VERSION ""

NS_ :

BS_:

BU_: TM

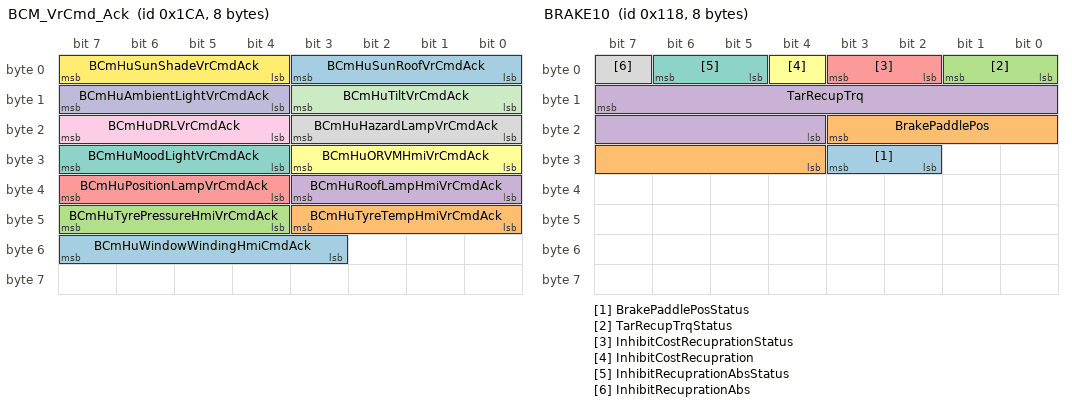
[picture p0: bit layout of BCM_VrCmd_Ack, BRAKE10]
BO_ 458 BCM_VrCmd_Ack: 8 Vector__XXX
 SG_ BCmHuWindowWindingHmiCmdAck : 55|5@0+ (1,0) [0|31] ""  TM
 SG_ BCmHuTyreTempHmiVrCmdAck : 43|4@0+ (1,0) [0|15] ""  TM
 SG_ BCmHuTyrePressureHmiVrCmdAck : 47|4@0+ (1,0) [0|15] ""  TM
 SG_ BCmHuRoofLampHmiVrCmdAck : 35|4@0+ (1,0) [0|15] ""  TM
 SG_ BCmHuPositionLampVrCmdAck : 39|4@0+ (1,0) [0|15] ""  TM
 SG_ BCmHuORVMHmiVrCmdAck : 27|4@0+ (1,0) [0|15] ""  TM
 SG_ BCmHuMoodLightVrCmdAck : 31|4@0+ (1,0) [0|15] ""  TM
 SG_ BCmHuHazardLampVrCmdAck : 19|4@0+ (1,0) [0|15] ""  TM
 SG_ BCmHuDRLVrCmdAck : 23|4@0+ (1,0) [0|15] ""  TM
 SG_ BCmHuAmbientLightVrCmdAck : 15|4@0+ (1,0) [0|15] ""  TM
 SG_ BCmHuTiltVrCmdAck : 11|4@0+ (1,0) [0|15] ""  TM
 SG_ BCmHuSunShadeVrCmdAck : 7|4@0+ (1,0) [0|15] ""  TM
 SG_ BCmHuSunRoofVrCmdAck : 3|4@0+ (1,0) [0|15] ""  TM

BO_ 2019 VCU_DiagRequest: 8 Vector__XXX
 SG_ VCU_DiagRequest : 7|64@0+ (1,0) [0|0] ""  TM

BO_ 2027 VCU_DiagResponse_USDT: 8 Vector__XXX
 SG_ VCU_DiagResponse_USDT : 7|64@0+ (1,0) [0|0] ""  TM

BO_ 567 BRAKE11_RC: 8 Vector__XXX
 SG_ MRC_3 : 51|4@0+ (1,0) [0|15] ""  TM
 SG_ CRC_3 : 63|8@0+ (1,0) [0|255] ""  TM
 SG_ ApbState_Old : 2|3@0+ (1,0) [0|7] ""  TM
 SG_ BrkPaddleTravel2Status : 26|2@0+ (1,0) [0|3] ""  TM
 SG_ BrkPaddleTravel2 : 24|9@0+ (0.01,0) [0|5] "volts"  TM
 SG_ MCMsAvailability : 12|1@0+ (1,0) [0|1] ""  TM
 SG_ BrkPaddleTravel1Status : 54|2@0+ (1,0) [0|3] ""  TM
 SG_ BrkPaddleTravel1 : 47|9@0+ (0.01,0) [0|5] "volts"  TM
 SG_ MCMsErrorState : 10|1@0+ (1,0) [0|1] ""  TM
 SG_ MCMsActive : 11|1@0+ (1,0) [0|1] ""  TM
 SG_ APbBeepState : 29|3@0+ (1,0) [0|7] ""  TM
 SG_ AVhStatus : 15|1@0+ (1,0) [0|1] ""  TM
 SG_ AVhState : 7|2@0+ (1,0) [0|3] ""  TM
 SG_ AVhAvailability : 14|1@0+ (1,0) [0|1] ""  TM
 SG_ APbState : 17|4@0+ (1,0) [0|15] ""  TM
 SG_ APbErrorState : 4|2@0+ (1,0) [0|3] ""  TM
 SG_ APbAvailability : 5|1@0+ (1,0) [0|1] ""  TM

BO_ 1397 FATC_to_BET: 8 Vector__XXX
 SG_ BET_Response : 7|64@0+ (1,0) [0|0] ""  TM

BO_ 1396 BET_to_FATC: 8 Vector__XXX
 SG_ BET_Request : 7|64@0+ (1,0) [0|0] ""  TM

BO_ 1395 FATC_to_VTOOL: 8 Vector__XXX
 SG_ Validation_Mode_Res : 7|64@0+ (1,0) [0|0] ""  TM

BO_ 1394 VTOOL_to_FATC: 8 Vector__XXX
 SG_ Validation_Mode_Req : 7|64@0+ (1,0) [0|0] ""  TM

BO_ 1393 FATC_to_XCP: 8 Vector__XXX
 SG_ XCP_DTO : 7|64@0+ (1,0) [0|0] ""  TM

BO_ 1392 XCP_to_FATC: 8 Vector__XXX
 SG_ XCP_CRO : 7|64@0+ (1,0) [0|0] ""  TM

BO_ 280 BRAKE10: 8 Vector__XXX
 SG_ BrakePaddlePosStatus : 27|2@0+ (1,0) [0|3] ""  TM
 SG_ BrakePaddlePos : 19|8@0+ (0.5,0) [0|100] "%"  TM
 SG_ TarRecupTrqStatus : 1|2@0+ (1,0) [0|3] ""  TM
 SG_ TarRecupTrq : 15|12@0+ (0.1,0) [0|250] ""  TM
 SG_ InhibitCostRecuprationStatus : 3|2@0+ (1,0) [0|3] ""  TM
 SG_ InhibitCostRecupration : 4|1@0+ (1,0) [0|1] ""  TM
 SG_ InhibitRecuprationAbsStatus : 6|2@0+ (1,0) [0|3] ""  TM
 SG_ InhibitRecuprationAbs : 7|1@0+ (1,0) [0|1] ""  TM

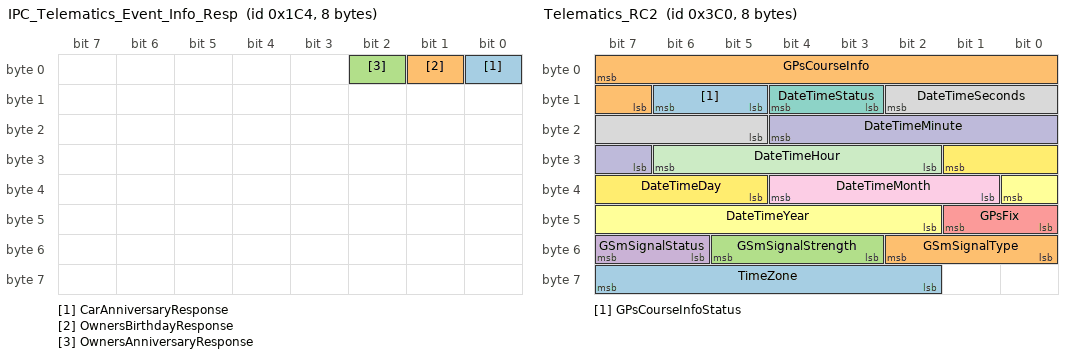
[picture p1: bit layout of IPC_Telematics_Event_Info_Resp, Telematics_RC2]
BO_ 452 IPC_Telematics_Event_Info_Resp: 8 Vector__XXX
 SG_ CarAnniversaryResponse : 0|1@0+ (1,0) [0|1] ""  TM
 SG_ OwnersBirthdayResponse : 1|1@0+ (1,0) [0|1] ""  TM
 SG_ OwnersAnniversaryResponse : 2|1@0+ (1,0) [0|1] ""  TM

BO_ 962 Telematics_GPSinfo_RC2: 8 TM
 SG_ GPsInfoY : 39|32@0+ (1E-007,-90) [-90|90] "deg" Vector__XXX
 SG_ GPsInfoX : 7|32@0+ (1E-007,-180) [-180|180] "deg" Vector__XXX

BO_ 963 Telematics_GPSinfo_RC7: 8 TM
 SG_ GPsInfoXYZStatus : 33|2@0+ (1,0) [0|3] "" Vector__XXX
 SG_ GPsInfoZ : 7|32@0+ (1,-10000000) [-10000000|10000000] "cm" Vector__XXX

BO_ 960 Telematics_RC2: 8 TM
 SG_ TimeZone : 63|6@0+ (1,0) [0|63] "" Vector__XXX
 SG_ GSmSignalType : 50|3@0+ (1,0) [0|7] "" Vector__XXX
 SG_ GSmSignalStrength : 53|3@0+ (1,0) [0|7] "" Vector__XXX
 SG_ GSmSignalStatus : 55|2@0+ (1,0) [0|3] "" Vector__XXX
 SG_ GPsFix : 41|2@0+ (1,0) [0|3] "" Vector__XXX
 SG_ DateTimeYear : 32|7@0+ (1,0) [0|99] "" Vector__XXX
 SG_ DateTimeStatus : 12|2@0+ (1,0) [0|3] "" Vector__XXX
 SG_ DateTimeSeconds : 10|6@0+ (1,0) [0|59] "" Vector__XXX
 SG_ DateTimeMonth : 36|4@0+ (1,0) [0|12] "" Vector__XXX
 SG_ DateTimeMinute : 20|6@0+ (1,0) [0|59] "" Vector__XXX
 SG_ DateTimeHour : 30|5@0+ (1,0) [0|24] "" Vector__XXX
 SG_ DateTimeDay : 25|5@0+ (1,0) [0|31] "" Vector__XXX
 SG_ GPsCourseInfoStatus : 14|2@0+ (1,0) [0|3] "" Vector__XXX
 SG_ GPsCourseInfo : 7|9@0+ (1,0) [0|360] "" Vector__XXX

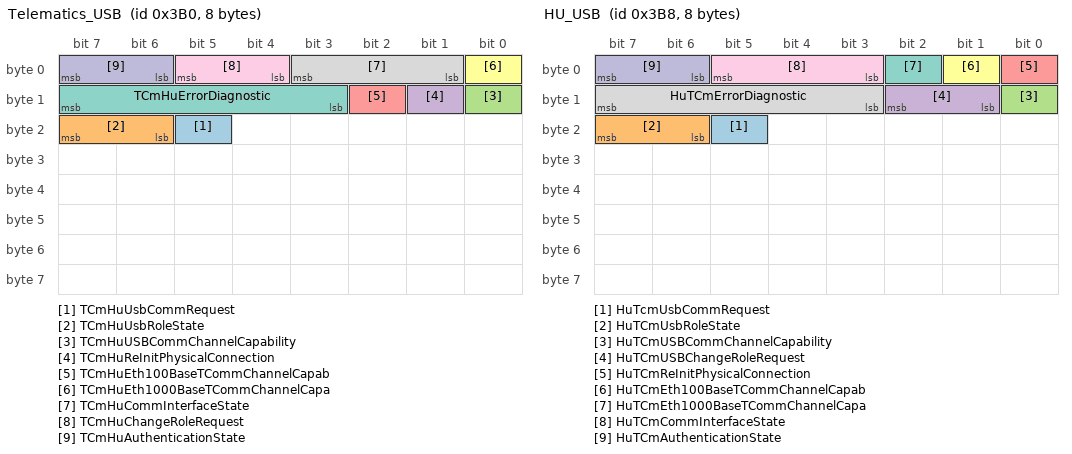
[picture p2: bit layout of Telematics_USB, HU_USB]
BO_ 944 Telematics_USB: 8 TM
 SG_ TCmHuUsbCommRequest : 21|1@0+ (1,0) [0|1] "" Vector__XXX
 SG_ TCmHuUsbRoleState : 23|2@0+ (1,0) [0|3] "" Vector__XXX
 SG_ TCmHuUSBCommChannelCapability : 8|1@0+ (1,0) [0|1] "" Vector__XXX
 SG_ TCmHuReInitPhysicalConnection : 9|1@0+ (1,0) [0|1] "" Vector__XXX
 SG_ TCmHuEth100BaseTCommChannelCapab : 10|1@0+ (1,0) [0|1] "" Vector__XXX
 SG_ TCmHuEth1000BaseTCommChannelCapa : 0|1@0+ (1,0) [0|1] "" Vector__XXX
 SG_ TCmHuErrorDiagnostic : 15|5@0+ (1,0) [0|31] "" Vector__XXX
 SG_ TCmHuCommInterfaceState : 3|3@0+ (1,0) [0|7] "" Vector__XXX
 SG_ TCmHuChangeRoleRequest : 5|2@0+ (1,0) [0|3] "" Vector__XXX
 SG_ TCmHuAuthenticationState : 7|2@0+ (1,0) [0|3] "" Vector__XXX

BO_ 952 HU_USB: 8 Vector__XXX
 SG_ HuTcmUsbCommRequest : 21|1@0+ (1,0) [0|1] ""  TM
 SG_ HuTCmUsbRoleState : 23|2@0+ (1,0) [0|3] ""  TM
 SG_ HuTCmUSBCommChannelCapability : 8|1@0+ (1,0) [0|1] ""  TM
 SG_ HuTCmUSBChangeRoleRequest : 10|2@0+ (1,0) [0|3] ""  TM
 SG_ HuTCmReInitPhysicalConnection : 0|1@0+ (1,0) [0|1] ""  TM
 SG_ HuTCmEth100BaseTCommChannelCapab : 1|1@0+ (1,0) [0|1] ""  TM
 SG_ HuTCmEth1000BaseTCommChannelCapa : 2|1@0+ (1,0) [0|1] ""  TM
 SG_ HuTCmErrorDiagnostic : 15|5@0+ (1,0) [0|31] ""  TM
 SG_ HuTCmCommInterfaceState : 5|3@0+ (1,0) [0|7] ""  TM
 SG_ HuTCmAuthenticationState : 7|2@0+ (1,0) [0|3] ""  TM

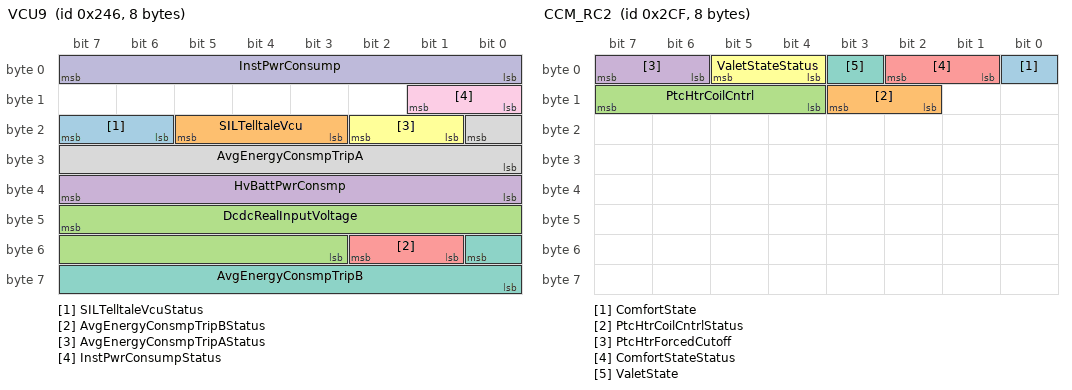
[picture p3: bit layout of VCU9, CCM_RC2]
BO_ 582 VCU9: 8 Vector__XXX
 SG_ SILTelltaleVcuStatus : 23|2@0+ (1,0) [0|3] ""  TM
 SG_ SILTelltaleVcu : 21|3@0+ (1,0) [0|7] ""  TM
 SG_ DcdcRealInputVoltage : 47|13@0+ (0.1,0) [0|819.1] "V"  TM
 SG_ HvBattPwrConsmp : 39|8@0+ (1,0) [0|250] "KwHr"  TM
 SG_ AvgEnergyConsmpTripBStatus : 50|2@0+ (1,0) [0|3] ""  TM
 SG_ AvgEnergyConsmpTripAStatus : 18|2@0+ (1,0) [0|3] ""  TM
 SG_ AvgEnergyConsmpTripB : 48|9@0+ (1,0) [0|511] "kwH/Km"  TM
 SG_ AvgEnergyConsmpTripA : 16|9@0+ (1,0) [0|511] "kwH/Km"  TM
 SG_ InstPwrConsumpStatus : 9|2@0+ (1,0) [0|3] ""  TM
 SG_ InstPwrConsump : 7|8@0+ (1,-100) [-100|100] "%"  TM

BO_ 1630 TPMS_DiagResponse_UUDT: 8 Vector__XXX
 SG_ TPMS_DiagResponse_UUDT : 7|64@0+ (1,0) [0|0] ""  TM

BO_ 1886 TPMS_DiagResponse_USDT: 8 Vector__XXX
 SG_ TPMS_DiagResponse_USDT : 7|64@0+ (1,0) [0|0] ""  TM

BO_ 1878 TPMS_DiagRequest: 8 Vector__XXX
 SG_ TPMS_DiagRequest : 7|64@0+ (1,0) [0|0] ""  TM

BO_ 1289 ESP_NMPDU: 8 Vector__XXX
 SG_ PreviousState_ESP : 19|3@0+ (1,0) [0|7] ""  TM
 SG_ Reserved63 : 20|1@0+ (1,0) [0|1] ""  TM
 SG_ Reserved62 : 21|1@0+ (1,0) [0|1] ""  TM
 SG_ Reserved61 : 22|1@0+ (1,0) [0|1] ""  TM
 SG_ Reserved60 : 23|1@0+ (1,0) [0|1] ""  TM
 SG_ Reserved59 : 9|1@0+ (1,0) [0|1] ""  TM
 SG_ Reserved58 : 10|1@0+ (1,0) [0|1] ""  TM
 SG_ Reserved57 : 13|1@0+ (1,0) [0|1] ""  TM
 SG_ Reserved56 : 15|1@0+ (1,0) [0|1] ""  TM
 SG_ RepeatMessageReq_ESP : 8|1@0+ (1,0) [0|1] ""  TM
 SG_ PartialNetworkInformation_ESP : 14|1@0+ (1,0) [0|1] ""  TM
 SG_ NMCoOrdSlpReady_ESP : 11|1@0+ (1,0) [0|1] ""  TM
 SG_ ESP_NMPDU_USER_DATA_D5 : 63|8@0+ (1,0) [0|255] ""  TM
 SG_ ESP_NMPDU_USER_DATA_D4 : 55|8@0+ (1,0) [0|255] ""  TM
 SG_ ESP_NMPDU_USER_DATA_D3 : 47|8@0+ (1,0) [0|255] ""  TM
 SG_ ESP_NMPDU_USER_DATA_D2 : 39|8@0+ (1,0) [0|255] ""  TM
 SG_ ESP_NMPDU_USER_DATA_D1 : 31|8@0+ (1,0) [0|255] ""  TM
 SG_ ESP_NMPDU_SRC_ECU_ID : 7|8@0+ (1,0) [0|255] ""  TM
 SG_ CurrentState_ESP : 16|1@0+ (1,0) [0|1] ""  TM
 SG_ ActiveWakeUp_ESP : 12|1@0+ (1,0) [0|1] ""  TM

BO_ 1772 SCU_DiagResponse_UUDT: 8 Vector__XXX
 SG_ SCU_DiagResponse_UUDT : 7|64@0+ (1,0) [0|0] ""  TM

BO_ 2028 SCU_DiagResponse_USDT: 8 Vector__XXX
 SG_ SCU_DiagResponse_USDT : 7|64@0+ (1,0) [0|0] ""  TM

BO_ 2020 SCU_DiagRequest: 8 Vector__XXX
 SG_ SCU_DiagRequest : 7|64@0+ (1,0) [0|0] ""  TM

BO_ 719 CCM_RC2: 8 Vector__XXX
 SG_ ComfortState : 0|1@0+ (1,0) [0|1] ""  TM
 SG_ PtcHtrCoilCntrlStatus : 11|2@0+ (1,0) [0|3] ""  TM
 SG_ PtcHtrCoilCntrl : 15|4@0+ (1,0) [0|15] ""  TM
 SG_ PtcHtrForcedCutoff : 7|2@0+ (1,0) [0|3] ""  TM
 SG_ ComfortStateStatus : 2|2@0+ (1,0) [0|3] ""  TM
 SG_ ValetStateStatus : 5|2@0+ (1,0) [0|3] ""  TM
 SG_ ValetState : 3|1@0+ (1,0) [0|1] ""  TM

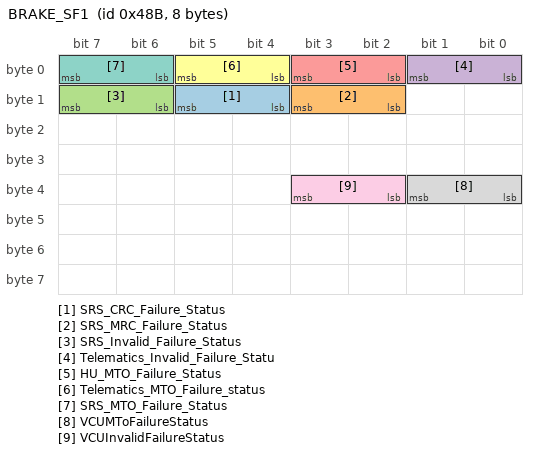
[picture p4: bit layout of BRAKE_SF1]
BO_ 1163 BRAKE_SF1: 8 Vector__XXX
 SG_ SRS_CRC_Failure_Status : 13|2@0+ (1,0) [0|3] ""  TM
 SG_ SRS_MRC_Failure_Status : 11|2@0+ (1,0) [0|3] ""  TM
 SG_ SRS_Invalid_Failure_Status : 15|2@0+ (1,0) [0|3] ""  TM
 SG_ Telematics_Invalid_Failure_Statu : 1|2@0+ (1,0) [0|3] ""  TM
 SG_ HU_MTO_Failure_Status : 3|2@0+ (1,0) [0|3] ""  TM
 SG_ Telematics_MTO_Failure_status : 5|2@0+ (1,0) [0|3] ""  TM
 SG_ SRS_MTO_Failure_Status : 7|2@0+ (1,0) [0|3] ""  TM
 SG_ VCUMToFailureStatus : 33|2@0+ (1,0) [0|3] ""  TM
 SG_ VCUInvalidFailureStatus : 35|2@0+ (1,0) [0|3] ""  TM

BO_ 1143 TM_EV_SF: 8 TM
 SG_ AMT_DCT_Invalid_Failure_Status : 45|2@0+ (1,0) [0|3] "" Vector__XXX
 SG_ EMsInvalidFailureStatus : 33|2@0+ (1,0) [0|3] "" Vector__XXX
 SG_ ESP_Invalid_Failure_Status : 37|2@0+ (1,0) [0|3] "" Vector__XXX
 SG_ AMT_DCT_MTO_Failure_Status : 47|2@0+ (1,0) [0|3] "" Vector__XXX
 SG_ TPMS_MTO_Failure_status : 43|2@0+ (1,0) [0|3] "" Vector__XXX
 SG_ SAS_MTO_Failure_Status : 41|2@0+ (1,0) [0|3] "" Vector__XXX
 SG_ EMS_MTO_Failure_Status : 35|2@0+ (1,0) [0|3] "" Vector__XXX
 SG_ ESP_MTO_Failure_Status : 39|2@0+ (1,0) [0|3] "" Vector__XXX
 SG_ BattVolt_TM : 63|8@0+ (0.1,0) [0|25] "v" Vector__XXX
 SG_ SRS_MTO_Failure_Status : 21|2@0+ (1,0) [0|3] "" Vector__XXX
 SG_ PEPS_MTO_Failure_Status : 17|2@0+ (1,0) [0|3] "" Vector__XXX
 SG_ PEPS_Invalid_failure_status : 19|2@0+ (1,0) [0|3] "" Vector__XXX
 SG_ IPcMToFailureStatus : 13|2@0+ (1,0) [0|3] "" Vector__XXX
 SG_ IPcInvalidFailureStatus : 15|2@0+ (1,0) [0|3] "" Vector__XXX
 SG_ ESClMToFailureStatus : 23|2@0+ (1,0) [0|3] "" Vector__XXX
 SG_ EPAS_MTO_Failure_Status : 9|2@0+ (1,0) [0|3] "" Vector__XXX
 SG_ EPAS_Invalid_Failure_Status : 11|2@0+ (1,0) [0|3] "" Vector__XXX
 SG_ CCM_MTO_Failure_Status : 5|2@0+ (1,0) [0|3] "" Vector__XXX
 SG_ CCM_Invalid_Failure_Status : 7|2@0+ (1,0) [0|3] "" Vector__XXX
 SG_ BCmMToFailureStatus : 1|2@0+ (1,0) [0|3] "" Vector__XXX
 SG_ BCmInvalidFailureStatus : 3|2@0+ (1,0) [0|3] "" Vector__XXX
 SG_ Telematics_SW_Version : 55|8@0+ (1,0) [0|255] "" Vector__XXX
 SG_ Telematics_EP_Failure_Status : 27|2@0+ (1,0) [0|3] "" Vector__XXX
 SG_ Telematics_BO_Failure_Status : 25|2@0+ (1,0) [0|3] "" Vector__XXX
 SG_ VCUInvalidFailureStatus : 29|2@0+ (1,0) [0|3] "" Vector__XXX
 SG_ VCUMToFailureStatus : 31|2@0+ (1,0) [0|3] "" Vector__XXX

CM_ SG_ 458 BCmHuWindowWindingHmiCmdAck "Window Winding state from BCM to HU















";
CM_ SG_ 458 BCmHuTyreTempHmiVrCmdAck "Tyre Temperature state from BCM to HU














";
CM_ SG_ 458 BCmHuTyrePressureHmiVrCmdAck "Tyre Pressure state from BCM to HU















";
CM_ SG_ 458 BCmHuRoofLampHmiVrCmdAck "Roof lamp state from BCM to HU

















";
CM_ SG_ 458 BCmHuPositionLampVrCmdAck "Position lamp state from BCM to HU";
CM_ SG_ 458 BCmHuORVMHmiVrCmdAck "ORVM state from BCM to HU
















";
CM_ SG_ 458 BCmHuMoodLightVrCmdAck "Mood Light state from BCM to HU";
CM_ SG_ 458 BCmHuHazardLampVrCmdAck "Hazard lamp state from BCM to HU";
CM_ SG_ 458 BCmHuDRLVrCmdAck "DRL state from BCM to HU";
CM_ SG_ 458 BCmHuAmbientLightVrCmdAck "Ambient Light state from BCM to HU";
CM_ SG_ 458 BCmHuTiltVrCmdAck "Sunroof Tilt state from BCM to HU";
CM_ SG_ 458 BCmHuSunShadeVrCmdAck "Sunshade state from BCM to HU";
CM_ SG_ 458 BCmHuSunRoofVrCmdAck "Sunroof state from BCM to HU";
CM_ SG_ 567 MRC_3 "Messgage counter for APbState signals";
CM_ SG_ 567 CRC_3 "CRC signal for APbState";
CM_ SG_ 567 ApbState_Old "status of APB system";
CM_ SG_ 567 BrkPaddleTravel2Status "Status signal of BrkPaddletravel signal";
CM_ SG_ 567 BrkPaddleTravel2 "Brake paddle travel sensor output voltage";
CM_ SG_ 567 MCMsAvailability "MCMs Function availability indication";
CM_ SG_ 567 BrkPaddleTravel1Status "Status signal of BrkPaddletravel signal";
CM_ SG_ 567 BrkPaddleTravel1 "Brake paddle travel sensor output voltage";
CM_ SG_ 567 MCMsErrorState "Status information of MCMS";
CM_ SG_ 567 MCMsActive "Indication that ESP system currently performs MCMS Intervention or not";
CM_ SG_ 567 APbBeepState "status of APB system";
CM_ SG_ 567 AVhStatus "status of AVH function";
CM_ SG_ 567 AVhState "state of AVH function";
CM_ SG_ 567 AVhAvailability "AVH function availability indication";
CM_ SG_ 567 APbState "status of APB system";
CM_ SG_ 567 APbErrorState "error indication of APB system";
CM_ SG_ 567 APbAvailability "APB function availability information";
CM_ SG_ 280 BrakePaddlePosStatus "status information of Brake paddle percentage signal";
CM_ SG_ 280 BrakePaddlePos "Brake paddle travel percentage shall be Transmissted  by iVBAC";
CM_ SG_ 280 TarRecupTrqStatus "Status signal of TarRegenTrq Signal";
CM_ SG_ 280 TarRecupTrq "Target Regen torque Value for VCU";
CM_ SG_ 280 InhibitCostRecuprationStatus "Costing Recupration Request Status";
CM_ SG_ 280 InhibitCostRecupration "costing Recupration Request";
CM_ SG_ 280 InhibitRecuprationAbsStatus "Recupration Request Status";
CM_ SG_ 280 InhibitRecuprationAbs "Recupration Request";
CM_ SG_ 452 CarAnniversaryResponse "It's the response from IPC to TCU for CarAnniversary display";
CM_ SG_ 452 OwnersBirthdayResponse "It's the response from IPC to TCU for HappyBirthday display";
CM_ SG_ 452 OwnersAnniversaryResponse "It's the response from IPC to TCU for HappyAnniversary display";
CM_ SG_ 962 GPsInfoY "TCU publishes GPS location data in  Y Co-ordinate";
CM_ SG_ 962 GPsInfoX "TCU publishes GPS location data in  X Co-ordinate";
CM_ SG_ 963 GPsInfoXYZStatus "Status of signal GPsInfo";
CM_ SG_ 963 GPsInfoZ "TCU publishes GPS location data in  Z Co-ordinate ";
CM_ SG_ 960 TimeZone "The time zone information from telematics.";
CM_ SG_ 960 GPsCourseInfoStatus "Status of signal GPsCourseInfo";
CM_ SG_ 960 GPsCourseInfo "This signal shall be published by TCU . It shall contain GPS Course angle info";
CM_ SG_ 944 TCmHuUsbCommRequest "TCm Hu Usb Comm Request";
CM_ SG_ 944 TCmHuUsbRoleState "This signal informs the state of TCM USB communication.";
CM_ SG_ 944 TCmHuUSBCommChannelCapability "TCM sends this signal to HU to inform its USB communication channel availability.";
CM_ SG_ 944 TCmHuReInitPhysicalConnection "TCM sends this sgnal to request for physical connection reinitiation.";
CM_ SG_ 944 TCmHuEth100BaseTCommChannelCapab "TCM sends this signal to HU to inform its 100Base Ethernet communication channel availability.";
CM_ SG_ 944 TCmHuEth1000BaseTCommChannelCapa "TCM sends this signal to HU to inform its 1000Base Ethernet communication channel availability";
CM_ SG_ 944 TCmHuErrorDiagnostic "Signal informs HU about TCM error codes.";
CM_ SG_ 944 TCmHuCommInterfaceState "If TCM profile is ideal, this isgnal is consumed by HU to check if communication can be established";
CM_ SG_ 944 TCmHuChangeRoleRequest "TCM sends this signal to request the state of HU communication if not found ideal.";
CM_ SG_ 944 TCmHuAuthenticationState "Signal informs the TCM authentication state.";
CM_ SG_ 952 HuTcmUsbCommRequest "Hu Tcm Usb Comm Request";
CM_ SG_ 952 HuTCmUsbRoleState "This signal informs the state of HU USB communication.";
CM_ SG_ 952 HuTCmUSBCommChannelCapability "HU sends this signal to TCM to inform its USB communication channel availability.";
CM_ SG_ 952 HuTCmUSBChangeRoleRequest "HU sends this signal to request the state of HU communication if not found ideal.";
CM_ SG_ 952 HuTCmReInitPhysicalConnection "HU sends this signal to request for physical connection reinitiation.";
CM_ SG_ 952 HuTCmEth100BaseTCommChannelCapab "HU sends this signal to TCM to inform its 100Base Ethernet communication channel availability.";
CM_ SG_ 952 HuTCmEth1000BaseTCommChannelCapa "HU sends this signal to TCM to inform its 1000Base Ethernet communication channel availability.";
CM_ SG_ 952 HuTCmErrorDiagnostic "Signal informs TCM about HU error codes.";
CM_ SG_ 952 HuTCmCommInterfaceState "If HU profile is ideal, this isgnal is consumed by TCM to check if communication can be established";
CM_ SG_ 952 HuTCmAuthenticationState "Signal informs the HU authentication state.";
CM_ SG_ 582 SILTelltaleVcuStatus "status of Service Indicator Lamp telltale from VCU";
CM_ SG_ 582 SILTelltaleVcu "Service Indicator Lamp telltale from VCU";
CM_ SG_ 582 DcdcRealInputVoltage "DCDC_VCU_38E( signal name at PT side)
Voltage after the HV Battery Contactor";
CM_ SG_ 582 HvBattPwrConsmp "HV Battery Power Consumption";
CM_ SG_ 582 AvgEnergyConsmpTripBStatus "Average Energy Consumption for Trip B Status";
CM_ SG_ 582 AvgEnergyConsmpTripAStatus "Average Energy Consumption for Trip A Status";
CM_ SG_ 582 AvgEnergyConsmpTripB "Average Energy Consumption for Trip B";
CM_ SG_ 582 AvgEnergyConsmpTripA "Average Energy Consumption for Trip A";
CM_ SG_ 582 InstPwrConsumpStatus "Instantaneous Power Consumption Status";
CM_ SG_ 582 InstPwrConsump "Instantaneous Power Consumption";
CM_ BO_ 1630 "Diag UUDT Response";
CM_ BO_ 1886 "USDT Diag Response";
CM_ BO_ 1878 "Diag Request";
CM_ SG_ 1878 TPMS_DiagRequest "Diag Request Signal";
CM_ SG_ 719 ComfortState "Set temperature reached information as published by FATC to Tcu";
CM_ SG_ 719 PtcHtrCoilCntrlStatus "Plausibility of PTC heater relay input signal.";
CM_ SG_ 719 PtcHtrCoilCntrl "The switching ON/OFF of particular PTC coil in a multistage PTC heater to be decided based on this signal.
This Signal is a Bit Mapped signal and the individual coil will become ON/OFF according to its Bit Value.";
CM_ SG_ 719 PtcHtrForcedCutoff "This signal shall be used as a master control signal for PTC driving. ";
CM_ SG_ 719 ComfortStateStatus "Status signal of Set temperature reached information as published by FATC to Tcu";
CM_ SG_ 719 ValetStateStatus "ValetStateStatus signlal published by FATC";
CM_ SG_ 719 ValetState "ValetState as Published by FATC";
CM_ BO_ 1163 "Supervsion frame transmitted by ABS EV ECU";
CM_ SG_ 1163 SRS_Invalid_Failure_Status "status of the SRS Invalid  signal  failure detected as per Tata-IVN_Specification_Network_Management.";
CM_ SG_ 1163 Telematics_Invalid_Failure_Statu "Status of the Telematics Invalid failure detected as per Tata-IVN_Specification_Network_Management.";
CM_ SG_ 1163 HU_MTO_Failure_Status "Status of the HU Message timeout failure detected as per Tata-IVN_Specification_Network_Management.";
CM_ SG_ 1163 Telematics_MTO_Failure_status "Status of the Telematics Message timeout failure detected as per Tata-IVN_Specification_Network_Management.";
CM_ SG_ 1163 SRS_MTO_Failure_Status "Status of the SRS  Message timeout  failure detected as per Tata-IVN_Specification_Network_Management.";
CM_ SG_ 1163 VCUMToFailureStatus "VCUMTO failure status";
CM_ SG_ 1163 VCUInvalidFailureStatus "VCU invalid failure status";
CM_ BO_ 1143 "Supervision frame transmitted by Telematics Control Unit EV.";
CM_ SG_ 1143 AMT_DCT_Invalid_Failure_Status "Status of the TM invalid failure detected as per Tata-IVN_Specification_Network_Management.";
CM_ SG_ 1143 EMsInvalidFailureStatus "status of the EMS Invalid  signal  failure detected as per Tata-IVN_Specification_Network_Management.";
CM_ SG_ 1143 ESP_Invalid_Failure_Status "Status of the ESP signal implausible  failure detected  by EPAS  as per  communication layer spec";
CM_ SG_ 1143 AMT_DCT_MTO_Failure_Status "Status of the AMT Message Timeout  failure detected as per Tata-IVN_Specification_Network_Management.";
CM_ SG_ 1143 TPMS_MTO_Failure_status "Message timeout failure flag against TPMS ECU";
CM_ SG_ 1143 SAS_MTO_Failure_Status "Status of the SAS  Message timeout  failure detected as per Tata-IVN_Specification_Network_Management.";
CM_ SG_ 1143 EMS_MTO_Failure_Status "Status of the EMS message timeout failure detected as per Tata-IVN_Specification_Network_Management.";
CM_ SG_ 1143 ESP_MTO_Failure_Status "Status of the ESP  Message timeout failure detected as per Tata-IVN_Specification_Network_Management.";
CM_ SG_ 1143 BattVolt_TM "Battery voltage evaluated by TM

";
CM_ SG_ 1143 SRS_MTO_Failure_Status "Status of the SRS  Message timeout  failure detected as per Tata-IVN_Specification_Network_Management.";
CM_ SG_ 1143 PEPS_MTO_Failure_Status "Status of the PEPS  Message timeout  failure detected as per Tata-IVN_Specification_Network_Management.";
CM_ SG_ 1143 PEPS_Invalid_failure_status "Status of the PEPS invalid failure detected as per Tata-IVN_Specification_Network_Management.";
CM_ SG_ 1143 IPcMToFailureStatus "Status of the IPC Message Timeout  failure detected as per Tata-IVN_Specification_Network_Management.";
CM_ SG_ 1143 IPcInvalidFailureStatus "Status of the IC Invalid  signal  failure detected as per Tata-IVN_Specification_Network_Management.";
CM_ SG_ 1143 ESClMToFailureStatus "ESCL Message Time Out Failure Status";
CM_ SG_ 1143 EPAS_MTO_Failure_Status "Status of the EPAS  Message timeout failure detected as per Tata-IVN_Specification_Network_Management.";
CM_ SG_ 1143 EPAS_Invalid_Failure_Status "Status of the EPAS signal implausible  failure detected    as per  communication layer spec";
CM_ SG_ 1143 CCM_MTO_Failure_Status "Status of the FATC Message timeout failure detected as per Tata-IVN_Specification_Network_Management.";
CM_ SG_ 1143 CCM_Invalid_Failure_Status "Status of the  FATC Invalid  signal  failure detected as per Tata-IVN_Specification_Network_Management.";
CM_ SG_ 1143 BCmMToFailureStatus "Status of the BCM Message timeout  failure detected as per Tata-IVN_Specification_Network_Management.";
CM_ SG_ 1143 BCmInvalidFailureStatus "BCM Invalid Failure Status";
CM_ SG_ 1143 Telematics_SW_Version "SW version of TCU_EV ECU.
";
CM_ SG_ 1143 Telematics_EP_Failure_Status "Status of the error-passive failure detected by TCU_EV ECU as per Tata-IVN_Specification_Network_Management.
";
CM_ SG_ 1143 Telematics_BO_Failure_Status "Status of the bus-off failure detected by TCU_EV ECU as per Tata-IVN_Specification_Network_Management.

";
CM_ SG_ 1143 VCUInvalidFailureStatus "VCU invalid failure status";
CM_ SG_ 1143 VCUMToFailureStatus "VCUMTO failure status";
BA_DEF_ SG_  "Remarks" STRING ;
BA_DEF_ SG_  "NWM_WakeupAllowed" ENUM  "No","Yes";
BA_DEF_ SG_  "GenSigTimeoutTime_HU_Mid_X451" INT 0 65535;
BA_DEF_ SG_  "GenSigTimeoutTime_HU_High_X451" INT 0 65535;
BA_DEF_ SG_  "GenSigTimeoutTime_HU_B" INT 0 65535;
BA_DEF_ SG_  "GenSigTimeoutTime_HU_A" INT 0 65535;
BA_DEF_ SG_  "GenSigTimeoutTime_BCM_Mid" INT 0 65535;
BA_DEF_ SG_  "GenSigTimeoutMsg_HU_Mid_X451" INT 0 65535;
BA_DEF_ SG_  "GenSigTimeoutMsg_HU_High_X451" INT 0 65535;
BA_DEF_ SG_  "GenSigTimeoutMsg_HU_B" INT 0 65535;
BA_DEF_ SG_  "GenSigTimeoutMsg_HU_A" INT 0 65535;
BA_DEF_ SG_  "GenSigStartValue" INT 0 0;
BA_DEF_ SG_  "GenSigSendType" ENUM  "Cyclic","OnWrite","OnWriteWithRepetition","OnChange","OnChangeWithRepetition","IfActive","IfActiveWithRepetition","NoSigSendType","NotUsed","NotUsed","NotUsed","NotUsed","NotUsed";
BA_DEF_ SG_  "GenSigInactiveValue" INT 0 0;
BA_DEF_ SG_  "GenSigEnvVarType" ENUM  "int","float","undef";
BA_DEF_ SG_  "GenSigCycleTimeActive" INT 0 0;
BA_DEF_ SG_  "GenSigCycleTime" INT 0 0;
BA_DEF_ SG_  "GenSigTimeoutMsg_HU_High_X445" INT 0 65535;
BA_DEF_ SG_  "GenSigTimeoutMsg_HU_Mid_X445" INT 0 65535;
BA_DEF_ SG_  "GenSigTimeoutTime_HU_High_X445" INT 0 65535;
BA_DEF_ SG_  "GenSigTimeoutTime_HU_Mid_X445" INT 0 65535;
BA_DEF_ SG_  "GenSigTimeoutMsg_IVI" INT 0 65535;
BA_DEF_ SG_  "GenSigTimeoutTime_IVI" INT 0 65535;
BA_DEF_ BO_  "NmMessage" ENUM  "no","yes";
BA_DEF_ BO_  "NmAsrMessage" ENUM  "<n.a.>","No","Yes";
BA_DEF_ BO_  "MessageTimeout" INT 0 65535;
BA_DEF_ BO_  "Me" INT 0 0;
BA_DEF_ BO_  "GenMsgStartDelayTime" INT 0 0;
BA_DEF_ BO_  "GenMsgSendType" ENUM  "Cyclic","NotUsed","NotUsed","NotUsed","NotUsed","NotUsed","NotUsed","IfActive","NoMsgSendType","NotUsed";
BA_DEF_ BO_  "GenMsgNrOfRepetition" INT 0 0;
BA_DEF_ BO_  "GenMsgILSupport" ENUM  "No","Yes";
BA_DEF_ BO_  "GenMsgDelayTime" INT 0 0;
BA_DEF_ BO_  "GenMsgCycleTimeFast" INT 0 0;
BA_DEF_ BO_  "GenMsgCycleTime" INT 0 0;
BA_DEF_ BO_  "DiagUudtResponse" ENUM  "false","true";
BA_DEF_ BO_  "DiagUsdtResponse" ENUM  "false","true";
BA_DEF_ BO_  "DiagState" ENUM  "No","Yes";
BA_DEF_ BO_  "DiagResponse" ENUM  "No","Yes";
BA_DEF_ BO_  "DiagRequest" ENUM  "No","Yes";
BA_DEF_ BO_  "MsgType" ENUM  "Application","NM","NMH";
BA_DEF_ SG_  "SystemSignalLongSymbol" STRING ;
BA_DEF_DEF_  "Remarks" "null";
BA_DEF_DEF_  "NWM_WakeupAllowed" "No";
BA_DEF_DEF_  "GenSigTimeoutTime_HU_Mid_X451" 500;
BA_DEF_DEF_  "GenSigTimeoutTime_HU_High_X451" 500;
BA_DEF_DEF_  "GenSigTimeoutTime_HU_B" 500;
BA_DEF_DEF_  "GenSigTimeoutTime_HU_A" 500;
BA_DEF_DEF_  "GenSigTimeoutTime_BCM_Mid" 0;
BA_DEF_DEF_  "GenSigTimeoutMsg_HU_Mid_X451" 500;
BA_DEF_DEF_  "GenSigTimeoutMsg_HU_High_X451" 500;
BA_DEF_DEF_  "GenSigTimeoutMsg_HU_B" 500;
BA_DEF_DEF_  "GenSigTimeoutMsg_HU_A" 500;
BA_DEF_DEF_  "GenSigStartValue" 0;
BA_DEF_DEF_  "GenSigSendType" "Cyclic";
BA_DEF_DEF_  "GenSigInactiveValue" 0;
BA_DEF_DEF_  "GenSigEnvVarType" "undef";
BA_DEF_DEF_  "GenSigCycleTimeActive" 0;
BA_DEF_DEF_  "GenSigCycleTime" 0;
BA_DEF_DEF_  "GenSigTimeoutMsg_HU_High_X445" 500;
BA_DEF_DEF_  "GenSigTimeoutMsg_HU_Mid_X445" 500;
BA_DEF_DEF_  "GenSigTimeoutTime_HU_High_X445" 500;
BA_DEF_DEF_  "GenSigTimeoutTime_HU_Mid_X445" 500;
BA_DEF_DEF_  "GenSigTimeoutMsg_IVI" 500;
BA_DEF_DEF_  "GenSigTimeoutTime_IVI" 500;
BA_DEF_DEF_  "NmMessage" "no";
BA_DEF_DEF_  "NmAsrMessage" "<n.a.>";
BA_DEF_DEF_  "MessageTimeout" 500;
BA_DEF_DEF_  "Me" 0;
BA_DEF_DEF_  "GenMsgStartDelayTime" 0;
BA_DEF_DEF_  "GenMsgSendType" "Cyclic";
BA_DEF_DEF_  "GenMsgNrOfRepetition" 0;
BA_DEF_DEF_  "GenMsgILSupport" "Yes";
BA_DEF_DEF_  "GenMsgDelayTime" 0;
BA_DEF_DEF_  "GenMsgCycleTimeFast" 0;
BA_DEF_DEF_  "GenMsgCycleTime" 0;
BA_DEF_DEF_  "DiagUudtResponse" "false";
BA_DEF_DEF_  "DiagUsdtResponse" "false";
BA_DEF_DEF_  "DiagState" "No";
BA_DEF_DEF_  "DiagResponse" "No";
BA_DEF_DEF_  "DiagRequest" "No";
BA_DEF_DEF_  "MsgType" "Application";
BA_DEF_DEF_  "SystemSignalLongSymbol" "";
BA_ "MessageTimeout" BO_ 458 0;
BA_ "GenMsgSendType" BO_ 458 8;
BA_ "GenMsgNrOfRepetition" BO_ 458 3;
BA_ "GenMsgDelayTime" BO_ 458 500;
BA_ "GenMsgCycleTimeFast" BO_ 458 500;
BA_ "MessageTimeout" BO_ 2019 0;
BA_ "GenMsgSendType" BO_ 2019 8;
BA_ "GenMsgILSupport" BO_ 2019 0;
BA_ "DiagRequest" BO_ 2019 1;
BA_ "MessageTimeout" BO_ 2027 0;
BA_ "GenMsgSendType" BO_ 2027 8;
BA_ "GenMsgILSupport" BO_ 2027 0;
BA_ "DiagResponse" BO_ 2027 1;
BA_ "GenMsgCycleTime" BO_ 567 50;
BA_ "MessageTimeout" BO_ 1397 0;
BA_ "GenMsgSendType" BO_ 1397 8;
BA_ "GenMsgILSupport" BO_ 1397 0;
BA_ "MessageTimeout" BO_ 1396 0;
BA_ "GenMsgSendType" BO_ 1396 8;
BA_ "GenMsgILSupport" BO_ 1396 0;
BA_ "MessageTimeout" BO_ 1395 0;
BA_ "GenMsgSendType" BO_ 1395 8;
BA_ "GenMsgILSupport" BO_ 1395 0;
BA_ "MessageTimeout" BO_ 1394 0;
BA_ "GenMsgSendType" BO_ 1394 8;
BA_ "GenMsgILSupport" BO_ 1394 0;
BA_ "MessageTimeout" BO_ 1393 0;
BA_ "GenMsgSendType" BO_ 1393 8;
BA_ "GenMsgILSupport" BO_ 1393 0;
BA_ "MessageTimeout" BO_ 1392 0;
BA_ "GenMsgSendType" BO_ 1392 8;
BA_ "GenMsgILSupport" BO_ 1392 0;
BA_ "GenMsgCycleTime" BO_ 280 10;
BA_ "MessageTimeout" BO_ 452 0;
BA_ "GenMsgSendType" BO_ 452 8;
BA_ "MessageTimeout" BO_ 962 2500;
BA_ "GenMsgCycleTime" BO_ 962 500;
BA_ "MessageTimeout" BO_ 963 2500;
BA_ "GenMsgCycleTime" BO_ 963 500;
BA_ "MessageTimeout" BO_ 960 2500;
BA_ "GenMsgCycleTime" BO_ 960 500;
BA_ "MessageTimeout" BO_ 944 2500;
BA_ "GenMsgCycleTime" BO_ 944 500;
BA_ "MessageTimeout" BO_ 952 2500;
BA_ "GenMsgCycleTime" BO_ 952 500;
BA_ "GenMsgCycleTime" BO_ 582 100;
BA_ "MessageTimeout" BO_ 1630 0;
BA_ "GenMsgSendType" BO_ 1630 8;
BA_ "GenMsgILSupport" BO_ 1630 0;
BA_ "DiagResponse" BO_ 1630 1;
BA_ "MessageTimeout" BO_ 1886 0;
BA_ "GenMsgSendType" BO_ 1886 8;
BA_ "GenMsgILSupport" BO_ 1886 0;
BA_ "DiagResponse" BO_ 1886 1;
BA_ "MessageTimeout" BO_ 1878 0;
BA_ "GenMsgSendType" BO_ 1878 8;
BA_ "GenMsgILSupport" BO_ 1878 0;
BA_ "DiagRequest" BO_ 1878 1;
BA_ "MessageTimeout" BO_ 1289 1000;
BA_ "GenMsgCycleTime" BO_ 1289 200;
BA_ "MessageTimeout" BO_ 1772 0;
BA_ "GenMsgSendType" BO_ 1772 8;
BA_ "GenMsgILSupport" BO_ 1772 0;
BA_ "DiagResponse" BO_ 1772 1;
BA_ "MessageTimeout" BO_ 2028 0;
BA_ "GenMsgSendType" BO_ 2028 8;
BA_ "GenMsgILSupport" BO_ 2028 0;
BA_ "DiagResponse" BO_ 2028 1;
BA_ "MessageTimeout" BO_ 2020 0;
BA_ "GenMsgSendType" BO_ 2020 8;
BA_ "GenMsgILSupport" BO_ 2020 0;
BA_ "DiagRequest" BO_ 2020 1;
BA_ "GenMsgCycleTime" BO_ 719 100;
BA_ "MessageTimeout" BO_ 1163 0;
BA_ "GenMsgCycleTime" BO_ 1163 100;
BA_ "MessageTimeout" BO_ 1143 0;
BA_ "GenMsgCycleTime" BO_ 1143 100;
BA_ "GenSigTimeoutTime_HU_Mid_X451" SG_ 458 BCmHuWindowWindingHmiCmdAck 0;
BA_ "GenSigTimeoutTime_HU_High_X451" SG_ 458 BCmHuWindowWindingHmiCmdAck 0;
BA_ "GenSigTimeoutTime_HU_B" SG_ 458 BCmHuWindowWindingHmiCmdAck 0;
BA_ "GenSigTimeoutTime_HU_A" SG_ 458 BCmHuWindowWindingHmiCmdAck 0;
BA_ "GenSigTimeoutMsg_HU_Mid_X451" SG_ 458 BCmHuWindowWindingHmiCmdAck 0;
BA_ "GenSigTimeoutMsg_HU_High_X451" SG_ 458 BCmHuWindowWindingHmiCmdAck 0;
BA_ "GenSigTimeoutMsg_HU_B" SG_ 458 BCmHuWindowWindingHmiCmdAck 0;
BA_ "GenSigTimeoutMsg_HU_A" SG_ 458 BCmHuWindowWindingHmiCmdAck 0;
BA_ "GenSigSendType" SG_ 458 BCmHuWindowWindingHmiCmdAck 2;
BA_ "GenSigTimeoutMsg_HU_High_X445" SG_ 458 BCmHuWindowWindingHmiCmdAck 0;
BA_ "GenSigTimeoutMsg_HU_Mid_X445" SG_ 458 BCmHuWindowWindingHmiCmdAck 0;
BA_ "GenSigTimeoutTime_HU_High_X445" SG_ 458 BCmHuWindowWindingHmiCmdAck 0;
BA_ "GenSigTimeoutTime_HU_Mid_X445" SG_ 458 BCmHuWindowWindingHmiCmdAck 0;
BA_ "GenSigTimeoutMsg_IVI" SG_ 458 BCmHuWindowWindingHmiCmdAck 0;
BA_ "GenSigTimeoutTime_IVI" SG_ 458 BCmHuWindowWindingHmiCmdAck 0;
BA_ "GenSigTimeoutTime_HU_Mid_X451" SG_ 458 BCmHuTyreTempHmiVrCmdAck 0;
BA_ "GenSigTimeoutTime_HU_High_X451" SG_ 458 BCmHuTyreTempHmiVrCmdAck 0;
BA_ "GenSigTimeoutTime_HU_B" SG_ 458 BCmHuTyreTempHmiVrCmdAck 0;
BA_ "GenSigTimeoutTime_HU_A" SG_ 458 BCmHuTyreTempHmiVrCmdAck 0;
BA_ "GenSigTimeoutMsg_HU_Mid_X451" SG_ 458 BCmHuTyreTempHmiVrCmdAck 0;
BA_ "GenSigTimeoutMsg_HU_High_X451" SG_ 458 BCmHuTyreTempHmiVrCmdAck 0;
BA_ "GenSigTimeoutMsg_HU_B" SG_ 458 BCmHuTyreTempHmiVrCmdAck 0;
BA_ "GenSigTimeoutMsg_HU_A" SG_ 458 BCmHuTyreTempHmiVrCmdAck 0;
BA_ "GenSigSendType" SG_ 458 BCmHuTyreTempHmiVrCmdAck 2;
BA_ "GenSigTimeoutMsg_HU_High_X445" SG_ 458 BCmHuTyreTempHmiVrCmdAck 0;
BA_ "GenSigTimeoutMsg_HU_Mid_X445" SG_ 458 BCmHuTyreTempHmiVrCmdAck 0;
BA_ "GenSigTimeoutTime_HU_High_X445" SG_ 458 BCmHuTyreTempHmiVrCmdAck 0;
BA_ "GenSigTimeoutTime_HU_Mid_X445" SG_ 458 BCmHuTyreTempHmiVrCmdAck 0;
BA_ "GenSigTimeoutMsg_IVI" SG_ 458 BCmHuTyreTempHmiVrCmdAck 0;
BA_ "GenSigTimeoutTime_IVI" SG_ 458 BCmHuTyreTempHmiVrCmdAck 0;
BA_ "GenSigTimeoutTime_HU_Mid_X451" SG_ 458 BCmHuTyrePressureHmiVrCmdAck 0;
BA_ "GenSigTimeoutTime_HU_High_X451" SG_ 458 BCmHuTyrePressureHmiVrCmdAck 0;
BA_ "GenSigTimeoutTime_HU_B" SG_ 458 BCmHuTyrePressureHmiVrCmdAck 0;
BA_ "GenSigTimeoutTime_HU_A" SG_ 458 BCmHuTyrePressureHmiVrCmdAck 0;
BA_ "GenSigTimeoutMsg_HU_Mid_X451" SG_ 458 BCmHuTyrePressureHmiVrCmdAck 0;
BA_ "GenSigTimeoutMsg_HU_High_X451" SG_ 458 BCmHuTyrePressureHmiVrCmdAck 0;
BA_ "GenSigTimeoutMsg_HU_B" SG_ 458 BCmHuTyrePressureHmiVrCmdAck 0;
BA_ "GenSigTimeoutMsg_HU_A" SG_ 458 BCmHuTyrePressureHmiVrCmdAck 0;
BA_ "GenSigSendType" SG_ 458 BCmHuTyrePressureHmiVrCmdAck 2;
BA_ "GenSigTimeoutMsg_HU_High_X445" SG_ 458 BCmHuTyrePressureHmiVrCmdAck 0;
BA_ "GenSigTimeoutMsg_HU_Mid_X445" SG_ 458 BCmHuTyrePressureHmiVrCmdAck 0;
BA_ "GenSigTimeoutTime_HU_High_X445" SG_ 458 BCmHuTyrePressureHmiVrCmdAck 0;
BA_ "GenSigTimeoutTime_HU_Mid_X445" SG_ 458 BCmHuTyrePressureHmiVrCmdAck 0;
BA_ "GenSigTimeoutMsg_IVI" SG_ 458 BCmHuTyrePressureHmiVrCmdAck 0;
BA_ "GenSigTimeoutTime_IVI" SG_ 458 BCmHuTyrePressureHmiVrCmdAck 0;
BA_ "GenSigTimeoutTime_HU_Mid_X451" SG_ 458 BCmHuRoofLampHmiVrCmdAck 0;
BA_ "GenSigTimeoutTime_HU_High_X451" SG_ 458 BCmHuRoofLampHmiVrCmdAck 0;
BA_ "GenSigTimeoutTime_HU_B" SG_ 458 BCmHuRoofLampHmiVrCmdAck 0;
BA_ "GenSigTimeoutTime_HU_A" SG_ 458 BCmHuRoofLampHmiVrCmdAck 0;
BA_ "GenSigTimeoutMsg_HU_Mid_X451" SG_ 458 BCmHuRoofLampHmiVrCmdAck 0;
BA_ "GenSigTimeoutMsg_HU_High_X451" SG_ 458 BCmHuRoofLampHmiVrCmdAck 0;
BA_ "GenSigTimeoutMsg_HU_B" SG_ 458 BCmHuRoofLampHmiVrCmdAck 0;
BA_ "GenSigTimeoutMsg_HU_A" SG_ 458 BCmHuRoofLampHmiVrCmdAck 0;
BA_ "GenSigSendType" SG_ 458 BCmHuRoofLampHmiVrCmdAck 2;
BA_ "GenSigTimeoutMsg_HU_High_X445" SG_ 458 BCmHuRoofLampHmiVrCmdAck 0;
BA_ "GenSigTimeoutMsg_HU_Mid_X445" SG_ 458 BCmHuRoofLampHmiVrCmdAck 0;
BA_ "GenSigTimeoutTime_HU_High_X445" SG_ 458 BCmHuRoofLampHmiVrCmdAck 0;
BA_ "GenSigTimeoutTime_HU_Mid_X445" SG_ 458 BCmHuRoofLampHmiVrCmdAck 0;
BA_ "GenSigTimeoutMsg_IVI" SG_ 458 BCmHuRoofLampHmiVrCmdAck 0;
BA_ "GenSigTimeoutTime_IVI" SG_ 458 BCmHuRoofLampHmiVrCmdAck 0;
BA_ "GenSigTimeoutTime_HU_Mid_X451" SG_ 458 BCmHuPositionLampVrCmdAck 0;
BA_ "GenSigTimeoutTime_HU_High_X451" SG_ 458 BCmHuPositionLampVrCmdAck 0;
BA_ "GenSigTimeoutTime_HU_B" SG_ 458 BCmHuPositionLampVrCmdAck 0;
BA_ "GenSigTimeoutTime_HU_A" SG_ 458 BCmHuPositionLampVrCmdAck 0;
BA_ "GenSigTimeoutMsg_HU_Mid_X451" SG_ 458 BCmHuPositionLampVrCmdAck 0;
BA_ "GenSigTimeoutMsg_HU_High_X451" SG_ 458 BCmHuPositionLampVrCmdAck 0;
BA_ "GenSigTimeoutMsg_HU_B" SG_ 458 BCmHuPositionLampVrCmdAck 0;
BA_ "GenSigTimeoutMsg_HU_A" SG_ 458 BCmHuPositionLampVrCmdAck 0;
BA_ "GenSigSendType" SG_ 458 BCmHuPositionLampVrCmdAck 2;
BA_ "GenSigTimeoutMsg_HU_High_X445" SG_ 458 BCmHuPositionLampVrCmdAck 0;
BA_ "GenSigTimeoutMsg_HU_Mid_X445" SG_ 458 BCmHuPositionLampVrCmdAck 0;
BA_ "GenSigTimeoutTime_HU_High_X445" SG_ 458 BCmHuPositionLampVrCmdAck 0;
BA_ "GenSigTimeoutTime_HU_Mid_X445" SG_ 458 BCmHuPositionLampVrCmdAck 0;
BA_ "GenSigTimeoutMsg_IVI" SG_ 458 BCmHuPositionLampVrCmdAck 0;
BA_ "GenSigTimeoutTime_IVI" SG_ 458 BCmHuPositionLampVrCmdAck 0;
BA_ "GenSigTimeoutTime_HU_Mid_X451" SG_ 458 BCmHuORVMHmiVrCmdAck 0;
BA_ "GenSigTimeoutTime_HU_High_X451" SG_ 458 BCmHuORVMHmiVrCmdAck 0;
BA_ "GenSigTimeoutTime_HU_B" SG_ 458 BCmHuORVMHmiVrCmdAck 0;
BA_ "GenSigTimeoutTime_HU_A" SG_ 458 BCmHuORVMHmiVrCmdAck 0;
BA_ "GenSigTimeoutMsg_HU_Mid_X451" SG_ 458 BCmHuORVMHmiVrCmdAck 0;
BA_ "GenSigTimeoutMsg_HU_High_X451" SG_ 458 BCmHuORVMHmiVrCmdAck 0;
BA_ "GenSigTimeoutMsg_HU_B" SG_ 458 BCmHuORVMHmiVrCmdAck 0;
BA_ "GenSigTimeoutMsg_HU_A" SG_ 458 BCmHuORVMHmiVrCmdAck 0;
BA_ "GenSigSendType" SG_ 458 BCmHuORVMHmiVrCmdAck 2;
BA_ "GenSigTimeoutMsg_HU_High_X445" SG_ 458 BCmHuORVMHmiVrCmdAck 0;
BA_ "GenSigTimeoutMsg_HU_Mid_X445" SG_ 458 BCmHuORVMHmiVrCmdAck 0;
BA_ "GenSigTimeoutTime_HU_High_X445" SG_ 458 BCmHuORVMHmiVrCmdAck 0;
BA_ "GenSigTimeoutTime_HU_Mid_X445" SG_ 458 BCmHuORVMHmiVrCmdAck 0;
BA_ "GenSigTimeoutMsg_IVI" SG_ 458 BCmHuORVMHmiVrCmdAck 0;
BA_ "GenSigTimeoutTime_IVI" SG_ 458 BCmHuORVMHmiVrCmdAck 0;
BA_ "GenSigTimeoutTime_HU_Mid_X451" SG_ 458 BCmHuMoodLightVrCmdAck 0;
BA_ "GenSigTimeoutTime_HU_High_X451" SG_ 458 BCmHuMoodLightVrCmdAck 0;
BA_ "GenSigTimeoutTime_HU_B" SG_ 458 BCmHuMoodLightVrCmdAck 0;
BA_ "GenSigTimeoutTime_HU_A" SG_ 458 BCmHuMoodLightVrCmdAck 0;
BA_ "GenSigTimeoutMsg_HU_Mid_X451" SG_ 458 BCmHuMoodLightVrCmdAck 0;
BA_ "GenSigTimeoutMsg_HU_High_X451" SG_ 458 BCmHuMoodLightVrCmdAck 0;
BA_ "GenSigTimeoutMsg_HU_B" SG_ 458 BCmHuMoodLightVrCmdAck 0;
BA_ "GenSigTimeoutMsg_HU_A" SG_ 458 BCmHuMoodLightVrCmdAck 0;
BA_ "GenSigSendType" SG_ 458 BCmHuMoodLightVrCmdAck 2;
BA_ "GenSigTimeoutMsg_HU_High_X445" SG_ 458 BCmHuMoodLightVrCmdAck 0;
BA_ "GenSigTimeoutMsg_HU_Mid_X445" SG_ 458 BCmHuMoodLightVrCmdAck 0;
BA_ "GenSigTimeoutTime_HU_High_X445" SG_ 458 BCmHuMoodLightVrCmdAck 0;
BA_ "GenSigTimeoutTime_HU_Mid_X445" SG_ 458 BCmHuMoodLightVrCmdAck 0;
BA_ "GenSigTimeoutMsg_IVI" SG_ 458 BCmHuMoodLightVrCmdAck 0;
BA_ "GenSigTimeoutTime_IVI" SG_ 458 BCmHuMoodLightVrCmdAck 0;
BA_ "GenSigTimeoutTime_HU_Mid_X451" SG_ 458 BCmHuHazardLampVrCmdAck 0;
BA_ "GenSigTimeoutTime_HU_High_X451" SG_ 458 BCmHuHazardLampVrCmdAck 0;
BA_ "GenSigTimeoutTime_HU_B" SG_ 458 BCmHuHazardLampVrCmdAck 0;
BA_ "GenSigTimeoutTime_HU_A" SG_ 458 BCmHuHazardLampVrCmdAck 0;
BA_ "GenSigTimeoutMsg_HU_Mid_X451" SG_ 458 BCmHuHazardLampVrCmdAck 0;
BA_ "GenSigTimeoutMsg_HU_High_X451" SG_ 458 BCmHuHazardLampVrCmdAck 0;
BA_ "GenSigTimeoutMsg_HU_B" SG_ 458 BCmHuHazardLampVrCmdAck 0;
BA_ "GenSigTimeoutMsg_HU_A" SG_ 458 BCmHuHazardLampVrCmdAck 0;
BA_ "GenSigSendType" SG_ 458 BCmHuHazardLampVrCmdAck 2;
BA_ "GenSigTimeoutMsg_HU_High_X445" SG_ 458 BCmHuHazardLampVrCmdAck 0;
BA_ "GenSigTimeoutMsg_HU_Mid_X445" SG_ 458 BCmHuHazardLampVrCmdAck 0;
BA_ "GenSigTimeoutTime_HU_High_X445" SG_ 458 BCmHuHazardLampVrCmdAck 0;
BA_ "GenSigTimeoutTime_HU_Mid_X445" SG_ 458 BCmHuHazardLampVrCmdAck 0;
BA_ "GenSigTimeoutMsg_IVI" SG_ 458 BCmHuHazardLampVrCmdAck 0;
BA_ "GenSigTimeoutTime_IVI" SG_ 458 BCmHuHazardLampVrCmdAck 0;
BA_ "GenSigTimeoutTime_HU_Mid_X451" SG_ 458 BCmHuDRLVrCmdAck 0;
BA_ "GenSigTimeoutTime_HU_High_X451" SG_ 458 BCmHuDRLVrCmdAck 0;
BA_ "GenSigTimeoutTime_HU_B" SG_ 458 BCmHuDRLVrCmdAck 0;
BA_ "GenSigTimeoutTime_HU_A" SG_ 458 BCmHuDRLVrCmdAck 0;
BA_ "GenSigTimeoutMsg_HU_Mid_X451" SG_ 458 BCmHuDRLVrCmdAck 0;
BA_ "GenSigTimeoutMsg_HU_High_X451" SG_ 458 BCmHuDRLVrCmdAck 0;
BA_ "GenSigTimeoutMsg_HU_B" SG_ 458 BCmHuDRLVrCmdAck 0;
BA_ "GenSigTimeoutMsg_HU_A" SG_ 458 BCmHuDRLVrCmdAck 0;
BA_ "GenSigSendType" SG_ 458 BCmHuDRLVrCmdAck 2;
BA_ "GenSigTimeoutMsg_HU_High_X445" SG_ 458 BCmHuDRLVrCmdAck 0;
BA_ "GenSigTimeoutMsg_HU_Mid_X445" SG_ 458 BCmHuDRLVrCmdAck 0;
BA_ "GenSigTimeoutTime_HU_High_X445" SG_ 458 BCmHuDRLVrCmdAck 0;
BA_ "GenSigTimeoutTime_HU_Mid_X445" SG_ 458 BCmHuDRLVrCmdAck 0;
BA_ "GenSigTimeoutMsg_IVI" SG_ 458 BCmHuDRLVrCmdAck 0;
BA_ "GenSigTimeoutTime_IVI" SG_ 458 BCmHuDRLVrCmdAck 0;
BA_ "GenSigTimeoutTime_HU_Mid_X451" SG_ 458 BCmHuAmbientLightVrCmdAck 0;
BA_ "GenSigTimeoutTime_HU_High_X451" SG_ 458 BCmHuAmbientLightVrCmdAck 0;
BA_ "GenSigTimeoutTime_HU_B" SG_ 458 BCmHuAmbientLightVrCmdAck 0;
BA_ "GenSigTimeoutTime_HU_A" SG_ 458 BCmHuAmbientLightVrCmdAck 0;
BA_ "GenSigTimeoutMsg_HU_Mid_X451" SG_ 458 BCmHuAmbientLightVrCmdAck 0;
BA_ "GenSigTimeoutMsg_HU_High_X451" SG_ 458 BCmHuAmbientLightVrCmdAck 0;
BA_ "GenSigTimeoutMsg_HU_B" SG_ 458 BCmHuAmbientLightVrCmdAck 0;
BA_ "GenSigTimeoutMsg_HU_A" SG_ 458 BCmHuAmbientLightVrCmdAck 0;
BA_ "GenSigSendType" SG_ 458 BCmHuAmbientLightVrCmdAck 2;
BA_ "GenSigTimeoutMsg_HU_High_X445" SG_ 458 BCmHuAmbientLightVrCmdAck 0;
BA_ "GenSigTimeoutMsg_HU_Mid_X445" SG_ 458 BCmHuAmbientLightVrCmdAck 0;
BA_ "GenSigTimeoutTime_HU_High_X445" SG_ 458 BCmHuAmbientLightVrCmdAck 0;
BA_ "GenSigTimeoutTime_HU_Mid_X445" SG_ 458 BCmHuAmbientLightVrCmdAck 0;
BA_ "GenSigTimeoutMsg_IVI" SG_ 458 BCmHuAmbientLightVrCmdAck 0;
BA_ "GenSigTimeoutTime_IVI" SG_ 458 BCmHuAmbientLightVrCmdAck 0;
BA_ "GenSigTimeoutTime_HU_Mid_X451" SG_ 458 BCmHuTiltVrCmdAck 0;
BA_ "GenSigTimeoutTime_HU_High_X451" SG_ 458 BCmHuTiltVrCmdAck 0;
BA_ "GenSigTimeoutTime_HU_B" SG_ 458 BCmHuTiltVrCmdAck 0;
BA_ "GenSigTimeoutTime_HU_A" SG_ 458 BCmHuTiltVrCmdAck 0;
BA_ "GenSigTimeoutMsg_HU_Mid_X451" SG_ 458 BCmHuTiltVrCmdAck 0;
BA_ "GenSigTimeoutMsg_HU_High_X451" SG_ 458 BCmHuTiltVrCmdAck 0;
BA_ "GenSigTimeoutMsg_HU_B" SG_ 458 BCmHuTiltVrCmdAck 0;
BA_ "GenSigTimeoutMsg_HU_A" SG_ 458 BCmHuTiltVrCmdAck 0;
BA_ "GenSigSendType" SG_ 458 BCmHuTiltVrCmdAck 2;
BA_ "GenSigTimeoutMsg_HU_High_X445" SG_ 458 BCmHuTiltVrCmdAck 0;
BA_ "GenSigTimeoutMsg_HU_Mid_X445" SG_ 458 BCmHuTiltVrCmdAck 0;
BA_ "GenSigTimeoutTime_HU_High_X445" SG_ 458 BCmHuTiltVrCmdAck 0;
BA_ "GenSigTimeoutTime_HU_Mid_X445" SG_ 458 BCmHuTiltVrCmdAck 0;
BA_ "GenSigTimeoutMsg_IVI" SG_ 458 BCmHuTiltVrCmdAck 0;
BA_ "GenSigTimeoutTime_IVI" SG_ 458 BCmHuTiltVrCmdAck 0;
BA_ "GenSigTimeoutTime_HU_Mid_X451" SG_ 458 BCmHuSunShadeVrCmdAck 0;
BA_ "GenSigTimeoutTime_HU_High_X451" SG_ 458 BCmHuSunShadeVrCmdAck 0;
BA_ "GenSigTimeoutTime_HU_B" SG_ 458 BCmHuSunShadeVrCmdAck 0;
BA_ "GenSigTimeoutTime_HU_A" SG_ 458 BCmHuSunShadeVrCmdAck 0;
BA_ "GenSigTimeoutMsg_HU_Mid_X451" SG_ 458 BCmHuSunShadeVrCmdAck 0;
BA_ "GenSigTimeoutMsg_HU_High_X451" SG_ 458 BCmHuSunShadeVrCmdAck 0;
BA_ "GenSigTimeoutMsg_HU_B" SG_ 458 BCmHuSunShadeVrCmdAck 0;
BA_ "GenSigTimeoutMsg_HU_A" SG_ 458 BCmHuSunShadeVrCmdAck 0;
BA_ "GenSigSendType" SG_ 458 BCmHuSunShadeVrCmdAck 2;
BA_ "GenSigTimeoutMsg_HU_High_X445" SG_ 458 BCmHuSunShadeVrCmdAck 0;
BA_ "GenSigTimeoutMsg_HU_Mid_X445" SG_ 458 BCmHuSunShadeVrCmdAck 0;
BA_ "GenSigTimeoutTime_HU_High_X445" SG_ 458 BCmHuSunShadeVrCmdAck 0;
BA_ "GenSigTimeoutTime_HU_Mid_X445" SG_ 458 BCmHuSunShadeVrCmdAck 0;
BA_ "GenSigTimeoutMsg_IVI" SG_ 458 BCmHuSunShadeVrCmdAck 0;
BA_ "GenSigTimeoutTime_IVI" SG_ 458 BCmHuSunShadeVrCmdAck 0;
BA_ "GenSigTimeoutTime_HU_Mid_X451" SG_ 458 BCmHuSunRoofVrCmdAck 0;
BA_ "GenSigTimeoutTime_HU_High_X451" SG_ 458 BCmHuSunRoofVrCmdAck 0;
BA_ "GenSigTimeoutTime_HU_B" SG_ 458 BCmHuSunRoofVrCmdAck 0;
BA_ "GenSigTimeoutTime_HU_A" SG_ 458 BCmHuSunRoofVrCmdAck 0;
BA_ "GenSigTimeoutMsg_HU_Mid_X451" SG_ 458 BCmHuSunRoofVrCmdAck 0;
BA_ "GenSigTimeoutMsg_HU_High_X451" SG_ 458 BCmHuSunRoofVrCmdAck 0;
BA_ "GenSigTimeoutMsg_HU_B" SG_ 458 BCmHuSunRoofVrCmdAck 0;
BA_ "GenSigTimeoutMsg_HU_A" SG_ 458 BCmHuSunRoofVrCmdAck 0;
BA_ "GenSigSendType" SG_ 458 BCmHuSunRoofVrCmdAck 2;
BA_ "GenSigTimeoutMsg_HU_High_X445" SG_ 458 BCmHuSunRoofVrCmdAck 0;
BA_ "GenSigTimeoutMsg_HU_Mid_X445" SG_ 458 BCmHuSunRoofVrCmdAck 0;
BA_ "GenSigTimeoutTime_HU_High_X445" SG_ 458 BCmHuSunRoofVrCmdAck 0;
BA_ "GenSigTimeoutTime_HU_Mid_X445" SG_ 458 BCmHuSunRoofVrCmdAck 0;
BA_ "GenSigTimeoutMsg_IVI" SG_ 458 BCmHuSunRoofVrCmdAck 0;
BA_ "GenSigTimeoutTime_IVI" SG_ 458 BCmHuSunRoofVrCmdAck 0;
BA_ "GenSigTimeoutTime_HU_Mid_X451" SG_ 2019 VCU_DiagRequest 0;
BA_ "GenSigTimeoutTime_HU_High_X451" SG_ 2019 VCU_DiagRequest 0;
BA_ "GenSigTimeoutTime_HU_B" SG_ 2019 VCU_DiagRequest 0;
BA_ "GenSigTimeoutTime_HU_A" SG_ 2019 VCU_DiagRequest 0;
BA_ "GenSigTimeoutMsg_HU_Mid_X451" SG_ 2019 VCU_DiagRequest 0;
BA_ "GenSigTimeoutMsg_HU_High_X451" SG_ 2019 VCU_DiagRequest 0;
BA_ "GenSigTimeoutMsg_HU_B" SG_ 2019 VCU_DiagRequest 0;
BA_ "GenSigTimeoutMsg_HU_A" SG_ 2019 VCU_DiagRequest 0;
BA_ "GenSigSendType" SG_ 2019 VCU_DiagRequest 1;
BA_ "GenSigTimeoutMsg_HU_High_X445" SG_ 2019 VCU_DiagRequest 0;
BA_ "GenSigTimeoutMsg_HU_Mid_X445" SG_ 2019 VCU_DiagRequest 0;
BA_ "GenSigTimeoutTime_HU_High_X445" SG_ 2019 VCU_DiagRequest 0;
BA_ "GenSigTimeoutTime_HU_Mid_X445" SG_ 2019 VCU_DiagRequest 0;
BA_ "GenSigTimeoutTime_HU_Mid_X451" SG_ 2027 VCU_DiagResponse_USDT 0;
BA_ "GenSigTimeoutTime_HU_High_X451" SG_ 2027 VCU_DiagResponse_USDT 0;
BA_ "GenSigTimeoutTime_HU_B" SG_ 2027 VCU_DiagResponse_USDT 0;
BA_ "GenSigTimeoutTime_HU_A" SG_ 2027 VCU_DiagResponse_USDT 0;
BA_ "GenSigTimeoutMsg_HU_Mid_X451" SG_ 2027 VCU_DiagResponse_USDT 0;
BA_ "GenSigTimeoutMsg_HU_High_X451" SG_ 2027 VCU_DiagResponse_USDT 0;
BA_ "GenSigTimeoutMsg_HU_B" SG_ 2027 VCU_DiagResponse_USDT 0;
BA_ "GenSigTimeoutMsg_HU_A" SG_ 2027 VCU_DiagResponse_USDT 0;
BA_ "GenSigSendType" SG_ 2027 VCU_DiagResponse_USDT 1;
BA_ "GenSigTimeoutMsg_HU_High_X445" SG_ 2027 VCU_DiagResponse_USDT 0;
BA_ "GenSigTimeoutMsg_HU_Mid_X445" SG_ 2027 VCU_DiagResponse_USDT 0;
BA_ "GenSigTimeoutTime_HU_High_X445" SG_ 2027 VCU_DiagResponse_USDT 0;
BA_ "GenSigTimeoutTime_HU_Mid_X445" SG_ 2027 VCU_DiagResponse_USDT 0;
BA_ "GenSigSendType" SG_ 567 MRC_3 7;
BA_ "GenSigCycleTimeActive" SG_ 567 MRC_3 50;
BA_ "GenSigCycleTime" SG_ 567 MRC_3 50;
BA_ "GenSigSendType" SG_ 567 CRC_3 7;
BA_ "GenSigCycleTimeActive" SG_ 567 CRC_3 50;
BA_ "GenSigCycleTime" SG_ 567 CRC_3 50;
BA_ "GenSigStartValue" SG_ 567 ApbState_Old 7;
BA_ "GenSigSendType" SG_ 567 ApbState_Old 7;
BA_ "GenSigCycleTimeActive" SG_ 567 ApbState_Old 50;
BA_ "GenSigCycleTime" SG_ 567 ApbState_Old 50;
BA_ "GenSigSendType" SG_ 567 BrkPaddleTravel2Status 7;
BA_ "GenSigCycleTimeActive" SG_ 567 BrkPaddleTravel2Status 50;
BA_ "GenSigCycleTime" SG_ 567 BrkPaddleTravel2Status 50;
BA_ "GenSigSendType" SG_ 567 BrkPaddleTravel2 7;
BA_ "GenSigCycleTimeActive" SG_ 567 BrkPaddleTravel2 50;
BA_ "GenSigCycleTime" SG_ 567 BrkPaddleTravel2 50;
BA_ "GenSigSendType" SG_ 567 MCMsAvailability 7;
BA_ "GenSigCycleTimeActive" SG_ 567 MCMsAvailability 50;
BA_ "GenSigCycleTime" SG_ 567 MCMsAvailability 50;
BA_ "GenSigSendType" SG_ 567 BrkPaddleTravel1Status 7;
BA_ "GenSigCycleTimeActive" SG_ 567 BrkPaddleTravel1Status 50;
BA_ "GenSigCycleTime" SG_ 567 BrkPaddleTravel1Status 50;
BA_ "GenSigSendType" SG_ 567 BrkPaddleTravel1 7;
BA_ "GenSigCycleTimeActive" SG_ 567 BrkPaddleTravel1 50;
BA_ "GenSigCycleTime" SG_ 567 BrkPaddleTravel1 50;
BA_ "GenSigSendType" SG_ 567 MCMsErrorState 7;
BA_ "GenSigCycleTimeActive" SG_ 567 MCMsErrorState 50;
BA_ "GenSigCycleTime" SG_ 567 MCMsErrorState 50;
BA_ "GenSigSendType" SG_ 567 MCMsActive 7;
BA_ "GenSigCycleTimeActive" SG_ 567 MCMsActive 50;
BA_ "GenSigCycleTime" SG_ 567 MCMsActive 50;
BA_ "GenSigSendType" SG_ 567 APbBeepState 7;
BA_ "GenSigCycleTimeActive" SG_ 567 APbBeepState 50;
BA_ "GenSigCycleTime" SG_ 567 APbBeepState 50;
BA_ "GenSigSendType" SG_ 567 AVhStatus 7;
BA_ "GenSigCycleTimeActive" SG_ 567 AVhStatus 50;
BA_ "GenSigCycleTime" SG_ 567 AVhStatus 50;
BA_ "GenSigSendType" SG_ 567 AVhState 7;
BA_ "GenSigCycleTimeActive" SG_ 567 AVhState 50;
BA_ "GenSigCycleTime" SG_ 567 AVhState 50;
BA_ "GenSigSendType" SG_ 567 AVhAvailability 7;
BA_ "GenSigCycleTimeActive" SG_ 567 AVhAvailability 50;
BA_ "GenSigCycleTime" SG_ 567 AVhAvailability 50;
BA_ "GenSigStartValue" SG_ 567 APbState 7;
BA_ "GenSigSendType" SG_ 567 APbState 7;
BA_ "GenSigCycleTimeActive" SG_ 567 APbState 50;
BA_ "GenSigCycleTime" SG_ 567 APbState 50;
BA_ "GenSigStartValue" SG_ 567 APbErrorState 2;
BA_ "GenSigSendType" SG_ 567 APbErrorState 7;
BA_ "GenSigCycleTimeActive" SG_ 567 APbErrorState 50;
BA_ "GenSigCycleTime" SG_ 567 APbErrorState 50;
BA_ "GenSigSendType" SG_ 567 APbAvailability 7;
BA_ "GenSigCycleTimeActive" SG_ 567 APbAvailability 50;
BA_ "GenSigCycleTime" SG_ 567 APbAvailability 50;
BA_ "GenSigSendType" SG_ 1397 BET_Response 7;
BA_ "GenSigSendType" SG_ 1396 BET_Request 7;
BA_ "GenSigSendType" SG_ 1395 Validation_Mode_Res 7;
BA_ "GenSigSendType" SG_ 1394 Validation_Mode_Req 7;
BA_ "GenSigSendType" SG_ 1393 XCP_DTO 7;
BA_ "GenSigSendType" SG_ 1392 XCP_CRO 7;
BA_ "GenSigTimeoutTime_HU_Mid_X451" SG_ 280 BrakePaddlePosStatus 0;
BA_ "GenSigTimeoutTime_HU_High_X451" SG_ 280 BrakePaddlePosStatus 0;
BA_ "GenSigTimeoutTime_HU_B" SG_ 280 BrakePaddlePosStatus 0;
BA_ "GenSigTimeoutTime_HU_A" SG_ 280 BrakePaddlePosStatus 0;
BA_ "GenSigTimeoutMsg_HU_Mid_X451" SG_ 280 BrakePaddlePosStatus 0;
BA_ "GenSigTimeoutMsg_HU_High_X451" SG_ 280 BrakePaddlePosStatus 0;
BA_ "GenSigTimeoutMsg_HU_B" SG_ 280 BrakePaddlePosStatus 0;
BA_ "GenSigTimeoutMsg_HU_A" SG_ 280 BrakePaddlePosStatus 0;
BA_ "GenSigSendType" SG_ 280 BrakePaddlePosStatus 7;
BA_ "GenSigCycleTimeActive" SG_ 280 BrakePaddlePosStatus 10;
BA_ "GenSigCycleTime" SG_ 280 BrakePaddlePosStatus 10;
BA_ "GenSigTimeoutMsg_HU_High_X445" SG_ 280 BrakePaddlePosStatus 0;
BA_ "GenSigTimeoutMsg_HU_Mid_X445" SG_ 280 BrakePaddlePosStatus 0;
BA_ "GenSigTimeoutTime_HU_High_X445" SG_ 280 BrakePaddlePosStatus 0;
BA_ "GenSigTimeoutTime_HU_Mid_X445" SG_ 280 BrakePaddlePosStatus 0;
BA_ "GenSigTimeoutTime_HU_Mid_X451" SG_ 280 BrakePaddlePos 0;
BA_ "GenSigTimeoutTime_HU_High_X451" SG_ 280 BrakePaddlePos 0;
BA_ "GenSigTimeoutTime_HU_B" SG_ 280 BrakePaddlePos 0;
BA_ "GenSigTimeoutTime_HU_A" SG_ 280 BrakePaddlePos 0;
BA_ "GenSigTimeoutMsg_HU_Mid_X451" SG_ 280 BrakePaddlePos 0;
BA_ "GenSigTimeoutMsg_HU_High_X451" SG_ 280 BrakePaddlePos 0;
BA_ "GenSigTimeoutMsg_HU_B" SG_ 280 BrakePaddlePos 0;
BA_ "GenSigTimeoutMsg_HU_A" SG_ 280 BrakePaddlePos 0;
BA_ "GenSigSendType" SG_ 280 BrakePaddlePos 7;
BA_ "GenSigCycleTimeActive" SG_ 280 BrakePaddlePos 10;
BA_ "GenSigCycleTime" SG_ 280 BrakePaddlePos 10;
BA_ "GenSigTimeoutMsg_HU_High_X445" SG_ 280 BrakePaddlePos 0;
BA_ "GenSigTimeoutMsg_HU_Mid_X445" SG_ 280 BrakePaddlePos 0;
BA_ "GenSigTimeoutTime_HU_High_X445" SG_ 280 BrakePaddlePos 0;
BA_ "GenSigTimeoutTime_HU_Mid_X445" SG_ 280 BrakePaddlePos 0;
BA_ "GenSigTimeoutTime_HU_Mid_X451" SG_ 280 TarRecupTrqStatus 0;
BA_ "GenSigTimeoutTime_HU_High_X451" SG_ 280 TarRecupTrqStatus 0;
BA_ "GenSigTimeoutTime_HU_B" SG_ 280 TarRecupTrqStatus 0;
BA_ "GenSigTimeoutTime_HU_A" SG_ 280 TarRecupTrqStatus 0;
BA_ "GenSigTimeoutMsg_HU_Mid_X451" SG_ 280 TarRecupTrqStatus 0;
BA_ "GenSigTimeoutMsg_HU_High_X451" SG_ 280 TarRecupTrqStatus 0;
BA_ "GenSigTimeoutMsg_HU_B" SG_ 280 TarRecupTrqStatus 0;
BA_ "GenSigTimeoutMsg_HU_A" SG_ 280 TarRecupTrqStatus 0;
BA_ "GenSigSendType" SG_ 280 TarRecupTrqStatus 7;
BA_ "GenSigCycleTimeActive" SG_ 280 TarRecupTrqStatus 10;
BA_ "GenSigCycleTime" SG_ 280 TarRecupTrqStatus 10;
BA_ "GenSigTimeoutMsg_HU_High_X445" SG_ 280 TarRecupTrqStatus 0;
BA_ "GenSigTimeoutMsg_HU_Mid_X445" SG_ 280 TarRecupTrqStatus 0;
BA_ "GenSigTimeoutTime_HU_High_X445" SG_ 280 TarRecupTrqStatus 0;
BA_ "GenSigTimeoutTime_HU_Mid_X445" SG_ 280 TarRecupTrqStatus 0;
BA_ "GenSigTimeoutTime_HU_Mid_X451" SG_ 280 TarRecupTrq 0;
BA_ "GenSigTimeoutTime_HU_High_X451" SG_ 280 TarRecupTrq 0;
BA_ "GenSigTimeoutTime_HU_B" SG_ 280 TarRecupTrq 0;
BA_ "GenSigTimeoutTime_HU_A" SG_ 280 TarRecupTrq 0;
BA_ "GenSigTimeoutMsg_HU_Mid_X451" SG_ 280 TarRecupTrq 0;
BA_ "GenSigTimeoutMsg_HU_High_X451" SG_ 280 TarRecupTrq 0;
BA_ "GenSigTimeoutMsg_HU_B" SG_ 280 TarRecupTrq 0;
BA_ "GenSigTimeoutMsg_HU_A" SG_ 280 TarRecupTrq 0;
BA_ "GenSigSendType" SG_ 280 TarRecupTrq 7;
BA_ "GenSigCycleTimeActive" SG_ 280 TarRecupTrq 10;
BA_ "GenSigCycleTime" SG_ 280 TarRecupTrq 10;
BA_ "GenSigTimeoutMsg_HU_High_X445" SG_ 280 TarRecupTrq 0;
BA_ "GenSigTimeoutMsg_HU_Mid_X445" SG_ 280 TarRecupTrq 0;
BA_ "GenSigTimeoutTime_HU_High_X445" SG_ 280 TarRecupTrq 0;
BA_ "GenSigTimeoutTime_HU_Mid_X445" SG_ 280 TarRecupTrq 0;
BA_ "GenSigTimeoutTime_HU_Mid_X451" SG_ 280 InhibitCostRecuprationStatus 0;
BA_ "GenSigTimeoutTime_HU_High_X451" SG_ 280 InhibitCostRecuprationStatus 0;
BA_ "GenSigTimeoutTime_HU_B" SG_ 280 InhibitCostRecuprationStatus 0;
BA_ "GenSigTimeoutTime_HU_A" SG_ 280 InhibitCostRecuprationStatus 0;
BA_ "GenSigTimeoutMsg_HU_Mid_X451" SG_ 280 InhibitCostRecuprationStatus 0;
BA_ "GenSigTimeoutMsg_HU_High_X451" SG_ 280 InhibitCostRecuprationStatus 0;
BA_ "GenSigTimeoutMsg_HU_B" SG_ 280 InhibitCostRecuprationStatus 0;
BA_ "GenSigTimeoutMsg_HU_A" SG_ 280 InhibitCostRecuprationStatus 0;
BA_ "GenSigSendType" SG_ 280 InhibitCostRecuprationStatus 7;
BA_ "GenSigCycleTimeActive" SG_ 280 InhibitCostRecuprationStatus 10;
BA_ "GenSigCycleTime" SG_ 280 InhibitCostRecuprationStatus 10;
BA_ "GenSigTimeoutMsg_HU_High_X445" SG_ 280 InhibitCostRecuprationStatus 0;
BA_ "GenSigTimeoutMsg_HU_Mid_X445" SG_ 280 InhibitCostRecuprationStatus 0;
BA_ "GenSigTimeoutTime_HU_High_X445" SG_ 280 InhibitCostRecuprationStatus 0;
BA_ "GenSigTimeoutTime_HU_Mid_X445" SG_ 280 InhibitCostRecuprationStatus 0;
BA_ "GenSigTimeoutTime_HU_Mid_X451" SG_ 280 InhibitCostRecupration 0;
BA_ "GenSigTimeoutTime_HU_High_X451" SG_ 280 InhibitCostRecupration 0;
BA_ "GenSigTimeoutTime_HU_B" SG_ 280 InhibitCostRecupration 0;
BA_ "GenSigTimeoutTime_HU_A" SG_ 280 InhibitCostRecupration 0;
BA_ "GenSigTimeoutMsg_HU_Mid_X451" SG_ 280 InhibitCostRecupration 0;
BA_ "GenSigTimeoutMsg_HU_High_X451" SG_ 280 InhibitCostRecupration 0;
BA_ "GenSigTimeoutMsg_HU_B" SG_ 280 InhibitCostRecupration 0;
BA_ "GenSigTimeoutMsg_HU_A" SG_ 280 InhibitCostRecupration 0;
BA_ "GenSigSendType" SG_ 280 InhibitCostRecupration 7;
BA_ "GenSigCycleTimeActive" SG_ 280 InhibitCostRecupration 10;
BA_ "GenSigCycleTime" SG_ 280 InhibitCostRecupration 10;
BA_ "GenSigTimeoutMsg_HU_High_X445" SG_ 280 InhibitCostRecupration 0;
BA_ "GenSigTimeoutMsg_HU_Mid_X445" SG_ 280 InhibitCostRecupration 0;
BA_ "GenSigTimeoutTime_HU_High_X445" SG_ 280 InhibitCostRecupration 0;
BA_ "GenSigTimeoutTime_HU_Mid_X445" SG_ 280 InhibitCostRecupration 0;
BA_ "GenSigTimeoutTime_HU_Mid_X451" SG_ 280 InhibitRecuprationAbsStatus 0;
BA_ "GenSigTimeoutTime_HU_High_X451" SG_ 280 InhibitRecuprationAbsStatus 0;
BA_ "GenSigTimeoutTime_HU_B" SG_ 280 InhibitRecuprationAbsStatus 0;
BA_ "GenSigTimeoutTime_HU_A" SG_ 280 InhibitRecuprationAbsStatus 0;
BA_ "GenSigTimeoutMsg_HU_Mid_X451" SG_ 280 InhibitRecuprationAbsStatus 0;
BA_ "GenSigTimeoutMsg_HU_High_X451" SG_ 280 InhibitRecuprationAbsStatus 0;
BA_ "GenSigTimeoutMsg_HU_B" SG_ 280 InhibitRecuprationAbsStatus 0;
BA_ "GenSigTimeoutMsg_HU_A" SG_ 280 InhibitRecuprationAbsStatus 0;
BA_ "GenSigSendType" SG_ 280 InhibitRecuprationAbsStatus 7;
BA_ "GenSigCycleTimeActive" SG_ 280 InhibitRecuprationAbsStatus 10;
BA_ "GenSigCycleTime" SG_ 280 InhibitRecuprationAbsStatus 10;
BA_ "GenSigTimeoutMsg_HU_High_X445" SG_ 280 InhibitRecuprationAbsStatus 0;
BA_ "GenSigTimeoutMsg_HU_Mid_X445" SG_ 280 InhibitRecuprationAbsStatus 0;
BA_ "GenSigTimeoutTime_HU_High_X445" SG_ 280 InhibitRecuprationAbsStatus 0;
BA_ "GenSigTimeoutTime_HU_Mid_X445" SG_ 280 InhibitRecuprationAbsStatus 0;
BA_ "GenSigTimeoutTime_HU_Mid_X451" SG_ 280 InhibitRecuprationAbs 0;
BA_ "GenSigTimeoutTime_HU_High_X451" SG_ 280 InhibitRecuprationAbs 0;
BA_ "GenSigTimeoutTime_HU_B" SG_ 280 InhibitRecuprationAbs 0;
BA_ "GenSigTimeoutTime_HU_A" SG_ 280 InhibitRecuprationAbs 0;
BA_ "GenSigTimeoutMsg_HU_Mid_X451" SG_ 280 InhibitRecuprationAbs 0;
BA_ "GenSigTimeoutMsg_HU_High_X451" SG_ 280 InhibitRecuprationAbs 0;
BA_ "GenSigTimeoutMsg_HU_B" SG_ 280 InhibitRecuprationAbs 0;
BA_ "GenSigTimeoutMsg_HU_A" SG_ 280 InhibitRecuprationAbs 0;
BA_ "GenSigSendType" SG_ 280 InhibitRecuprationAbs 7;
BA_ "GenSigCycleTimeActive" SG_ 280 InhibitRecuprationAbs 10;
BA_ "GenSigCycleTime" SG_ 280 InhibitRecuprationAbs 10;
BA_ "GenSigTimeoutMsg_HU_High_X445" SG_ 280 InhibitRecuprationAbs 0;
BA_ "GenSigTimeoutMsg_HU_Mid_X445" SG_ 280 InhibitRecuprationAbs 0;
BA_ "GenSigTimeoutTime_HU_High_X445" SG_ 280 InhibitRecuprationAbs 0;
BA_ "GenSigTimeoutTime_HU_Mid_X445" SG_ 280 InhibitRecuprationAbs 0;
BA_ "GenSigTimeoutTime_HU_Mid_X451" SG_ 452 CarAnniversaryResponse 0;
BA_ "GenSigTimeoutTime_HU_High_X451" SG_ 452 CarAnniversaryResponse 0;
BA_ "GenSigTimeoutTime_HU_B" SG_ 452 CarAnniversaryResponse 0;
BA_ "GenSigTimeoutTime_HU_A" SG_ 452 CarAnniversaryResponse 0;
BA_ "GenSigTimeoutMsg_HU_Mid_X451" SG_ 452 CarAnniversaryResponse 0;
BA_ "GenSigTimeoutMsg_HU_High_X451" SG_ 452 CarAnniversaryResponse 0;
BA_ "GenSigTimeoutMsg_HU_B" SG_ 452 CarAnniversaryResponse 0;
BA_ "GenSigTimeoutMsg_HU_A" SG_ 452 CarAnniversaryResponse 0;
BA_ "GenSigSendType" SG_ 452 CarAnniversaryResponse 1;
BA_ "GenSigTimeoutMsg_HU_High_X445" SG_ 452 CarAnniversaryResponse 0;
BA_ "GenSigTimeoutMsg_HU_Mid_X445" SG_ 452 CarAnniversaryResponse 0;
BA_ "GenSigTimeoutTime_HU_High_X445" SG_ 452 CarAnniversaryResponse 0;
BA_ "GenSigTimeoutTime_HU_Mid_X445" SG_ 452 CarAnniversaryResponse 0;
BA_ "GenSigTimeoutMsg_IVI" SG_ 452 CarAnniversaryResponse 0;
BA_ "GenSigTimeoutTime_IVI" SG_ 452 CarAnniversaryResponse 0;
BA_ "GenSigTimeoutTime_HU_Mid_X451" SG_ 452 OwnersBirthdayResponse 0;
BA_ "GenSigTimeoutTime_HU_High_X451" SG_ 452 OwnersBirthdayResponse 0;
BA_ "GenSigTimeoutTime_HU_B" SG_ 452 OwnersBirthdayResponse 0;
BA_ "GenSigTimeoutTime_HU_A" SG_ 452 OwnersBirthdayResponse 0;
BA_ "GenSigTimeoutMsg_HU_Mid_X451" SG_ 452 OwnersBirthdayResponse 0;
BA_ "GenSigTimeoutMsg_HU_High_X451" SG_ 452 OwnersBirthdayResponse 0;
BA_ "GenSigTimeoutMsg_HU_B" SG_ 452 OwnersBirthdayResponse 0;
BA_ "GenSigTimeoutMsg_HU_A" SG_ 452 OwnersBirthdayResponse 0;
BA_ "GenSigSendType" SG_ 452 OwnersBirthdayResponse 1;
BA_ "GenSigTimeoutMsg_HU_High_X445" SG_ 452 OwnersBirthdayResponse 0;
BA_ "GenSigTimeoutMsg_HU_Mid_X445" SG_ 452 OwnersBirthdayResponse 0;
BA_ "GenSigTimeoutTime_HU_High_X445" SG_ 452 OwnersBirthdayResponse 0;
BA_ "GenSigTimeoutTime_HU_Mid_X445" SG_ 452 OwnersBirthdayResponse 0;
BA_ "GenSigTimeoutMsg_IVI" SG_ 452 OwnersBirthdayResponse 0;
BA_ "GenSigTimeoutTime_IVI" SG_ 452 OwnersBirthdayResponse 0;
BA_ "GenSigTimeoutTime_HU_Mid_X451" SG_ 452 OwnersAnniversaryResponse 0;
BA_ "GenSigTimeoutTime_HU_High_X451" SG_ 452 OwnersAnniversaryResponse 0;
BA_ "GenSigTimeoutTime_HU_B" SG_ 452 OwnersAnniversaryResponse 0;
BA_ "GenSigTimeoutTime_HU_A" SG_ 452 OwnersAnniversaryResponse 0;
BA_ "GenSigTimeoutMsg_HU_Mid_X451" SG_ 452 OwnersAnniversaryResponse 0;
BA_ "GenSigTimeoutMsg_HU_High_X451" SG_ 452 OwnersAnniversaryResponse 0;
BA_ "GenSigTimeoutMsg_HU_B" SG_ 452 OwnersAnniversaryResponse 0;
BA_ "GenSigTimeoutMsg_HU_A" SG_ 452 OwnersAnniversaryResponse 0;
BA_ "GenSigSendType" SG_ 452 OwnersAnniversaryResponse 1;
BA_ "GenSigTimeoutMsg_HU_High_X445" SG_ 452 OwnersAnniversaryResponse 0;
BA_ "GenSigTimeoutMsg_HU_Mid_X445" SG_ 452 OwnersAnniversaryResponse 0;
BA_ "GenSigTimeoutTime_HU_High_X445" SG_ 452 OwnersAnniversaryResponse 0;
BA_ "GenSigTimeoutTime_HU_Mid_X445" SG_ 452 OwnersAnniversaryResponse 0;
BA_ "GenSigTimeoutMsg_IVI" SG_ 452 OwnersAnniversaryResponse 0;
BA_ "GenSigTimeoutTime_IVI" SG_ 452 OwnersAnniversaryResponse 0;
BA_ "GenSigTimeoutTime_HU_Mid_X451" SG_ 962 GPsInfoY 2500;
BA_ "GenSigTimeoutTime_HU_High_X451" SG_ 962 GPsInfoY 2500;
BA_ "GenSigTimeoutTime_HU_B" SG_ 962 GPsInfoY 2500;
BA_ "GenSigTimeoutTime_HU_A" SG_ 962 GPsInfoY 2500;
BA_ "GenSigTimeoutMsg_HU_Mid_X451" SG_ 962 GPsInfoY 2500;
BA_ "GenSigTimeoutMsg_HU_High_X451" SG_ 962 GPsInfoY 2500;
BA_ "GenSigTimeoutMsg_HU_B" SG_ 962 GPsInfoY 2500;
BA_ "GenSigTimeoutMsg_HU_A" SG_ 962 GPsInfoY 2500;
BA_ "GenSigStartValue" SG_ 962 GPsInfoY 900000000;
BA_ "GenSigSendType" SG_ 962 GPsInfoY 7;
BA_ "GenSigCycleTimeActive" SG_ 962 GPsInfoY 500;
BA_ "GenSigCycleTime" SG_ 962 GPsInfoY 500;
BA_ "GenSigTimeoutMsg_HU_High_X445" SG_ 962 GPsInfoY 2500;
BA_ "GenSigTimeoutMsg_HU_Mid_X445" SG_ 962 GPsInfoY 2500;
BA_ "GenSigTimeoutTime_HU_High_X445" SG_ 962 GPsInfoY 2500;
BA_ "GenSigTimeoutTime_HU_Mid_X445" SG_ 962 GPsInfoY 2500;
BA_ "GenSigTimeoutMsg_IVI" SG_ 962 GPsInfoY 2500;
BA_ "GenSigTimeoutTime_IVI" SG_ 962 GPsInfoY 2500;
BA_ "GenSigTimeoutTime_HU_Mid_X451" SG_ 962 GPsInfoX 2500;
BA_ "GenSigTimeoutTime_HU_High_X451" SG_ 962 GPsInfoX 2500;
BA_ "GenSigTimeoutTime_HU_B" SG_ 962 GPsInfoX 2500;
BA_ "GenSigTimeoutTime_HU_A" SG_ 962 GPsInfoX 2500;
BA_ "GenSigTimeoutMsg_HU_Mid_X451" SG_ 962 GPsInfoX 2500;
BA_ "GenSigTimeoutMsg_HU_High_X451" SG_ 962 GPsInfoX 2500;
BA_ "GenSigTimeoutMsg_HU_B" SG_ 962 GPsInfoX 2500;
BA_ "GenSigTimeoutMsg_HU_A" SG_ 962 GPsInfoX 2500;
BA_ "GenSigStartValue" SG_ 962 GPsInfoX 1800000000;
BA_ "GenSigSendType" SG_ 962 GPsInfoX 7;
BA_ "GenSigCycleTimeActive" SG_ 962 GPsInfoX 500;
BA_ "GenSigCycleTime" SG_ 962 GPsInfoX 500;
BA_ "GenSigTimeoutMsg_HU_High_X445" SG_ 962 GPsInfoX 2500;
BA_ "GenSigTimeoutMsg_HU_Mid_X445" SG_ 962 GPsInfoX 2500;
BA_ "GenSigTimeoutTime_HU_High_X445" SG_ 962 GPsInfoX 2500;
BA_ "GenSigTimeoutTime_HU_Mid_X445" SG_ 962 GPsInfoX 2500;
BA_ "GenSigTimeoutMsg_IVI" SG_ 962 GPsInfoX 2500;
BA_ "GenSigTimeoutTime_IVI" SG_ 962 GPsInfoX 2500;
BA_ "GenSigTimeoutTime_HU_Mid_X451" SG_ 963 GPsInfoXYZStatus 2500;
BA_ "GenSigTimeoutTime_HU_High_X451" SG_ 963 GPsInfoXYZStatus 2500;
BA_ "GenSigTimeoutTime_HU_B" SG_ 963 GPsInfoXYZStatus 2500;
BA_ "GenSigTimeoutTime_HU_A" SG_ 963 GPsInfoXYZStatus 2500;
BA_ "GenSigTimeoutMsg_HU_Mid_X451" SG_ 963 GPsInfoXYZStatus 2500;
BA_ "GenSigTimeoutMsg_HU_High_X451" SG_ 963 GPsInfoXYZStatus 2500;
BA_ "GenSigTimeoutMsg_HU_B" SG_ 963 GPsInfoXYZStatus 2500;
BA_ "GenSigTimeoutMsg_HU_A" SG_ 963 GPsInfoXYZStatus 2500;
BA_ "GenSigSendType" SG_ 963 GPsInfoXYZStatus 7;
BA_ "GenSigCycleTimeActive" SG_ 963 GPsInfoXYZStatus 500;
BA_ "GenSigCycleTime" SG_ 963 GPsInfoXYZStatus 500;
BA_ "GenSigTimeoutMsg_HU_High_X445" SG_ 963 GPsInfoXYZStatus 2500;
BA_ "GenSigTimeoutMsg_HU_Mid_X445" SG_ 963 GPsInfoXYZStatus 2500;
BA_ "GenSigTimeoutTime_HU_High_X445" SG_ 963 GPsInfoXYZStatus 2500;
BA_ "GenSigTimeoutTime_HU_Mid_X445" SG_ 963 GPsInfoXYZStatus 2500;
BA_ "GenSigTimeoutMsg_IVI" SG_ 963 GPsInfoXYZStatus 2500;
BA_ "GenSigTimeoutTime_IVI" SG_ 963 GPsInfoXYZStatus 2500;
BA_ "GenSigTimeoutTime_HU_Mid_X451" SG_ 963 GPsInfoZ 2500;
BA_ "GenSigTimeoutTime_HU_High_X451" SG_ 963 GPsInfoZ 2500;
BA_ "GenSigTimeoutTime_HU_B" SG_ 963 GPsInfoZ 2500;
BA_ "GenSigTimeoutTime_HU_A" SG_ 963 GPsInfoZ 2500;
BA_ "GenSigTimeoutMsg_HU_Mid_X451" SG_ 963 GPsInfoZ 2500;
BA_ "GenSigTimeoutMsg_HU_High_X451" SG_ 963 GPsInfoZ 2500;
BA_ "GenSigTimeoutMsg_HU_B" SG_ 963 GPsInfoZ 2500;
BA_ "GenSigTimeoutMsg_HU_A" SG_ 963 GPsInfoZ 2500;
BA_ "GenSigStartValue" SG_ 963 GPsInfoZ 10000000;
BA_ "GenSigSendType" SG_ 963 GPsInfoZ 7;
BA_ "GenSigCycleTimeActive" SG_ 963 GPsInfoZ 500;
BA_ "GenSigCycleTime" SG_ 963 GPsInfoZ 500;
BA_ "GenSigTimeoutMsg_HU_High_X445" SG_ 963 GPsInfoZ 2500;
BA_ "GenSigTimeoutMsg_HU_Mid_X445" SG_ 963 GPsInfoZ 2500;
BA_ "GenSigTimeoutTime_HU_High_X445" SG_ 963 GPsInfoZ 2500;
BA_ "GenSigTimeoutTime_HU_Mid_X445" SG_ 963 GPsInfoZ 2500;
BA_ "GenSigTimeoutMsg_IVI" SG_ 963 GPsInfoZ 2500;
BA_ "GenSigTimeoutTime_IVI" SG_ 963 GPsInfoZ 2500;
BA_ "GenSigTimeoutTime_HU_Mid_X451" SG_ 960 TimeZone 2500;
BA_ "GenSigTimeoutTime_HU_High_X451" SG_ 960 TimeZone 2500;
BA_ "GenSigTimeoutTime_HU_B" SG_ 960 TimeZone 2500;
BA_ "GenSigTimeoutTime_HU_A" SG_ 960 TimeZone 2500;
BA_ "GenSigTimeoutMsg_HU_Mid_X451" SG_ 960 TimeZone 2500;
BA_ "GenSigTimeoutMsg_HU_High_X451" SG_ 960 TimeZone 2500;
BA_ "GenSigTimeoutMsg_HU_B" SG_ 960 TimeZone 2500;
BA_ "GenSigTimeoutMsg_HU_A" SG_ 960 TimeZone 2500;
BA_ "GenSigSendType" SG_ 960 TimeZone 7;
BA_ "GenSigCycleTimeActive" SG_ 960 TimeZone 500;
BA_ "GenSigCycleTime" SG_ 960 TimeZone 500;
BA_ "GenSigTimeoutMsg_HU_High_X445" SG_ 960 TimeZone 2500;
BA_ "GenSigTimeoutMsg_HU_Mid_X445" SG_ 960 TimeZone 2500;
BA_ "GenSigTimeoutTime_HU_High_X445" SG_ 960 TimeZone 2500;
BA_ "GenSigTimeoutTime_HU_Mid_X445" SG_ 960 TimeZone 2500;
BA_ "GenSigTimeoutMsg_IVI" SG_ 960 TimeZone 2500;
BA_ "GenSigTimeoutTime_IVI" SG_ 960 TimeZone 2500;
BA_ "GenSigTimeoutTime_HU_Mid_X451" SG_ 960 GSmSignalType 2500;
BA_ "GenSigTimeoutTime_HU_High_X451" SG_ 960 GSmSignalType 2500;
BA_ "GenSigTimeoutTime_HU_B" SG_ 960 GSmSignalType 2500;
BA_ "GenSigTimeoutTime_HU_A" SG_ 960 GSmSignalType 2500;
BA_ "GenSigTimeoutMsg_HU_Mid_X451" SG_ 960 GSmSignalType 2500;
BA_ "GenSigTimeoutMsg_HU_High_X451" SG_ 960 GSmSignalType 2500;
BA_ "GenSigTimeoutMsg_HU_B" SG_ 960 GSmSignalType 2500;
BA_ "GenSigTimeoutMsg_HU_A" SG_ 960 GSmSignalType 2500;
BA_ "GenSigSendType" SG_ 960 GSmSignalType 7;
BA_ "GenSigCycleTimeActive" SG_ 960 GSmSignalType 500;
BA_ "GenSigCycleTime" SG_ 960 GSmSignalType 500;
BA_ "GenSigTimeoutMsg_HU_High_X445" SG_ 960 GSmSignalType 2500;
BA_ "GenSigTimeoutMsg_HU_Mid_X445" SG_ 960 GSmSignalType 2500;
BA_ "GenSigTimeoutTime_HU_High_X445" SG_ 960 GSmSignalType 2500;
BA_ "GenSigTimeoutTime_HU_Mid_X445" SG_ 960 GSmSignalType 2500;
BA_ "GenSigTimeoutMsg_IVI" SG_ 960 GSmSignalType 2500;
BA_ "GenSigTimeoutTime_IVI" SG_ 960 GSmSignalType 2500;
BA_ "GenSigTimeoutTime_HU_Mid_X451" SG_ 960 GSmSignalStrength 2500;
BA_ "GenSigTimeoutTime_HU_High_X451" SG_ 960 GSmSignalStrength 2500;
BA_ "GenSigTimeoutTime_HU_B" SG_ 960 GSmSignalStrength 2500;
BA_ "GenSigTimeoutTime_HU_A" SG_ 960 GSmSignalStrength 2500;
BA_ "GenSigTimeoutMsg_HU_Mid_X451" SG_ 960 GSmSignalStrength 2500;
BA_ "GenSigTimeoutMsg_HU_High_X451" SG_ 960 GSmSignalStrength 2500;
BA_ "GenSigTimeoutMsg_HU_B" SG_ 960 GSmSignalStrength 2500;
BA_ "GenSigTimeoutMsg_HU_A" SG_ 960 GSmSignalStrength 2500;
BA_ "GenSigSendType" SG_ 960 GSmSignalStrength 7;
BA_ "GenSigCycleTimeActive" SG_ 960 GSmSignalStrength 500;
BA_ "GenSigCycleTime" SG_ 960 GSmSignalStrength 500;
BA_ "GenSigTimeoutMsg_HU_High_X445" SG_ 960 GSmSignalStrength 2500;
BA_ "GenSigTimeoutMsg_HU_Mid_X445" SG_ 960 GSmSignalStrength 2500;
BA_ "GenSigTimeoutTime_HU_High_X445" SG_ 960 GSmSignalStrength 2500;
BA_ "GenSigTimeoutTime_HU_Mid_X445" SG_ 960 GSmSignalStrength 2500;
BA_ "GenSigTimeoutMsg_IVI" SG_ 960 GSmSignalStrength 2500;
BA_ "GenSigTimeoutTime_IVI" SG_ 960 GSmSignalStrength 2500;
BA_ "GenSigTimeoutTime_HU_Mid_X451" SG_ 960 GSmSignalStatus 2500;
BA_ "GenSigTimeoutTime_HU_High_X451" SG_ 960 GSmSignalStatus 2500;
BA_ "GenSigTimeoutTime_HU_B" SG_ 960 GSmSignalStatus 2500;
BA_ "GenSigTimeoutTime_HU_A" SG_ 960 GSmSignalStatus 2500;
BA_ "GenSigTimeoutMsg_HU_Mid_X451" SG_ 960 GSmSignalStatus 2500;
BA_ "GenSigTimeoutMsg_HU_High_X451" SG_ 960 GSmSignalStatus 2500;
BA_ "GenSigTimeoutMsg_HU_B" SG_ 960 GSmSignalStatus 2500;
BA_ "GenSigTimeoutMsg_HU_A" SG_ 960 GSmSignalStatus 2500;
BA_ "GenSigSendType" SG_ 960 GSmSignalStatus 7;
BA_ "GenSigCycleTimeActive" SG_ 960 GSmSignalStatus 500;
BA_ "GenSigCycleTime" SG_ 960 GSmSignalStatus 500;
BA_ "GenSigTimeoutMsg_HU_High_X445" SG_ 960 GSmSignalStatus 2500;
BA_ "GenSigTimeoutMsg_HU_Mid_X445" SG_ 960 GSmSignalStatus 2500;
BA_ "GenSigTimeoutTime_HU_High_X445" SG_ 960 GSmSignalStatus 2500;
BA_ "GenSigTimeoutTime_HU_Mid_X445" SG_ 960 GSmSignalStatus 2500;
BA_ "GenSigTimeoutMsg_IVI" SG_ 960 GSmSignalStatus 2500;
BA_ "GenSigTimeoutTime_IVI" SG_ 960 GSmSignalStatus 2500;
BA_ "GenSigTimeoutTime_HU_Mid_X451" SG_ 960 GPsFix 2500;
BA_ "GenSigTimeoutTime_HU_High_X451" SG_ 960 GPsFix 2500;
BA_ "GenSigTimeoutTime_HU_B" SG_ 960 GPsFix 2500;
BA_ "GenSigTimeoutTime_HU_A" SG_ 960 GPsFix 2500;
BA_ "GenSigTimeoutMsg_HU_Mid_X451" SG_ 960 GPsFix 2500;
BA_ "GenSigTimeoutMsg_HU_High_X451" SG_ 960 GPsFix 2500;
BA_ "GenSigTimeoutMsg_HU_B" SG_ 960 GPsFix 2500;
BA_ "GenSigTimeoutMsg_HU_A" SG_ 960 GPsFix 2500;
BA_ "GenSigSendType" SG_ 960 GPsFix 7;
BA_ "GenSigCycleTimeActive" SG_ 960 GPsFix 500;
BA_ "GenSigCycleTime" SG_ 960 GPsFix 500;
BA_ "GenSigTimeoutMsg_HU_High_X445" SG_ 960 GPsFix 2500;
BA_ "GenSigTimeoutMsg_HU_Mid_X445" SG_ 960 GPsFix 2500;
BA_ "GenSigTimeoutTime_HU_High_X445" SG_ 960 GPsFix 2500;
BA_ "GenSigTimeoutTime_HU_Mid_X445" SG_ 960 GPsFix 2500;
BA_ "GenSigTimeoutMsg_IVI" SG_ 960 GPsFix 2500;
BA_ "GenSigTimeoutTime_IVI" SG_ 960 GPsFix 2500;
BA_ "GenSigTimeoutTime_HU_Mid_X451" SG_ 960 DateTimeYear 2500;
BA_ "GenSigTimeoutTime_HU_High_X451" SG_ 960 DateTimeYear 2500;
BA_ "GenSigTimeoutTime_HU_B" SG_ 960 DateTimeYear 2500;
BA_ "GenSigTimeoutTime_HU_A" SG_ 960 DateTimeYear 2500;
BA_ "GenSigTimeoutMsg_HU_Mid_X451" SG_ 960 DateTimeYear 2500;
BA_ "GenSigTimeoutMsg_HU_High_X451" SG_ 960 DateTimeYear 2500;
BA_ "GenSigTimeoutMsg_HU_B" SG_ 960 DateTimeYear 2500;
BA_ "GenSigTimeoutMsg_HU_A" SG_ 960 DateTimeYear 2500;
BA_ "GenSigSendType" SG_ 960 DateTimeYear 7;
BA_ "GenSigCycleTimeActive" SG_ 960 DateTimeYear 500;
BA_ "GenSigCycleTime" SG_ 960 DateTimeYear 500;
BA_ "GenSigTimeoutMsg_HU_High_X445" SG_ 960 DateTimeYear 2500;
BA_ "GenSigTimeoutMsg_HU_Mid_X445" SG_ 960 DateTimeYear 2500;
BA_ "GenSigTimeoutTime_HU_High_X445" SG_ 960 DateTimeYear 2500;
BA_ "GenSigTimeoutTime_HU_Mid_X445" SG_ 960 DateTimeYear 2500;
BA_ "GenSigTimeoutMsg_IVI" SG_ 960 DateTimeYear 2500;
BA_ "GenSigTimeoutTime_IVI" SG_ 960 DateTimeYear 2500;
BA_ "GenSigTimeoutTime_HU_Mid_X451" SG_ 960 DateTimeStatus 2500;
BA_ "GenSigTimeoutTime_HU_High_X451" SG_ 960 DateTimeStatus 2500;
BA_ "GenSigTimeoutTime_HU_B" SG_ 960 DateTimeStatus 2500;
BA_ "GenSigTimeoutTime_HU_A" SG_ 960 DateTimeStatus 2500;
BA_ "GenSigTimeoutMsg_HU_Mid_X451" SG_ 960 DateTimeStatus 2500;
BA_ "GenSigTimeoutMsg_HU_High_X451" SG_ 960 DateTimeStatus 2500;
BA_ "GenSigTimeoutMsg_HU_B" SG_ 960 DateTimeStatus 2500;
BA_ "GenSigTimeoutMsg_HU_A" SG_ 960 DateTimeStatus 2500;
BA_ "GenSigSendType" SG_ 960 DateTimeStatus 7;
BA_ "GenSigCycleTimeActive" SG_ 960 DateTimeStatus 500;
BA_ "GenSigCycleTime" SG_ 960 DateTimeStatus 500;
BA_ "GenSigTimeoutMsg_HU_High_X445" SG_ 960 DateTimeStatus 2500;
BA_ "GenSigTimeoutMsg_HU_Mid_X445" SG_ 960 DateTimeStatus 2500;
BA_ "GenSigTimeoutTime_HU_High_X445" SG_ 960 DateTimeStatus 2500;
BA_ "GenSigTimeoutTime_HU_Mid_X445" SG_ 960 DateTimeStatus 2500;
BA_ "GenSigTimeoutMsg_IVI" SG_ 960 DateTimeStatus 2500;
BA_ "GenSigTimeoutTime_IVI" SG_ 960 DateTimeStatus 2500;
BA_ "GenSigTimeoutTime_HU_Mid_X451" SG_ 960 DateTimeSeconds 2500;
BA_ "GenSigTimeoutTime_HU_High_X451" SG_ 960 DateTimeSeconds 2500;
BA_ "GenSigTimeoutTime_HU_B" SG_ 960 DateTimeSeconds 2500;
BA_ "GenSigTimeoutTime_HU_A" SG_ 960 DateTimeSeconds 2500;
BA_ "GenSigTimeoutMsg_HU_Mid_X451" SG_ 960 DateTimeSeconds 2500;
BA_ "GenSigTimeoutMsg_HU_High_X451" SG_ 960 DateTimeSeconds 2500;
BA_ "GenSigTimeoutMsg_HU_B" SG_ 960 DateTimeSeconds 2500;
BA_ "GenSigTimeoutMsg_HU_A" SG_ 960 DateTimeSeconds 2500;
BA_ "GenSigSendType" SG_ 960 DateTimeSeconds 7;
BA_ "GenSigCycleTimeActive" SG_ 960 DateTimeSeconds 500;
BA_ "GenSigCycleTime" SG_ 960 DateTimeSeconds 500;
BA_ "GenSigTimeoutMsg_HU_High_X445" SG_ 960 DateTimeSeconds 2500;
BA_ "GenSigTimeoutMsg_HU_Mid_X445" SG_ 960 DateTimeSeconds 2500;
BA_ "GenSigTimeoutTime_HU_High_X445" SG_ 960 DateTimeSeconds 2500;
BA_ "GenSigTimeoutTime_HU_Mid_X445" SG_ 960 DateTimeSeconds 2500;
BA_ "GenSigTimeoutMsg_IVI" SG_ 960 DateTimeSeconds 2500;
BA_ "GenSigTimeoutTime_IVI" SG_ 960 DateTimeSeconds 2500;
BA_ "GenSigTimeoutTime_HU_Mid_X451" SG_ 960 DateTimeMonth 2500;
BA_ "GenSigTimeoutTime_HU_High_X451" SG_ 960 DateTimeMonth 2500;
BA_ "GenSigTimeoutTime_HU_B" SG_ 960 DateTimeMonth 2500;
BA_ "GenSigTimeoutTime_HU_A" SG_ 960 DateTimeMonth 2500;
BA_ "GenSigTimeoutMsg_HU_Mid_X451" SG_ 960 DateTimeMonth 2500;
BA_ "GenSigTimeoutMsg_HU_High_X451" SG_ 960 DateTimeMonth 2500;
BA_ "GenSigTimeoutMsg_HU_B" SG_ 960 DateTimeMonth 2500;
BA_ "GenSigTimeoutMsg_HU_A" SG_ 960 DateTimeMonth 2500;
BA_ "GenSigSendType" SG_ 960 DateTimeMonth 7;
BA_ "GenSigCycleTimeActive" SG_ 960 DateTimeMonth 500;
BA_ "GenSigCycleTime" SG_ 960 DateTimeMonth 500;
BA_ "GenSigTimeoutMsg_HU_High_X445" SG_ 960 DateTimeMonth 2500;
BA_ "GenSigTimeoutMsg_HU_Mid_X445" SG_ 960 DateTimeMonth 2500;
BA_ "GenSigTimeoutTime_HU_High_X445" SG_ 960 DateTimeMonth 2500;
BA_ "GenSigTimeoutTime_HU_Mid_X445" SG_ 960 DateTimeMonth 2500;
BA_ "GenSigTimeoutMsg_IVI" SG_ 960 DateTimeMonth 2500;
BA_ "GenSigTimeoutTime_IVI" SG_ 960 DateTimeMonth 2500;
BA_ "GenSigTimeoutTime_HU_Mid_X451" SG_ 960 DateTimeMinute 2500;
BA_ "GenSigTimeoutTime_HU_High_X451" SG_ 960 DateTimeMinute 2500;
BA_ "GenSigTimeoutTime_HU_B" SG_ 960 DateTimeMinute 2500;
BA_ "GenSigTimeoutTime_HU_A" SG_ 960 DateTimeMinute 2500;
BA_ "GenSigTimeoutMsg_HU_Mid_X451" SG_ 960 DateTimeMinute 2500;
BA_ "GenSigTimeoutMsg_HU_High_X451" SG_ 960 DateTimeMinute 2500;
BA_ "GenSigTimeoutMsg_HU_B" SG_ 960 DateTimeMinute 2500;
BA_ "GenSigTimeoutMsg_HU_A" SG_ 960 DateTimeMinute 2500;
BA_ "GenSigSendType" SG_ 960 DateTimeMinute 7;
BA_ "GenSigCycleTimeActive" SG_ 960 DateTimeMinute 500;
BA_ "GenSigCycleTime" SG_ 960 DateTimeMinute 500;
BA_ "GenSigTimeoutMsg_HU_High_X445" SG_ 960 DateTimeMinute 2500;
BA_ "GenSigTimeoutMsg_HU_Mid_X445" SG_ 960 DateTimeMinute 2500;
BA_ "GenSigTimeoutTime_HU_High_X445" SG_ 960 DateTimeMinute 2500;
BA_ "GenSigTimeoutTime_HU_Mid_X445" SG_ 960 DateTimeMinute 2500;
BA_ "GenSigTimeoutMsg_IVI" SG_ 960 DateTimeMinute 2500;
BA_ "GenSigTimeoutTime_IVI" SG_ 960 DateTimeMinute 2500;
BA_ "GenSigTimeoutTime_HU_Mid_X451" SG_ 960 DateTimeHour 2500;
BA_ "GenSigTimeoutTime_HU_High_X451" SG_ 960 DateTimeHour 2500;
BA_ "GenSigTimeoutTime_HU_B" SG_ 960 DateTimeHour 2500;
BA_ "GenSigTimeoutTime_HU_A" SG_ 960 DateTimeHour 2500;
BA_ "GenSigTimeoutMsg_HU_Mid_X451" SG_ 960 DateTimeHour 2500;
BA_ "GenSigTimeoutMsg_HU_High_X451" SG_ 960 DateTimeHour 2500;
BA_ "GenSigTimeoutMsg_HU_B" SG_ 960 DateTimeHour 2500;
BA_ "GenSigTimeoutMsg_HU_A" SG_ 960 DateTimeHour 2500;
BA_ "GenSigSendType" SG_ 960 DateTimeHour 7;
BA_ "GenSigCycleTimeActive" SG_ 960 DateTimeHour 500;
BA_ "GenSigCycleTime" SG_ 960 DateTimeHour 500;
BA_ "GenSigTimeoutMsg_HU_High_X445" SG_ 960 DateTimeHour 2500;
BA_ "GenSigTimeoutMsg_HU_Mid_X445" SG_ 960 DateTimeHour 2500;
BA_ "GenSigTimeoutTime_HU_High_X445" SG_ 960 DateTimeHour 2500;
BA_ "GenSigTimeoutTime_HU_Mid_X445" SG_ 960 DateTimeHour 2500;
BA_ "GenSigTimeoutMsg_IVI" SG_ 960 DateTimeHour 2500;
BA_ "GenSigTimeoutTime_IVI" SG_ 960 DateTimeHour 2500;
BA_ "GenSigTimeoutTime_HU_Mid_X451" SG_ 960 DateTimeDay 2500;
BA_ "GenSigTimeoutTime_HU_High_X451" SG_ 960 DateTimeDay 2500;
BA_ "GenSigTimeoutTime_HU_B" SG_ 960 DateTimeDay 2500;
BA_ "GenSigTimeoutTime_HU_A" SG_ 960 DateTimeDay 2500;
BA_ "GenSigTimeoutMsg_HU_Mid_X451" SG_ 960 DateTimeDay 2500;
BA_ "GenSigTimeoutMsg_HU_High_X451" SG_ 960 DateTimeDay 2500;
BA_ "GenSigTimeoutMsg_HU_B" SG_ 960 DateTimeDay 2500;
BA_ "GenSigTimeoutMsg_HU_A" SG_ 960 DateTimeDay 2500;
BA_ "GenSigSendType" SG_ 960 DateTimeDay 7;
BA_ "GenSigCycleTimeActive" SG_ 960 DateTimeDay 500;
BA_ "GenSigCycleTime" SG_ 960 DateTimeDay 500;
BA_ "GenSigTimeoutMsg_HU_High_X445" SG_ 960 DateTimeDay 2500;
BA_ "GenSigTimeoutMsg_HU_Mid_X445" SG_ 960 DateTimeDay 2500;
BA_ "GenSigTimeoutTime_HU_High_X445" SG_ 960 DateTimeDay 2500;
BA_ "GenSigTimeoutTime_HU_Mid_X445" SG_ 960 DateTimeDay 2500;
BA_ "GenSigTimeoutMsg_IVI" SG_ 960 DateTimeDay 2500;
BA_ "GenSigTimeoutTime_IVI" SG_ 960 DateTimeDay 2500;
BA_ "GenSigTimeoutTime_HU_Mid_X451" SG_ 960 GPsCourseInfoStatus 2500;
BA_ "GenSigTimeoutTime_HU_High_X451" SG_ 960 GPsCourseInfoStatus 2500;
BA_ "GenSigTimeoutTime_HU_B" SG_ 960 GPsCourseInfoStatus 2500;
BA_ "GenSigTimeoutTime_HU_A" SG_ 960 GPsCourseInfoStatus 2500;
BA_ "GenSigTimeoutMsg_HU_Mid_X451" SG_ 960 GPsCourseInfoStatus 2500;
BA_ "GenSigTimeoutMsg_HU_High_X451" SG_ 960 GPsCourseInfoStatus 2500;
BA_ "GenSigTimeoutMsg_HU_B" SG_ 960 GPsCourseInfoStatus 2500;
BA_ "GenSigTimeoutMsg_HU_A" SG_ 960 GPsCourseInfoStatus 2500;
BA_ "GenSigSendType" SG_ 960 GPsCourseInfoStatus 7;
BA_ "GenSigCycleTimeActive" SG_ 960 GPsCourseInfoStatus 500;
BA_ "GenSigCycleTime" SG_ 960 GPsCourseInfoStatus 500;
BA_ "GenSigTimeoutMsg_HU_High_X445" SG_ 960 GPsCourseInfoStatus 2500;
BA_ "GenSigTimeoutMsg_HU_Mid_X445" SG_ 960 GPsCourseInfoStatus 2500;
BA_ "GenSigTimeoutTime_HU_High_X445" SG_ 960 GPsCourseInfoStatus 2500;
BA_ "GenSigTimeoutTime_HU_Mid_X445" SG_ 960 GPsCourseInfoStatus 2500;
BA_ "GenSigTimeoutMsg_IVI" SG_ 960 GPsCourseInfoStatus 2500;
BA_ "GenSigTimeoutTime_IVI" SG_ 960 GPsCourseInfoStatus 2500;
BA_ "GenSigTimeoutTime_HU_Mid_X451" SG_ 960 GPsCourseInfo 2500;
BA_ "GenSigTimeoutTime_HU_High_X451" SG_ 960 GPsCourseInfo 2500;
BA_ "GenSigTimeoutTime_HU_B" SG_ 960 GPsCourseInfo 2500;
BA_ "GenSigTimeoutTime_HU_A" SG_ 960 GPsCourseInfo 2500;
BA_ "GenSigTimeoutMsg_HU_Mid_X451" SG_ 960 GPsCourseInfo 2500;
BA_ "GenSigTimeoutMsg_HU_High_X451" SG_ 960 GPsCourseInfo 2500;
BA_ "GenSigTimeoutMsg_HU_B" SG_ 960 GPsCourseInfo 2500;
BA_ "GenSigTimeoutMsg_HU_A" SG_ 960 GPsCourseInfo 2500;
BA_ "GenSigSendType" SG_ 960 GPsCourseInfo 7;
BA_ "GenSigCycleTimeActive" SG_ 960 GPsCourseInfo 500;
BA_ "GenSigCycleTime" SG_ 960 GPsCourseInfo 500;
BA_ "GenSigTimeoutMsg_HU_High_X445" SG_ 960 GPsCourseInfo 2500;
BA_ "GenSigTimeoutMsg_HU_Mid_X445" SG_ 960 GPsCourseInfo 2500;
BA_ "GenSigTimeoutTime_HU_High_X445" SG_ 960 GPsCourseInfo 2500;
BA_ "GenSigTimeoutTime_HU_Mid_X445" SG_ 960 GPsCourseInfo 2500;
BA_ "GenSigTimeoutMsg_IVI" SG_ 960 GPsCourseInfo 2500;
BA_ "GenSigTimeoutTime_IVI" SG_ 960 GPsCourseInfo 2500;
BA_ "GenSigTimeoutTime_HU_Mid_X451" SG_ 944 TCmHuUsbCommRequest 2500;
BA_ "GenSigTimeoutTime_HU_High_X451" SG_ 944 TCmHuUsbCommRequest 2500;
BA_ "GenSigTimeoutTime_HU_B" SG_ 944 TCmHuUsbCommRequest 2500;
BA_ "GenSigTimeoutTime_HU_A" SG_ 944 TCmHuUsbCommRequest 2500;
BA_ "GenSigTimeoutMsg_HU_Mid_X451" SG_ 944 TCmHuUsbCommRequest 2500;
BA_ "GenSigTimeoutMsg_HU_High_X451" SG_ 944 TCmHuUsbCommRequest 2500;
BA_ "GenSigTimeoutMsg_HU_B" SG_ 944 TCmHuUsbCommRequest 2500;
BA_ "GenSigTimeoutMsg_HU_A" SG_ 944 TCmHuUsbCommRequest 2500;
BA_ "GenSigSendType" SG_ 944 TCmHuUsbCommRequest 7;
BA_ "GenSigCycleTimeActive" SG_ 944 TCmHuUsbCommRequest 500;
BA_ "GenSigCycleTime" SG_ 944 TCmHuUsbCommRequest 500;
BA_ "GenSigTimeoutMsg_HU_High_X445" SG_ 944 TCmHuUsbCommRequest 2500;
BA_ "GenSigTimeoutMsg_HU_Mid_X445" SG_ 944 TCmHuUsbCommRequest 2500;
BA_ "GenSigTimeoutTime_HU_High_X445" SG_ 944 TCmHuUsbCommRequest 2500;
BA_ "GenSigTimeoutTime_HU_Mid_X445" SG_ 944 TCmHuUsbCommRequest 2500;
BA_ "GenSigTimeoutMsg_IVI" SG_ 944 TCmHuUsbCommRequest 2500;
BA_ "GenSigTimeoutTime_IVI" SG_ 944 TCmHuUsbCommRequest 2500;
BA_ "GenSigTimeoutTime_HU_Mid_X451" SG_ 944 TCmHuUsbRoleState 2500;
BA_ "GenSigTimeoutTime_HU_High_X451" SG_ 944 TCmHuUsbRoleState 2500;
BA_ "GenSigTimeoutTime_HU_B" SG_ 944 TCmHuUsbRoleState 2500;
BA_ "GenSigTimeoutTime_HU_A" SG_ 944 TCmHuUsbRoleState 2500;
BA_ "GenSigTimeoutMsg_HU_Mid_X451" SG_ 944 TCmHuUsbRoleState 2500;
BA_ "GenSigTimeoutMsg_HU_High_X451" SG_ 944 TCmHuUsbRoleState 2500;
BA_ "GenSigTimeoutMsg_HU_B" SG_ 944 TCmHuUsbRoleState 2500;
BA_ "GenSigTimeoutMsg_HU_A" SG_ 944 TCmHuUsbRoleState 2500;
BA_ "GenSigSendType" SG_ 944 TCmHuUsbRoleState 7;
BA_ "GenSigCycleTimeActive" SG_ 944 TCmHuUsbRoleState 500;
BA_ "GenSigCycleTime" SG_ 944 TCmHuUsbRoleState 500;
BA_ "GenSigTimeoutMsg_HU_High_X445" SG_ 944 TCmHuUsbRoleState 2500;
BA_ "GenSigTimeoutMsg_HU_Mid_X445" SG_ 944 TCmHuUsbRoleState 2500;
BA_ "GenSigTimeoutTime_HU_High_X445" SG_ 944 TCmHuUsbRoleState 2500;
BA_ "GenSigTimeoutTime_HU_Mid_X445" SG_ 944 TCmHuUsbRoleState 2500;
BA_ "GenSigTimeoutMsg_IVI" SG_ 944 TCmHuUsbRoleState 2500;
BA_ "GenSigTimeoutTime_IVI" SG_ 944 TCmHuUsbRoleState 2500;
BA_ "GenSigTimeoutTime_HU_Mid_X451" SG_ 944 TCmHuUSBCommChannelCapability 2500;
BA_ "GenSigTimeoutTime_HU_High_X451" SG_ 944 TCmHuUSBCommChannelCapability 2500;
BA_ "GenSigTimeoutTime_HU_B" SG_ 944 TCmHuUSBCommChannelCapability 2500;
BA_ "GenSigTimeoutTime_HU_A" SG_ 944 TCmHuUSBCommChannelCapability 2500;
BA_ "GenSigTimeoutMsg_HU_Mid_X451" SG_ 944 TCmHuUSBCommChannelCapability 2500;
BA_ "GenSigTimeoutMsg_HU_High_X451" SG_ 944 TCmHuUSBCommChannelCapability 2500;
BA_ "GenSigTimeoutMsg_HU_B" SG_ 944 TCmHuUSBCommChannelCapability 2500;
BA_ "GenSigTimeoutMsg_HU_A" SG_ 944 TCmHuUSBCommChannelCapability 2500;
BA_ "GenSigSendType" SG_ 944 TCmHuUSBCommChannelCapability 7;
BA_ "GenSigCycleTimeActive" SG_ 944 TCmHuUSBCommChannelCapability 500;
BA_ "GenSigCycleTime" SG_ 944 TCmHuUSBCommChannelCapability 500;
BA_ "GenSigTimeoutMsg_HU_High_X445" SG_ 944 TCmHuUSBCommChannelCapability 2500;
BA_ "GenSigTimeoutMsg_HU_Mid_X445" SG_ 944 TCmHuUSBCommChannelCapability 2500;
BA_ "GenSigTimeoutTime_HU_High_X445" SG_ 944 TCmHuUSBCommChannelCapability 2500;
BA_ "GenSigTimeoutTime_HU_Mid_X445" SG_ 944 TCmHuUSBCommChannelCapability 2500;
BA_ "GenSigTimeoutMsg_IVI" SG_ 944 TCmHuUSBCommChannelCapability 2500;
BA_ "GenSigTimeoutTime_IVI" SG_ 944 TCmHuUSBCommChannelCapability 2500;
BA_ "GenSigTimeoutTime_HU_Mid_X451" SG_ 944 TCmHuReInitPhysicalConnection 2500;
BA_ "GenSigTimeoutTime_HU_High_X451" SG_ 944 TCmHuReInitPhysicalConnection 2500;
BA_ "GenSigTimeoutTime_HU_B" SG_ 944 TCmHuReInitPhysicalConnection 2500;
BA_ "GenSigTimeoutTime_HU_A" SG_ 944 TCmHuReInitPhysicalConnection 2500;
BA_ "GenSigTimeoutMsg_HU_Mid_X451" SG_ 944 TCmHuReInitPhysicalConnection 2500;
BA_ "GenSigTimeoutMsg_HU_High_X451" SG_ 944 TCmHuReInitPhysicalConnection 2500;
BA_ "GenSigTimeoutMsg_HU_B" SG_ 944 TCmHuReInitPhysicalConnection 2500;
BA_ "GenSigTimeoutMsg_HU_A" SG_ 944 TCmHuReInitPhysicalConnection 2500;
BA_ "GenSigSendType" SG_ 944 TCmHuReInitPhysicalConnection 7;
BA_ "GenSigCycleTimeActive" SG_ 944 TCmHuReInitPhysicalConnection 500;
BA_ "GenSigCycleTime" SG_ 944 TCmHuReInitPhysicalConnection 500;
BA_ "GenSigTimeoutMsg_HU_High_X445" SG_ 944 TCmHuReInitPhysicalConnection 2500;
BA_ "GenSigTimeoutMsg_HU_Mid_X445" SG_ 944 TCmHuReInitPhysicalConnection 2500;
BA_ "GenSigTimeoutTime_HU_High_X445" SG_ 944 TCmHuReInitPhysicalConnection 2500;
BA_ "GenSigTimeoutTime_HU_Mid_X445" SG_ 944 TCmHuReInitPhysicalConnection 2500;
BA_ "GenSigTimeoutMsg_IVI" SG_ 944 TCmHuReInitPhysicalConnection 2500;
BA_ "GenSigTimeoutTime_IVI" SG_ 944 TCmHuReInitPhysicalConnection 2500;
BA_ "GenSigTimeoutTime_HU_Mid_X451" SG_ 944 TCmHuEth100BaseTCommChannelCapab 2500;
BA_ "GenSigTimeoutTime_HU_High_X451" SG_ 944 TCmHuEth100BaseTCommChannelCapab 2500;
BA_ "GenSigTimeoutTime_HU_B" SG_ 944 TCmHuEth100BaseTCommChannelCapab 2500;
BA_ "GenSigTimeoutTime_HU_A" SG_ 944 TCmHuEth100BaseTCommChannelCapab 2500;
BA_ "GenSigTimeoutMsg_HU_Mid_X451" SG_ 944 TCmHuEth100BaseTCommChannelCapab 2500;
BA_ "GenSigTimeoutMsg_HU_High_X451" SG_ 944 TCmHuEth100BaseTCommChannelCapab 2500;
BA_ "GenSigTimeoutMsg_HU_B" SG_ 944 TCmHuEth100BaseTCommChannelCapab 2500;
BA_ "GenSigTimeoutMsg_HU_A" SG_ 944 TCmHuEth100BaseTCommChannelCapab 2500;
BA_ "GenSigSendType" SG_ 944 TCmHuEth100BaseTCommChannelCapab 7;
BA_ "GenSigCycleTimeActive" SG_ 944 TCmHuEth100BaseTCommChannelCapab 500;
BA_ "GenSigCycleTime" SG_ 944 TCmHuEth100BaseTCommChannelCapab 500;
BA_ "GenSigTimeoutMsg_HU_High_X445" SG_ 944 TCmHuEth100BaseTCommChannelCapab 2500;
BA_ "GenSigTimeoutMsg_HU_Mid_X445" SG_ 944 TCmHuEth100BaseTCommChannelCapab 2500;
BA_ "GenSigTimeoutTime_HU_High_X445" SG_ 944 TCmHuEth100BaseTCommChannelCapab 2500;
BA_ "GenSigTimeoutTime_HU_Mid_X445" SG_ 944 TCmHuEth100BaseTCommChannelCapab 2500;
BA_ "GenSigTimeoutMsg_IVI" SG_ 944 TCmHuEth100BaseTCommChannelCapab 2500;
BA_ "GenSigTimeoutTime_IVI" SG_ 944 TCmHuEth100BaseTCommChannelCapab 2500;
BA_ "SystemSignalLongSymbol" SG_ 944 TCmHuEth100BaseTCommChannelCapab "TCmHuEth100BaseTCommChannelCapability";
BA_ "GenSigTimeoutTime_HU_Mid_X451" SG_ 944 TCmHuEth1000BaseTCommChannelCapa 2500;
BA_ "GenSigTimeoutTime_HU_High_X451" SG_ 944 TCmHuEth1000BaseTCommChannelCapa 2500;
BA_ "GenSigTimeoutTime_HU_B" SG_ 944 TCmHuEth1000BaseTCommChannelCapa 2500;
BA_ "GenSigTimeoutTime_HU_A" SG_ 944 TCmHuEth1000BaseTCommChannelCapa 2500;
BA_ "GenSigTimeoutMsg_HU_Mid_X451" SG_ 944 TCmHuEth1000BaseTCommChannelCapa 2500;
BA_ "GenSigTimeoutMsg_HU_High_X451" SG_ 944 TCmHuEth1000BaseTCommChannelCapa 2500;
BA_ "GenSigTimeoutMsg_HU_B" SG_ 944 TCmHuEth1000BaseTCommChannelCapa 2500;
BA_ "GenSigTimeoutMsg_HU_A" SG_ 944 TCmHuEth1000BaseTCommChannelCapa 2500;
BA_ "GenSigSendType" SG_ 944 TCmHuEth1000BaseTCommChannelCapa 7;
BA_ "GenSigCycleTimeActive" SG_ 944 TCmHuEth1000BaseTCommChannelCapa 500;
BA_ "GenSigCycleTime" SG_ 944 TCmHuEth1000BaseTCommChannelCapa 500;
BA_ "GenSigTimeoutMsg_HU_High_X445" SG_ 944 TCmHuEth1000BaseTCommChannelCapa 2500;
BA_ "GenSigTimeoutMsg_HU_Mid_X445" SG_ 944 TCmHuEth1000BaseTCommChannelCapa 2500;
BA_ "GenSigTimeoutTime_HU_High_X445" SG_ 944 TCmHuEth1000BaseTCommChannelCapa 2500;
BA_ "GenSigTimeoutTime_HU_Mid_X445" SG_ 944 TCmHuEth1000BaseTCommChannelCapa 2500;
BA_ "GenSigTimeoutMsg_IVI" SG_ 944 TCmHuEth1000BaseTCommChannelCapa 2500;
BA_ "GenSigTimeoutTime_IVI" SG_ 944 TCmHuEth1000BaseTCommChannelCapa 2500;
BA_ "SystemSignalLongSymbol" SG_ 944 TCmHuEth1000BaseTCommChannelCapa "TCmHuEth1000BaseTCommChannelCapability";
BA_ "GenSigTimeoutTime_HU_Mid_X451" SG_ 944 TCmHuErrorDiagnostic 2500;
BA_ "GenSigTimeoutTime_HU_High_X451" SG_ 944 TCmHuErrorDiagnostic 2500;
BA_ "GenSigTimeoutTime_HU_B" SG_ 944 TCmHuErrorDiagnostic 2500;
BA_ "GenSigTimeoutTime_HU_A" SG_ 944 TCmHuErrorDiagnostic 2500;
BA_ "GenSigTimeoutMsg_HU_Mid_X451" SG_ 944 TCmHuErrorDiagnostic 2500;
BA_ "GenSigTimeoutMsg_HU_High_X451" SG_ 944 TCmHuErrorDiagnostic 2500;
BA_ "GenSigTimeoutMsg_HU_B" SG_ 944 TCmHuErrorDiagnostic 2500;
BA_ "GenSigTimeoutMsg_HU_A" SG_ 944 TCmHuErrorDiagnostic 2500;
BA_ "GenSigSendType" SG_ 944 TCmHuErrorDiagnostic 7;
BA_ "GenSigCycleTimeActive" SG_ 944 TCmHuErrorDiagnostic 500;
BA_ "GenSigCycleTime" SG_ 944 TCmHuErrorDiagnostic 500;
BA_ "GenSigTimeoutMsg_HU_High_X445" SG_ 944 TCmHuErrorDiagnostic 2500;
BA_ "GenSigTimeoutMsg_HU_Mid_X445" SG_ 944 TCmHuErrorDiagnostic 2500;
BA_ "GenSigTimeoutTime_HU_High_X445" SG_ 944 TCmHuErrorDiagnostic 2500;
BA_ "GenSigTimeoutTime_HU_Mid_X445" SG_ 944 TCmHuErrorDiagnostic 2500;
BA_ "GenSigTimeoutMsg_IVI" SG_ 944 TCmHuErrorDiagnostic 2500;
BA_ "GenSigTimeoutTime_IVI" SG_ 944 TCmHuErrorDiagnostic 2500;
BA_ "GenSigTimeoutTime_HU_Mid_X451" SG_ 944 TCmHuCommInterfaceState 2500;
BA_ "GenSigTimeoutTime_HU_High_X451" SG_ 944 TCmHuCommInterfaceState 2500;
BA_ "GenSigTimeoutTime_HU_B" SG_ 944 TCmHuCommInterfaceState 2500;
BA_ "GenSigTimeoutTime_HU_A" SG_ 944 TCmHuCommInterfaceState 2500;
BA_ "GenSigTimeoutMsg_HU_Mid_X451" SG_ 944 TCmHuCommInterfaceState 2500;
BA_ "GenSigTimeoutMsg_HU_High_X451" SG_ 944 TCmHuCommInterfaceState 2500;
BA_ "GenSigTimeoutMsg_HU_B" SG_ 944 TCmHuCommInterfaceState 2500;
BA_ "GenSigTimeoutMsg_HU_A" SG_ 944 TCmHuCommInterfaceState 2500;
BA_ "GenSigSendType" SG_ 944 TCmHuCommInterfaceState 7;
BA_ "GenSigCycleTimeActive" SG_ 944 TCmHuCommInterfaceState 500;
BA_ "GenSigCycleTime" SG_ 944 TCmHuCommInterfaceState 500;
BA_ "GenSigTimeoutMsg_HU_High_X445" SG_ 944 TCmHuCommInterfaceState 2500;
BA_ "GenSigTimeoutMsg_HU_Mid_X445" SG_ 944 TCmHuCommInterfaceState 2500;
BA_ "GenSigTimeoutTime_HU_High_X445" SG_ 944 TCmHuCommInterfaceState 2500;
BA_ "GenSigTimeoutTime_HU_Mid_X445" SG_ 944 TCmHuCommInterfaceState 2500;
BA_ "GenSigTimeoutMsg_IVI" SG_ 944 TCmHuCommInterfaceState 2500;
BA_ "GenSigTimeoutTime_IVI" SG_ 944 TCmHuCommInterfaceState 2500;
BA_ "GenSigTimeoutTime_HU_Mid_X451" SG_ 944 TCmHuChangeRoleRequest 2500;
BA_ "GenSigTimeoutTime_HU_High_X451" SG_ 944 TCmHuChangeRoleRequest 2500;
BA_ "GenSigTimeoutTime_HU_B" SG_ 944 TCmHuChangeRoleRequest 2500;
BA_ "GenSigTimeoutTime_HU_A" SG_ 944 TCmHuChangeRoleRequest 2500;
BA_ "GenSigTimeoutMsg_HU_Mid_X451" SG_ 944 TCmHuChangeRoleRequest 2500;
BA_ "GenSigTimeoutMsg_HU_High_X451" SG_ 944 TCmHuChangeRoleRequest 2500;
BA_ "GenSigTimeoutMsg_HU_B" SG_ 944 TCmHuChangeRoleRequest 2500;
BA_ "GenSigTimeoutMsg_HU_A" SG_ 944 TCmHuChangeRoleRequest 2500;
BA_ "GenSigSendType" SG_ 944 TCmHuChangeRoleRequest 7;
BA_ "GenSigCycleTimeActive" SG_ 944 TCmHuChangeRoleRequest 500;
BA_ "GenSigCycleTime" SG_ 944 TCmHuChangeRoleRequest 500;
BA_ "GenSigTimeoutMsg_HU_High_X445" SG_ 944 TCmHuChangeRoleRequest 2500;
BA_ "GenSigTimeoutMsg_HU_Mid_X445" SG_ 944 TCmHuChangeRoleRequest 2500;
BA_ "GenSigTimeoutTime_HU_High_X445" SG_ 944 TCmHuChangeRoleRequest 2500;
BA_ "GenSigTimeoutTime_HU_Mid_X445" SG_ 944 TCmHuChangeRoleRequest 2500;
BA_ "GenSigTimeoutMsg_IVI" SG_ 944 TCmHuChangeRoleRequest 2500;
BA_ "GenSigTimeoutTime_IVI" SG_ 944 TCmHuChangeRoleRequest 2500;
BA_ "GenSigTimeoutTime_HU_Mid_X451" SG_ 944 TCmHuAuthenticationState 2500;
BA_ "GenSigTimeoutTime_HU_High_X451" SG_ 944 TCmHuAuthenticationState 2500;
BA_ "GenSigTimeoutTime_HU_B" SG_ 944 TCmHuAuthenticationState 2500;
BA_ "GenSigTimeoutTime_HU_A" SG_ 944 TCmHuAuthenticationState 2500;
BA_ "GenSigTimeoutMsg_HU_Mid_X451" SG_ 944 TCmHuAuthenticationState 2500;
BA_ "GenSigTimeoutMsg_HU_High_X451" SG_ 944 TCmHuAuthenticationState 2500;
BA_ "GenSigTimeoutMsg_HU_B" SG_ 944 TCmHuAuthenticationState 2500;
BA_ "GenSigTimeoutMsg_HU_A" SG_ 944 TCmHuAuthenticationState 2500;
BA_ "GenSigSendType" SG_ 944 TCmHuAuthenticationState 7;
BA_ "GenSigCycleTimeActive" SG_ 944 TCmHuAuthenticationState 500;
BA_ "GenSigCycleTime" SG_ 944 TCmHuAuthenticationState 500;
BA_ "GenSigTimeoutMsg_HU_High_X445" SG_ 944 TCmHuAuthenticationState 2500;
BA_ "GenSigTimeoutMsg_HU_Mid_X445" SG_ 944 TCmHuAuthenticationState 2500;
BA_ "GenSigTimeoutTime_HU_High_X445" SG_ 944 TCmHuAuthenticationState 2500;
BA_ "GenSigTimeoutTime_HU_Mid_X445" SG_ 944 TCmHuAuthenticationState 2500;
BA_ "GenSigTimeoutMsg_IVI" SG_ 944 TCmHuAuthenticationState 2500;
BA_ "GenSigTimeoutTime_IVI" SG_ 944 TCmHuAuthenticationState 2500;
BA_ "GenSigTimeoutTime_HU_Mid_X451" SG_ 952 HuTcmUsbCommRequest 2500;
BA_ "GenSigTimeoutTime_HU_High_X451" SG_ 952 HuTcmUsbCommRequest 2500;
BA_ "GenSigTimeoutTime_HU_B" SG_ 952 HuTcmUsbCommRequest 2500;
BA_ "GenSigTimeoutTime_HU_A" SG_ 952 HuTcmUsbCommRequest 2500;
BA_ "GenSigTimeoutMsg_HU_Mid_X451" SG_ 952 HuTcmUsbCommRequest 2500;
BA_ "GenSigTimeoutMsg_HU_High_X451" SG_ 952 HuTcmUsbCommRequest 2500;
BA_ "GenSigTimeoutMsg_HU_B" SG_ 952 HuTcmUsbCommRequest 2500;
BA_ "GenSigTimeoutMsg_HU_A" SG_ 952 HuTcmUsbCommRequest 2500;
BA_ "GenSigSendType" SG_ 952 HuTcmUsbCommRequest 7;
BA_ "GenSigCycleTimeActive" SG_ 952 HuTcmUsbCommRequest 500;
BA_ "GenSigCycleTime" SG_ 952 HuTcmUsbCommRequest 500;
BA_ "GenSigTimeoutMsg_HU_High_X445" SG_ 952 HuTcmUsbCommRequest 2500;
BA_ "GenSigTimeoutMsg_HU_Mid_X445" SG_ 952 HuTcmUsbCommRequest 2500;
BA_ "GenSigTimeoutTime_HU_High_X445" SG_ 952 HuTcmUsbCommRequest 2500;
BA_ "GenSigTimeoutTime_HU_Mid_X445" SG_ 952 HuTcmUsbCommRequest 2500;
BA_ "GenSigTimeoutMsg_IVI" SG_ 952 HuTcmUsbCommRequest 2500;
BA_ "GenSigTimeoutTime_IVI" SG_ 952 HuTcmUsbCommRequest 2500;
BA_ "GenSigTimeoutTime_HU_Mid_X451" SG_ 952 HuTCmUsbRoleState 2500;
BA_ "GenSigTimeoutTime_HU_High_X451" SG_ 952 HuTCmUsbRoleState 2500;
BA_ "GenSigTimeoutTime_HU_B" SG_ 952 HuTCmUsbRoleState 2500;
BA_ "GenSigTimeoutTime_HU_A" SG_ 952 HuTCmUsbRoleState 2500;
BA_ "GenSigTimeoutMsg_HU_Mid_X451" SG_ 952 HuTCmUsbRoleState 2500;
BA_ "GenSigTimeoutMsg_HU_High_X451" SG_ 952 HuTCmUsbRoleState 2500;
BA_ "GenSigTimeoutMsg_HU_B" SG_ 952 HuTCmUsbRoleState 2500;
BA_ "GenSigTimeoutMsg_HU_A" SG_ 952 HuTCmUsbRoleState 2500;
BA_ "GenSigSendType" SG_ 952 HuTCmUsbRoleState 7;
BA_ "GenSigCycleTimeActive" SG_ 952 HuTCmUsbRoleState 500;
BA_ "GenSigCycleTime" SG_ 952 HuTCmUsbRoleState 500;
BA_ "GenSigTimeoutMsg_HU_High_X445" SG_ 952 HuTCmUsbRoleState 2500;
BA_ "GenSigTimeoutMsg_HU_Mid_X445" SG_ 952 HuTCmUsbRoleState 2500;
BA_ "GenSigTimeoutTime_HU_High_X445" SG_ 952 HuTCmUsbRoleState 2500;
BA_ "GenSigTimeoutTime_HU_Mid_X445" SG_ 952 HuTCmUsbRoleState 2500;
BA_ "GenSigTimeoutMsg_IVI" SG_ 952 HuTCmUsbRoleState 2500;
BA_ "GenSigTimeoutTime_IVI" SG_ 952 HuTCmUsbRoleState 2500;
BA_ "GenSigTimeoutTime_HU_Mid_X451" SG_ 952 HuTCmUSBCommChannelCapability 2500;
BA_ "GenSigTimeoutTime_HU_High_X451" SG_ 952 HuTCmUSBCommChannelCapability 2500;
BA_ "GenSigTimeoutTime_HU_B" SG_ 952 HuTCmUSBCommChannelCapability 2500;
BA_ "GenSigTimeoutTime_HU_A" SG_ 952 HuTCmUSBCommChannelCapability 2500;
BA_ "GenSigTimeoutMsg_HU_Mid_X451" SG_ 952 HuTCmUSBCommChannelCapability 2500;
BA_ "GenSigTimeoutMsg_HU_High_X451" SG_ 952 HuTCmUSBCommChannelCapability 2500;
BA_ "GenSigTimeoutMsg_HU_B" SG_ 952 HuTCmUSBCommChannelCapability 2500;
BA_ "GenSigTimeoutMsg_HU_A" SG_ 952 HuTCmUSBCommChannelCapability 2500;
BA_ "GenSigSendType" SG_ 952 HuTCmUSBCommChannelCapability 7;
BA_ "GenSigCycleTimeActive" SG_ 952 HuTCmUSBCommChannelCapability 500;
BA_ "GenSigCycleTime" SG_ 952 HuTCmUSBCommChannelCapability 500;
BA_ "GenSigTimeoutMsg_HU_High_X445" SG_ 952 HuTCmUSBCommChannelCapability 2500;
BA_ "GenSigTimeoutMsg_HU_Mid_X445" SG_ 952 HuTCmUSBCommChannelCapability 2500;
BA_ "GenSigTimeoutTime_HU_High_X445" SG_ 952 HuTCmUSBCommChannelCapability 2500;
BA_ "GenSigTimeoutTime_HU_Mid_X445" SG_ 952 HuTCmUSBCommChannelCapability 2500;
BA_ "GenSigTimeoutMsg_IVI" SG_ 952 HuTCmUSBCommChannelCapability 2500;
BA_ "GenSigTimeoutTime_IVI" SG_ 952 HuTCmUSBCommChannelCapability 2500;
BA_ "GenSigTimeoutTime_HU_Mid_X451" SG_ 952 HuTCmUSBChangeRoleRequest 2500;
BA_ "GenSigTimeoutTime_HU_High_X451" SG_ 952 HuTCmUSBChangeRoleRequest 2500;
BA_ "GenSigTimeoutTime_HU_B" SG_ 952 HuTCmUSBChangeRoleRequest 2500;
BA_ "GenSigTimeoutTime_HU_A" SG_ 952 HuTCmUSBChangeRoleRequest 2500;
BA_ "GenSigTimeoutMsg_HU_Mid_X451" SG_ 952 HuTCmUSBChangeRoleRequest 2500;
BA_ "GenSigTimeoutMsg_HU_High_X451" SG_ 952 HuTCmUSBChangeRoleRequest 2500;
BA_ "GenSigTimeoutMsg_HU_B" SG_ 952 HuTCmUSBChangeRoleRequest 2500;
BA_ "GenSigTimeoutMsg_HU_A" SG_ 952 HuTCmUSBChangeRoleRequest 2500;
BA_ "GenSigSendType" SG_ 952 HuTCmUSBChangeRoleRequest 7;
BA_ "GenSigCycleTimeActive" SG_ 952 HuTCmUSBChangeRoleRequest 500;
BA_ "GenSigCycleTime" SG_ 952 HuTCmUSBChangeRoleRequest 500;
BA_ "GenSigTimeoutMsg_HU_High_X445" SG_ 952 HuTCmUSBChangeRoleRequest 2500;
BA_ "GenSigTimeoutMsg_HU_Mid_X445" SG_ 952 HuTCmUSBChangeRoleRequest 2500;
BA_ "GenSigTimeoutTime_HU_High_X445" SG_ 952 HuTCmUSBChangeRoleRequest 2500;
BA_ "GenSigTimeoutTime_HU_Mid_X445" SG_ 952 HuTCmUSBChangeRoleRequest 2500;
BA_ "GenSigTimeoutMsg_IVI" SG_ 952 HuTCmUSBChangeRoleRequest 2500;
BA_ "GenSigTimeoutTime_IVI" SG_ 952 HuTCmUSBChangeRoleRequest 2500;
BA_ "GenSigTimeoutTime_HU_Mid_X451" SG_ 952 HuTCmReInitPhysicalConnection 2500;
BA_ "GenSigTimeoutTime_HU_High_X451" SG_ 952 HuTCmReInitPhysicalConnection 2500;
BA_ "GenSigTimeoutTime_HU_B" SG_ 952 HuTCmReInitPhysicalConnection 2500;
BA_ "GenSigTimeoutTime_HU_A" SG_ 952 HuTCmReInitPhysicalConnection 2500;
BA_ "GenSigTimeoutMsg_HU_Mid_X451" SG_ 952 HuTCmReInitPhysicalConnection 2500;
BA_ "GenSigTimeoutMsg_HU_High_X451" SG_ 952 HuTCmReInitPhysicalConnection 2500;
BA_ "GenSigTimeoutMsg_HU_B" SG_ 952 HuTCmReInitPhysicalConnection 2500;
BA_ "GenSigTimeoutMsg_HU_A" SG_ 952 HuTCmReInitPhysicalConnection 2500;
BA_ "GenSigSendType" SG_ 952 HuTCmReInitPhysicalConnection 7;
BA_ "GenSigCycleTimeActive" SG_ 952 HuTCmReInitPhysicalConnection 500;
BA_ "GenSigCycleTime" SG_ 952 HuTCmReInitPhysicalConnection 500;
BA_ "GenSigTimeoutMsg_HU_High_X445" SG_ 952 HuTCmReInitPhysicalConnection 2500;
BA_ "GenSigTimeoutMsg_HU_Mid_X445" SG_ 952 HuTCmReInitPhysicalConnection 2500;
BA_ "GenSigTimeoutTime_HU_High_X445" SG_ 952 HuTCmReInitPhysicalConnection 2500;
BA_ "GenSigTimeoutTime_HU_Mid_X445" SG_ 952 HuTCmReInitPhysicalConnection 2500;
BA_ "GenSigTimeoutMsg_IVI" SG_ 952 HuTCmReInitPhysicalConnection 2500;
BA_ "GenSigTimeoutTime_IVI" SG_ 952 HuTCmReInitPhysicalConnection 2500;
BA_ "GenSigTimeoutTime_HU_Mid_X451" SG_ 952 HuTCmEth100BaseTCommChannelCapab 2500;
BA_ "GenSigTimeoutTime_HU_High_X451" SG_ 952 HuTCmEth100BaseTCommChannelCapab 2500;
BA_ "GenSigTimeoutTime_HU_B" SG_ 952 HuTCmEth100BaseTCommChannelCapab 2500;
BA_ "GenSigTimeoutTime_HU_A" SG_ 952 HuTCmEth100BaseTCommChannelCapab 2500;
BA_ "GenSigTimeoutMsg_HU_Mid_X451" SG_ 952 HuTCmEth100BaseTCommChannelCapab 2500;
BA_ "GenSigTimeoutMsg_HU_High_X451" SG_ 952 HuTCmEth100BaseTCommChannelCapab 2500;
BA_ "GenSigTimeoutMsg_HU_B" SG_ 952 HuTCmEth100BaseTCommChannelCapab 2500;
BA_ "GenSigTimeoutMsg_HU_A" SG_ 952 HuTCmEth100BaseTCommChannelCapab 2500;
BA_ "GenSigSendType" SG_ 952 HuTCmEth100BaseTCommChannelCapab 7;
BA_ "GenSigCycleTimeActive" SG_ 952 HuTCmEth100BaseTCommChannelCapab 500;
BA_ "GenSigCycleTime" SG_ 952 HuTCmEth100BaseTCommChannelCapab 500;
BA_ "GenSigTimeoutMsg_HU_High_X445" SG_ 952 HuTCmEth100BaseTCommChannelCapab 2500;
BA_ "GenSigTimeoutMsg_HU_Mid_X445" SG_ 952 HuTCmEth100BaseTCommChannelCapab 2500;
BA_ "GenSigTimeoutTime_HU_High_X445" SG_ 952 HuTCmEth100BaseTCommChannelCapab 2500;
BA_ "GenSigTimeoutTime_HU_Mid_X445" SG_ 952 HuTCmEth100BaseTCommChannelCapab 2500;
BA_ "GenSigTimeoutMsg_IVI" SG_ 952 HuTCmEth100BaseTCommChannelCapab 2500;
BA_ "GenSigTimeoutTime_IVI" SG_ 952 HuTCmEth100BaseTCommChannelCapab 2500;
BA_ "SystemSignalLongSymbol" SG_ 952 HuTCmEth100BaseTCommChannelCapab "HuTCmEth100BaseTCommChannelCapability";
BA_ "GenSigTimeoutTime_HU_Mid_X451" SG_ 952 HuTCmEth1000BaseTCommChannelCapa 2500;
BA_ "GenSigTimeoutTime_HU_High_X451" SG_ 952 HuTCmEth1000BaseTCommChannelCapa 2500;
BA_ "GenSigTimeoutTime_HU_B" SG_ 952 HuTCmEth1000BaseTCommChannelCapa 2500;
BA_ "GenSigTimeoutTime_HU_A" SG_ 952 HuTCmEth1000BaseTCommChannelCapa 2500;
BA_ "GenSigTimeoutMsg_HU_Mid_X451" SG_ 952 HuTCmEth1000BaseTCommChannelCapa 2500;
BA_ "GenSigTimeoutMsg_HU_High_X451" SG_ 952 HuTCmEth1000BaseTCommChannelCapa 2500;
BA_ "GenSigTimeoutMsg_HU_B" SG_ 952 HuTCmEth1000BaseTCommChannelCapa 2500;
BA_ "GenSigTimeoutMsg_HU_A" SG_ 952 HuTCmEth1000BaseTCommChannelCapa 2500;
BA_ "GenSigSendType" SG_ 952 HuTCmEth1000BaseTCommChannelCapa 7;
BA_ "GenSigCycleTimeActive" SG_ 952 HuTCmEth1000BaseTCommChannelCapa 500;
BA_ "GenSigCycleTime" SG_ 952 HuTCmEth1000BaseTCommChannelCapa 500;
BA_ "GenSigTimeoutMsg_HU_High_X445" SG_ 952 HuTCmEth1000BaseTCommChannelCapa 2500;
BA_ "GenSigTimeoutMsg_HU_Mid_X445" SG_ 952 HuTCmEth1000BaseTCommChannelCapa 2500;
BA_ "GenSigTimeoutTime_HU_High_X445" SG_ 952 HuTCmEth1000BaseTCommChannelCapa 2500;
BA_ "GenSigTimeoutTime_HU_Mid_X445" SG_ 952 HuTCmEth1000BaseTCommChannelCapa 2500;
BA_ "GenSigTimeoutMsg_IVI" SG_ 952 HuTCmEth1000BaseTCommChannelCapa 2500;
BA_ "GenSigTimeoutTime_IVI" SG_ 952 HuTCmEth1000BaseTCommChannelCapa 2500;
BA_ "SystemSignalLongSymbol" SG_ 952 HuTCmEth1000BaseTCommChannelCapa "HuTCmEth1000BaseTCommChannelCapability";
BA_ "GenSigTimeoutTime_HU_Mid_X451" SG_ 952 HuTCmErrorDiagnostic 2500;
BA_ "GenSigTimeoutTime_HU_High_X451" SG_ 952 HuTCmErrorDiagnostic 2500;
BA_ "GenSigTimeoutTime_HU_B" SG_ 952 HuTCmErrorDiagnostic 2500;
BA_ "GenSigTimeoutTime_HU_A" SG_ 952 HuTCmErrorDiagnostic 2500;
BA_ "GenSigTimeoutMsg_HU_Mid_X451" SG_ 952 HuTCmErrorDiagnostic 2500;
BA_ "GenSigTimeoutMsg_HU_High_X451" SG_ 952 HuTCmErrorDiagnostic 2500;
BA_ "GenSigTimeoutMsg_HU_B" SG_ 952 HuTCmErrorDiagnostic 2500;
BA_ "GenSigTimeoutMsg_HU_A" SG_ 952 HuTCmErrorDiagnostic 2500;
BA_ "GenSigSendType" SG_ 952 HuTCmErrorDiagnostic 7;
BA_ "GenSigCycleTimeActive" SG_ 952 HuTCmErrorDiagnostic 500;
BA_ "GenSigCycleTime" SG_ 952 HuTCmErrorDiagnostic 500;
BA_ "GenSigTimeoutMsg_HU_High_X445" SG_ 952 HuTCmErrorDiagnostic 2500;
BA_ "GenSigTimeoutMsg_HU_Mid_X445" SG_ 952 HuTCmErrorDiagnostic 2500;
BA_ "GenSigTimeoutTime_HU_High_X445" SG_ 952 HuTCmErrorDiagnostic 2500;
BA_ "GenSigTimeoutTime_HU_Mid_X445" SG_ 952 HuTCmErrorDiagnostic 2500;
BA_ "GenSigTimeoutMsg_IVI" SG_ 952 HuTCmErrorDiagnostic 2500;
BA_ "GenSigTimeoutTime_IVI" SG_ 952 HuTCmErrorDiagnostic 2500;
BA_ "GenSigTimeoutTime_HU_Mid_X451" SG_ 952 HuTCmCommInterfaceState 2500;
BA_ "GenSigTimeoutTime_HU_High_X451" SG_ 952 HuTCmCommInterfaceState 2500;
BA_ "GenSigTimeoutTime_HU_B" SG_ 952 HuTCmCommInterfaceState 2500;
BA_ "GenSigTimeoutTime_HU_A" SG_ 952 HuTCmCommInterfaceState 2500;
BA_ "GenSigTimeoutMsg_HU_Mid_X451" SG_ 952 HuTCmCommInterfaceState 2500;
BA_ "GenSigTimeoutMsg_HU_High_X451" SG_ 952 HuTCmCommInterfaceState 2500;
BA_ "GenSigTimeoutMsg_HU_B" SG_ 952 HuTCmCommInterfaceState 2500;
BA_ "GenSigTimeoutMsg_HU_A" SG_ 952 HuTCmCommInterfaceState 2500;
BA_ "GenSigSendType" SG_ 952 HuTCmCommInterfaceState 7;
BA_ "GenSigCycleTimeActive" SG_ 952 HuTCmCommInterfaceState 500;
BA_ "GenSigCycleTime" SG_ 952 HuTCmCommInterfaceState 500;
BA_ "GenSigTimeoutMsg_HU_High_X445" SG_ 952 HuTCmCommInterfaceState 2500;
BA_ "GenSigTimeoutMsg_HU_Mid_X445" SG_ 952 HuTCmCommInterfaceState 2500;
BA_ "GenSigTimeoutTime_HU_High_X445" SG_ 952 HuTCmCommInterfaceState 2500;
BA_ "GenSigTimeoutTime_HU_Mid_X445" SG_ 952 HuTCmCommInterfaceState 2500;
BA_ "GenSigTimeoutMsg_IVI" SG_ 952 HuTCmCommInterfaceState 2500;
BA_ "GenSigTimeoutTime_IVI" SG_ 952 HuTCmCommInterfaceState 2500;
BA_ "GenSigTimeoutTime_HU_Mid_X451" SG_ 952 HuTCmAuthenticationState 2500;
BA_ "GenSigTimeoutTime_HU_High_X451" SG_ 952 HuTCmAuthenticationState 2500;
BA_ "GenSigTimeoutTime_HU_B" SG_ 952 HuTCmAuthenticationState 2500;
BA_ "GenSigTimeoutTime_HU_A" SG_ 952 HuTCmAuthenticationState 2500;
BA_ "GenSigTimeoutMsg_HU_Mid_X451" SG_ 952 HuTCmAuthenticationState 2500;
BA_ "GenSigTimeoutMsg_HU_High_X451" SG_ 952 HuTCmAuthenticationState 2500;
BA_ "GenSigTimeoutMsg_HU_B" SG_ 952 HuTCmAuthenticationState 2500;
BA_ "GenSigTimeoutMsg_HU_A" SG_ 952 HuTCmAuthenticationState 2500;
BA_ "GenSigSendType" SG_ 952 HuTCmAuthenticationState 7;
BA_ "GenSigCycleTimeActive" SG_ 952 HuTCmAuthenticationState 500;
BA_ "GenSigCycleTime" SG_ 952 HuTCmAuthenticationState 500;
BA_ "GenSigTimeoutMsg_HU_High_X445" SG_ 952 HuTCmAuthenticationState 2500;
BA_ "GenSigTimeoutMsg_HU_Mid_X445" SG_ 952 HuTCmAuthenticationState 2500;
BA_ "GenSigTimeoutTime_HU_High_X445" SG_ 952 HuTCmAuthenticationState 2500;
BA_ "GenSigTimeoutTime_HU_Mid_X445" SG_ 952 HuTCmAuthenticationState 2500;
BA_ "GenSigTimeoutMsg_IVI" SG_ 952 HuTCmAuthenticationState 2500;
BA_ "GenSigTimeoutTime_IVI" SG_ 952 HuTCmAuthenticationState 2500;
BA_ "GenSigSendType" SG_ 582 SILTelltaleVcuStatus 7;
BA_ "GenSigCycleTimeActive" SG_ 582 SILTelltaleVcuStatus 100;
BA_ "GenSigCycleTime" SG_ 582 SILTelltaleVcuStatus 100;
BA_ "GenSigSendType" SG_ 582 SILTelltaleVcu 7;
BA_ "GenSigCycleTimeActive" SG_ 582 SILTelltaleVcu 100;
BA_ "GenSigCycleTime" SG_ 582 SILTelltaleVcu 100;
BA_ "GenSigSendType" SG_ 582 DcdcRealInputVoltage 7;
BA_ "GenSigCycleTimeActive" SG_ 582 DcdcRealInputVoltage 100;
BA_ "GenSigCycleTime" SG_ 582 DcdcRealInputVoltage 100;
BA_ "GenSigSendType" SG_ 582 HvBattPwrConsmp 7;
BA_ "GenSigCycleTimeActive" SG_ 582 HvBattPwrConsmp 100;
BA_ "GenSigCycleTime" SG_ 582 HvBattPwrConsmp 100;
BA_ "GenSigTimeoutTime_HU_Mid_X451" SG_ 582 AvgEnergyConsmpTripBStatus 0;
BA_ "GenSigTimeoutTime_HU_High_X451" SG_ 582 AvgEnergyConsmpTripBStatus 0;
BA_ "GenSigTimeoutTime_HU_B" SG_ 582 AvgEnergyConsmpTripBStatus 0;
BA_ "GenSigTimeoutTime_HU_A" SG_ 582 AvgEnergyConsmpTripBStatus 0;
BA_ "GenSigTimeoutMsg_HU_Mid_X451" SG_ 582 AvgEnergyConsmpTripBStatus 0;
BA_ "GenSigTimeoutMsg_HU_High_X451" SG_ 582 AvgEnergyConsmpTripBStatus 0;
BA_ "GenSigTimeoutMsg_HU_B" SG_ 582 AvgEnergyConsmpTripBStatus 0;
BA_ "GenSigTimeoutMsg_HU_A" SG_ 582 AvgEnergyConsmpTripBStatus 0;
BA_ "GenSigSendType" SG_ 582 AvgEnergyConsmpTripBStatus 7;
BA_ "GenSigCycleTimeActive" SG_ 582 AvgEnergyConsmpTripBStatus 100;
BA_ "GenSigCycleTime" SG_ 582 AvgEnergyConsmpTripBStatus 100;
BA_ "GenSigTimeoutMsg_HU_High_X445" SG_ 582 AvgEnergyConsmpTripBStatus 0;
BA_ "GenSigTimeoutMsg_HU_Mid_X445" SG_ 582 AvgEnergyConsmpTripBStatus 0;
BA_ "GenSigTimeoutTime_HU_High_X445" SG_ 582 AvgEnergyConsmpTripBStatus 0;
BA_ "GenSigTimeoutTime_HU_Mid_X445" SG_ 582 AvgEnergyConsmpTripBStatus 0;
BA_ "GenSigTimeoutTime_HU_Mid_X451" SG_ 582 AvgEnergyConsmpTripAStatus 0;
BA_ "GenSigTimeoutTime_HU_High_X451" SG_ 582 AvgEnergyConsmpTripAStatus 0;
BA_ "GenSigTimeoutTime_HU_B" SG_ 582 AvgEnergyConsmpTripAStatus 0;
BA_ "GenSigTimeoutTime_HU_A" SG_ 582 AvgEnergyConsmpTripAStatus 0;
BA_ "GenSigTimeoutMsg_HU_Mid_X451" SG_ 582 AvgEnergyConsmpTripAStatus 0;
BA_ "GenSigTimeoutMsg_HU_High_X451" SG_ 582 AvgEnergyConsmpTripAStatus 0;
BA_ "GenSigTimeoutMsg_HU_B" SG_ 582 AvgEnergyConsmpTripAStatus 0;
BA_ "GenSigTimeoutMsg_HU_A" SG_ 582 AvgEnergyConsmpTripAStatus 0;
BA_ "GenSigSendType" SG_ 582 AvgEnergyConsmpTripAStatus 7;
BA_ "GenSigCycleTimeActive" SG_ 582 AvgEnergyConsmpTripAStatus 100;
BA_ "GenSigCycleTime" SG_ 582 AvgEnergyConsmpTripAStatus 100;
BA_ "GenSigTimeoutMsg_HU_High_X445" SG_ 582 AvgEnergyConsmpTripAStatus 0;
BA_ "GenSigTimeoutMsg_HU_Mid_X445" SG_ 582 AvgEnergyConsmpTripAStatus 0;
BA_ "GenSigTimeoutTime_HU_High_X445" SG_ 582 AvgEnergyConsmpTripAStatus 0;
BA_ "GenSigTimeoutTime_HU_Mid_X445" SG_ 582 AvgEnergyConsmpTripAStatus 0;
BA_ "GenSigTimeoutTime_HU_Mid_X451" SG_ 582 AvgEnergyConsmpTripB 0;
BA_ "GenSigTimeoutTime_HU_High_X451" SG_ 582 AvgEnergyConsmpTripB 0;
BA_ "GenSigTimeoutTime_HU_B" SG_ 582 AvgEnergyConsmpTripB 0;
BA_ "GenSigTimeoutTime_HU_A" SG_ 582 AvgEnergyConsmpTripB 0;
BA_ "GenSigTimeoutMsg_HU_Mid_X451" SG_ 582 AvgEnergyConsmpTripB 0;
BA_ "GenSigTimeoutMsg_HU_High_X451" SG_ 582 AvgEnergyConsmpTripB 0;
BA_ "GenSigTimeoutMsg_HU_B" SG_ 582 AvgEnergyConsmpTripB 0;
BA_ "GenSigTimeoutMsg_HU_A" SG_ 582 AvgEnergyConsmpTripB 0;
BA_ "GenSigSendType" SG_ 582 AvgEnergyConsmpTripB 7;
BA_ "GenSigCycleTimeActive" SG_ 582 AvgEnergyConsmpTripB 100;
BA_ "GenSigCycleTime" SG_ 582 AvgEnergyConsmpTripB 100;
BA_ "GenSigTimeoutMsg_HU_High_X445" SG_ 582 AvgEnergyConsmpTripB 0;
BA_ "GenSigTimeoutMsg_HU_Mid_X445" SG_ 582 AvgEnergyConsmpTripB 0;
BA_ "GenSigTimeoutTime_HU_High_X445" SG_ 582 AvgEnergyConsmpTripB 0;
BA_ "GenSigTimeoutTime_HU_Mid_X445" SG_ 582 AvgEnergyConsmpTripB 0;
BA_ "GenSigTimeoutTime_HU_Mid_X451" SG_ 582 AvgEnergyConsmpTripA 0;
BA_ "GenSigTimeoutTime_HU_High_X451" SG_ 582 AvgEnergyConsmpTripA 0;
BA_ "GenSigTimeoutTime_HU_B" SG_ 582 AvgEnergyConsmpTripA 0;
BA_ "GenSigTimeoutTime_HU_A" SG_ 582 AvgEnergyConsmpTripA 0;
BA_ "GenSigTimeoutMsg_HU_Mid_X451" SG_ 582 AvgEnergyConsmpTripA 0;
BA_ "GenSigTimeoutMsg_HU_High_X451" SG_ 582 AvgEnergyConsmpTripA 0;
BA_ "GenSigTimeoutMsg_HU_B" SG_ 582 AvgEnergyConsmpTripA 0;
BA_ "GenSigTimeoutMsg_HU_A" SG_ 582 AvgEnergyConsmpTripA 0;
BA_ "GenSigSendType" SG_ 582 AvgEnergyConsmpTripA 7;
BA_ "GenSigCycleTimeActive" SG_ 582 AvgEnergyConsmpTripA 100;
BA_ "GenSigCycleTime" SG_ 582 AvgEnergyConsmpTripA 100;
BA_ "GenSigTimeoutMsg_HU_High_X445" SG_ 582 AvgEnergyConsmpTripA 0;
BA_ "GenSigTimeoutMsg_HU_Mid_X445" SG_ 582 AvgEnergyConsmpTripA 0;
BA_ "GenSigTimeoutTime_HU_High_X445" SG_ 582 AvgEnergyConsmpTripA 0;
BA_ "GenSigTimeoutTime_HU_Mid_X445" SG_ 582 AvgEnergyConsmpTripA 0;
BA_ "GenSigTimeoutTime_HU_Mid_X451" SG_ 582 InstPwrConsumpStatus 0;
BA_ "GenSigTimeoutTime_HU_High_X451" SG_ 582 InstPwrConsumpStatus 0;
BA_ "GenSigTimeoutTime_HU_B" SG_ 582 InstPwrConsumpStatus 0;
BA_ "GenSigTimeoutTime_HU_A" SG_ 582 InstPwrConsumpStatus 0;
BA_ "GenSigTimeoutMsg_HU_Mid_X451" SG_ 582 InstPwrConsumpStatus 0;
BA_ "GenSigTimeoutMsg_HU_High_X451" SG_ 582 InstPwrConsumpStatus 0;
BA_ "GenSigTimeoutMsg_HU_B" SG_ 582 InstPwrConsumpStatus 0;
BA_ "GenSigTimeoutMsg_HU_A" SG_ 582 InstPwrConsumpStatus 0;
BA_ "GenSigSendType" SG_ 582 InstPwrConsumpStatus 7;
BA_ "GenSigCycleTimeActive" SG_ 582 InstPwrConsumpStatus 100;
BA_ "GenSigCycleTime" SG_ 582 InstPwrConsumpStatus 100;
BA_ "GenSigTimeoutMsg_HU_High_X445" SG_ 582 InstPwrConsumpStatus 0;
BA_ "GenSigTimeoutMsg_HU_Mid_X445" SG_ 582 InstPwrConsumpStatus 0;
BA_ "GenSigTimeoutTime_HU_High_X445" SG_ 582 InstPwrConsumpStatus 0;
BA_ "GenSigTimeoutTime_HU_Mid_X445" SG_ 582 InstPwrConsumpStatus 0;
BA_ "GenSigTimeoutTime_HU_Mid_X451" SG_ 582 InstPwrConsump 0;
BA_ "GenSigTimeoutTime_HU_High_X451" SG_ 582 InstPwrConsump 0;
BA_ "GenSigTimeoutTime_HU_B" SG_ 582 InstPwrConsump 0;
BA_ "GenSigTimeoutTime_HU_A" SG_ 582 InstPwrConsump 0;
BA_ "GenSigTimeoutMsg_HU_Mid_X451" SG_ 582 InstPwrConsump 0;
BA_ "GenSigTimeoutMsg_HU_High_X451" SG_ 582 InstPwrConsump 0;
BA_ "GenSigTimeoutMsg_HU_B" SG_ 582 InstPwrConsump 0;
BA_ "GenSigTimeoutMsg_HU_A" SG_ 582 InstPwrConsump 0;
BA_ "GenSigStartValue" SG_ 582 InstPwrConsump 100;
BA_ "GenSigSendType" SG_ 582 InstPwrConsump 7;
BA_ "GenSigCycleTimeActive" SG_ 582 InstPwrConsump 100;
BA_ "GenSigCycleTime" SG_ 582 InstPwrConsump 100;
BA_ "GenSigTimeoutMsg_HU_High_X445" SG_ 582 InstPwrConsump 0;
BA_ "GenSigTimeoutMsg_HU_Mid_X445" SG_ 582 InstPwrConsump 0;
BA_ "GenSigTimeoutTime_HU_High_X445" SG_ 582 InstPwrConsump 0;
BA_ "GenSigTimeoutTime_HU_Mid_X445" SG_ 582 InstPwrConsump 0;
BA_ "GenSigTimeoutTime_HU_Mid_X451" SG_ 1630 TPMS_DiagResponse_UUDT 0;
BA_ "GenSigTimeoutTime_HU_High_X451" SG_ 1630 TPMS_DiagResponse_UUDT 0;
BA_ "GenSigTimeoutTime_HU_B" SG_ 1630 TPMS_DiagResponse_UUDT 0;
BA_ "GenSigTimeoutTime_HU_A" SG_ 1630 TPMS_DiagResponse_UUDT 0;
BA_ "GenSigTimeoutMsg_HU_Mid_X451" SG_ 1630 TPMS_DiagResponse_UUDT 0;
BA_ "GenSigTimeoutMsg_HU_High_X451" SG_ 1630 TPMS_DiagResponse_UUDT 0;
BA_ "GenSigTimeoutMsg_HU_B" SG_ 1630 TPMS_DiagResponse_UUDT 0;
BA_ "GenSigTimeoutMsg_HU_A" SG_ 1630 TPMS_DiagResponse_UUDT 0;
BA_ "GenSigSendType" SG_ 1630 TPMS_DiagResponse_UUDT 1;
BA_ "GenSigTimeoutMsg_HU_High_X445" SG_ 1630 TPMS_DiagResponse_UUDT 0;
BA_ "GenSigTimeoutMsg_HU_Mid_X445" SG_ 1630 TPMS_DiagResponse_UUDT 0;
BA_ "GenSigTimeoutTime_HU_High_X445" SG_ 1630 TPMS_DiagResponse_UUDT 0;
BA_ "GenSigTimeoutTime_HU_Mid_X445" SG_ 1630 TPMS_DiagResponse_UUDT 0;
BA_ "GenSigTimeoutMsg_IVI" SG_ 1630 TPMS_DiagResponse_UUDT 0;
BA_ "GenSigTimeoutTime_IVI" SG_ 1630 TPMS_DiagResponse_UUDT 0;
BA_ "GenSigTimeoutTime_HU_Mid_X451" SG_ 1886 TPMS_DiagResponse_USDT 0;
BA_ "GenSigTimeoutTime_HU_High_X451" SG_ 1886 TPMS_DiagResponse_USDT 0;
BA_ "GenSigTimeoutTime_HU_B" SG_ 1886 TPMS_DiagResponse_USDT 0;
BA_ "GenSigTimeoutTime_HU_A" SG_ 1886 TPMS_DiagResponse_USDT 0;
BA_ "GenSigTimeoutMsg_HU_Mid_X451" SG_ 1886 TPMS_DiagResponse_USDT 0;
BA_ "GenSigTimeoutMsg_HU_High_X451" SG_ 1886 TPMS_DiagResponse_USDT 0;
BA_ "GenSigTimeoutMsg_HU_B" SG_ 1886 TPMS_DiagResponse_USDT 0;
BA_ "GenSigTimeoutMsg_HU_A" SG_ 1886 TPMS_DiagResponse_USDT 0;
BA_ "GenSigSendType" SG_ 1886 TPMS_DiagResponse_USDT 1;
BA_ "GenSigTimeoutMsg_HU_High_X445" SG_ 1886 TPMS_DiagResponse_USDT 0;
BA_ "GenSigTimeoutMsg_HU_Mid_X445" SG_ 1886 TPMS_DiagResponse_USDT 0;
BA_ "GenSigTimeoutTime_HU_High_X445" SG_ 1886 TPMS_DiagResponse_USDT 0;
BA_ "GenSigTimeoutTime_HU_Mid_X445" SG_ 1886 TPMS_DiagResponse_USDT 0;
BA_ "GenSigTimeoutMsg_IVI" SG_ 1886 TPMS_DiagResponse_USDT 0;
BA_ "GenSigTimeoutTime_IVI" SG_ 1886 TPMS_DiagResponse_USDT 0;
BA_ "GenSigTimeoutTime_HU_Mid_X451" SG_ 1878 TPMS_DiagRequest 0;
BA_ "GenSigTimeoutTime_HU_High_X451" SG_ 1878 TPMS_DiagRequest 0;
BA_ "GenSigTimeoutTime_HU_B" SG_ 1878 TPMS_DiagRequest 0;
BA_ "GenSigTimeoutTime_HU_A" SG_ 1878 TPMS_DiagRequest 0;
BA_ "GenSigTimeoutMsg_HU_Mid_X451" SG_ 1878 TPMS_DiagRequest 0;
BA_ "GenSigTimeoutMsg_HU_High_X451" SG_ 1878 TPMS_DiagRequest 0;
BA_ "GenSigTimeoutMsg_HU_B" SG_ 1878 TPMS_DiagRequest 0;
BA_ "GenSigTimeoutMsg_HU_A" SG_ 1878 TPMS_DiagRequest 0;
BA_ "GenSigSendType" SG_ 1878 TPMS_DiagRequest 1;
BA_ "GenSigTimeoutMsg_HU_High_X445" SG_ 1878 TPMS_DiagRequest 0;
BA_ "GenSigTimeoutMsg_HU_Mid_X445" SG_ 1878 TPMS_DiagRequest 0;
BA_ "GenSigTimeoutTime_HU_High_X445" SG_ 1878 TPMS_DiagRequest 0;
BA_ "GenSigTimeoutTime_HU_Mid_X445" SG_ 1878 TPMS_DiagRequest 0;
BA_ "GenSigTimeoutMsg_IVI" SG_ 1878 TPMS_DiagRequest 0;
BA_ "GenSigTimeoutTime_IVI" SG_ 1878 TPMS_DiagRequest 0;
BA_ "GenSigTimeoutTime_HU_Mid_X451" SG_ 1289 PreviousState_ESP 0;
BA_ "GenSigTimeoutTime_HU_High_X451" SG_ 1289 PreviousState_ESP 0;
BA_ "GenSigTimeoutTime_HU_B" SG_ 1289 PreviousState_ESP 0;
BA_ "GenSigTimeoutTime_HU_A" SG_ 1289 PreviousState_ESP 0;
BA_ "GenSigTimeoutMsg_HU_Mid_X451" SG_ 1289 PreviousState_ESP 0;
BA_ "GenSigTimeoutMsg_HU_High_X451" SG_ 1289 PreviousState_ESP 0;
BA_ "GenSigTimeoutMsg_HU_B" SG_ 1289 PreviousState_ESP 0;
BA_ "GenSigTimeoutMsg_HU_A" SG_ 1289 PreviousState_ESP 0;
BA_ "GenSigSendType" SG_ 1289 PreviousState_ESP 7;
BA_ "GenSigCycleTimeActive" SG_ 1289 PreviousState_ESP 200;
BA_ "GenSigCycleTime" SG_ 1289 PreviousState_ESP 200;
BA_ "GenSigTimeoutTime_HU_Mid_X451" SG_ 1289 Reserved63 0;
BA_ "GenSigTimeoutTime_HU_High_X451" SG_ 1289 Reserved63 0;
BA_ "GenSigTimeoutTime_HU_B" SG_ 1289 Reserved63 0;
BA_ "GenSigTimeoutTime_HU_A" SG_ 1289 Reserved63 0;
BA_ "GenSigTimeoutMsg_HU_Mid_X451" SG_ 1289 Reserved63 0;
BA_ "GenSigTimeoutMsg_HU_High_X451" SG_ 1289 Reserved63 0;
BA_ "GenSigTimeoutMsg_HU_B" SG_ 1289 Reserved63 0;
BA_ "GenSigTimeoutMsg_HU_A" SG_ 1289 Reserved63 0;
BA_ "GenSigSendType" SG_ 1289 Reserved63 7;
BA_ "GenSigCycleTimeActive" SG_ 1289 Reserved63 200;
BA_ "GenSigCycleTime" SG_ 1289 Reserved63 200;
BA_ "GenSigTimeoutTime_HU_Mid_X451" SG_ 1289 Reserved62 0;
BA_ "GenSigTimeoutTime_HU_High_X451" SG_ 1289 Reserved62 0;
BA_ "GenSigTimeoutTime_HU_B" SG_ 1289 Reserved62 0;
BA_ "GenSigTimeoutTime_HU_A" SG_ 1289 Reserved62 0;
BA_ "GenSigTimeoutMsg_HU_Mid_X451" SG_ 1289 Reserved62 0;
BA_ "GenSigTimeoutMsg_HU_High_X451" SG_ 1289 Reserved62 0;
BA_ "GenSigTimeoutMsg_HU_B" SG_ 1289 Reserved62 0;
BA_ "GenSigTimeoutMsg_HU_A" SG_ 1289 Reserved62 0;
BA_ "GenSigSendType" SG_ 1289 Reserved62 7;
BA_ "GenSigCycleTimeActive" SG_ 1289 Reserved62 200;
BA_ "GenSigCycleTime" SG_ 1289 Reserved62 200;
BA_ "GenSigTimeoutTime_HU_Mid_X451" SG_ 1289 Reserved61 0;
BA_ "GenSigTimeoutTime_HU_High_X451" SG_ 1289 Reserved61 0;
BA_ "GenSigTimeoutTime_HU_B" SG_ 1289 Reserved61 0;
BA_ "GenSigTimeoutTime_HU_A" SG_ 1289 Reserved61 0;
BA_ "GenSigTimeoutMsg_HU_Mid_X451" SG_ 1289 Reserved61 0;
BA_ "GenSigTimeoutMsg_HU_High_X451" SG_ 1289 Reserved61 0;
BA_ "GenSigTimeoutMsg_HU_B" SG_ 1289 Reserved61 0;
BA_ "GenSigTimeoutMsg_HU_A" SG_ 1289 Reserved61 0;
BA_ "GenSigSendType" SG_ 1289 Reserved61 7;
BA_ "GenSigCycleTimeActive" SG_ 1289 Reserved61 200;
BA_ "GenSigCycleTime" SG_ 1289 Reserved61 200;
BA_ "GenSigTimeoutTime_HU_Mid_X451" SG_ 1289 Reserved60 0;
BA_ "GenSigTimeoutTime_HU_High_X451" SG_ 1289 Reserved60 0;
BA_ "GenSigTimeoutTime_HU_B" SG_ 1289 Reserved60 0;
BA_ "GenSigTimeoutTime_HU_A" SG_ 1289 Reserved60 0;
BA_ "GenSigTimeoutMsg_HU_Mid_X451" SG_ 1289 Reserved60 0;
BA_ "GenSigTimeoutMsg_HU_High_X451" SG_ 1289 Reserved60 0;
BA_ "GenSigTimeoutMsg_HU_B" SG_ 1289 Reserved60 0;
BA_ "GenSigTimeoutMsg_HU_A" SG_ 1289 Reserved60 0;
BA_ "GenSigSendType" SG_ 1289 Reserved60 7;
BA_ "GenSigCycleTimeActive" SG_ 1289 Reserved60 200;
BA_ "GenSigCycleTime" SG_ 1289 Reserved60 200;
BA_ "GenSigTimeoutTime_HU_Mid_X451" SG_ 1289 Reserved59 0;
BA_ "GenSigTimeoutTime_HU_High_X451" SG_ 1289 Reserved59 0;
BA_ "GenSigTimeoutTime_HU_B" SG_ 1289 Reserved59 0;
BA_ "GenSigTimeoutTime_HU_A" SG_ 1289 Reserved59 0;
BA_ "GenSigTimeoutMsg_HU_Mid_X451" SG_ 1289 Reserved59 0;
BA_ "GenSigTimeoutMsg_HU_High_X451" SG_ 1289 Reserved59 0;
BA_ "GenSigTimeoutMsg_HU_B" SG_ 1289 Reserved59 0;
BA_ "GenSigTimeoutMsg_HU_A" SG_ 1289 Reserved59 0;
BA_ "GenSigSendType" SG_ 1289 Reserved59 7;
BA_ "GenSigCycleTimeActive" SG_ 1289 Reserved59 200;
BA_ "GenSigCycleTime" SG_ 1289 Reserved59 200;
BA_ "GenSigTimeoutTime_HU_Mid_X451" SG_ 1289 Reserved58 0;
BA_ "GenSigTimeoutTime_HU_High_X451" SG_ 1289 Reserved58 0;
BA_ "GenSigTimeoutTime_HU_B" SG_ 1289 Reserved58 0;
BA_ "GenSigTimeoutTime_HU_A" SG_ 1289 Reserved58 0;
BA_ "GenSigTimeoutMsg_HU_Mid_X451" SG_ 1289 Reserved58 0;
BA_ "GenSigTimeoutMsg_HU_High_X451" SG_ 1289 Reserved58 0;
BA_ "GenSigTimeoutMsg_HU_B" SG_ 1289 Reserved58 0;
BA_ "GenSigTimeoutMsg_HU_A" SG_ 1289 Reserved58 0;
BA_ "GenSigSendType" SG_ 1289 Reserved58 7;
BA_ "GenSigCycleTimeActive" SG_ 1289 Reserved58 200;
BA_ "GenSigCycleTime" SG_ 1289 Reserved58 200;
BA_ "GenSigTimeoutTime_HU_Mid_X451" SG_ 1289 Reserved57 0;
BA_ "GenSigTimeoutTime_HU_High_X451" SG_ 1289 Reserved57 0;
BA_ "GenSigTimeoutTime_HU_B" SG_ 1289 Reserved57 0;
BA_ "GenSigTimeoutTime_HU_A" SG_ 1289 Reserved57 0;
BA_ "GenSigTimeoutMsg_HU_Mid_X451" SG_ 1289 Reserved57 0;
BA_ "GenSigTimeoutMsg_HU_High_X451" SG_ 1289 Reserved57 0;
BA_ "GenSigTimeoutMsg_HU_B" SG_ 1289 Reserved57 0;
BA_ "GenSigTimeoutMsg_HU_A" SG_ 1289 Reserved57 0;
BA_ "GenSigSendType" SG_ 1289 Reserved57 7;
BA_ "GenSigCycleTimeActive" SG_ 1289 Reserved57 200;
BA_ "GenSigCycleTime" SG_ 1289 Reserved57 200;
BA_ "GenSigTimeoutTime_HU_Mid_X451" SG_ 1289 Reserved56 0;
BA_ "GenSigTimeoutTime_HU_High_X451" SG_ 1289 Reserved56 0;
BA_ "GenSigTimeoutTime_HU_B" SG_ 1289 Reserved56 0;
BA_ "GenSigTimeoutTime_HU_A" SG_ 1289 Reserved56 0;
BA_ "GenSigTimeoutMsg_HU_Mid_X451" SG_ 1289 Reserved56 0;
BA_ "GenSigTimeoutMsg_HU_High_X451" SG_ 1289 Reserved56 0;
BA_ "GenSigTimeoutMsg_HU_B" SG_ 1289 Reserved56 0;
BA_ "GenSigTimeoutMsg_HU_A" SG_ 1289 Reserved56 0;
BA_ "GenSigSendType" SG_ 1289 Reserved56 7;
BA_ "GenSigCycleTimeActive" SG_ 1289 Reserved56 200;
BA_ "GenSigCycleTime" SG_ 1289 Reserved56 200;
BA_ "GenSigTimeoutTime_HU_Mid_X451" SG_ 1289 RepeatMessageReq_ESP 0;
BA_ "GenSigTimeoutTime_HU_High_X451" SG_ 1289 RepeatMessageReq_ESP 0;
BA_ "GenSigTimeoutTime_HU_B" SG_ 1289 RepeatMessageReq_ESP 0;
BA_ "GenSigTimeoutTime_HU_A" SG_ 1289 RepeatMessageReq_ESP 0;
BA_ "GenSigTimeoutMsg_HU_Mid_X451" SG_ 1289 RepeatMessageReq_ESP 0;
BA_ "GenSigTimeoutMsg_HU_High_X451" SG_ 1289 RepeatMessageReq_ESP 0;
BA_ "GenSigTimeoutMsg_HU_B" SG_ 1289 RepeatMessageReq_ESP 0;
BA_ "GenSigTimeoutMsg_HU_A" SG_ 1289 RepeatMessageReq_ESP 0;
BA_ "GenSigSendType" SG_ 1289 RepeatMessageReq_ESP 7;
BA_ "GenSigCycleTimeActive" SG_ 1289 RepeatMessageReq_ESP 200;
BA_ "GenSigCycleTime" SG_ 1289 RepeatMessageReq_ESP 200;
BA_ "GenSigTimeoutTime_HU_Mid_X451" SG_ 1289 PartialNetworkInformation_ESP 0;
BA_ "GenSigTimeoutTime_HU_High_X451" SG_ 1289 PartialNetworkInformation_ESP 0;
BA_ "GenSigTimeoutTime_HU_B" SG_ 1289 PartialNetworkInformation_ESP 0;
BA_ "GenSigTimeoutTime_HU_A" SG_ 1289 PartialNetworkInformation_ESP 0;
BA_ "GenSigTimeoutMsg_HU_Mid_X451" SG_ 1289 PartialNetworkInformation_ESP 0;
BA_ "GenSigTimeoutMsg_HU_High_X451" SG_ 1289 PartialNetworkInformation_ESP 0;
BA_ "GenSigTimeoutMsg_HU_B" SG_ 1289 PartialNetworkInformation_ESP 0;
BA_ "GenSigTimeoutMsg_HU_A" SG_ 1289 PartialNetworkInformation_ESP 0;
BA_ "GenSigSendType" SG_ 1289 PartialNetworkInformation_ESP 7;
BA_ "GenSigCycleTimeActive" SG_ 1289 PartialNetworkInformation_ESP 200;
BA_ "GenSigCycleTime" SG_ 1289 PartialNetworkInformation_ESP 200;
BA_ "GenSigTimeoutTime_HU_Mid_X451" SG_ 1289 NMCoOrdSlpReady_ESP 0;
BA_ "GenSigTimeoutTime_HU_High_X451" SG_ 1289 NMCoOrdSlpReady_ESP 0;
BA_ "GenSigTimeoutTime_HU_B" SG_ 1289 NMCoOrdSlpReady_ESP 0;
BA_ "GenSigTimeoutTime_HU_A" SG_ 1289 NMCoOrdSlpReady_ESP 0;
BA_ "GenSigTimeoutMsg_HU_Mid_X451" SG_ 1289 NMCoOrdSlpReady_ESP 0;
BA_ "GenSigTimeoutMsg_HU_High_X451" SG_ 1289 NMCoOrdSlpReady_ESP 0;
BA_ "GenSigTimeoutMsg_HU_B" SG_ 1289 NMCoOrdSlpReady_ESP 0;
BA_ "GenSigTimeoutMsg_HU_A" SG_ 1289 NMCoOrdSlpReady_ESP 0;
BA_ "GenSigSendType" SG_ 1289 NMCoOrdSlpReady_ESP 7;
BA_ "GenSigCycleTimeActive" SG_ 1289 NMCoOrdSlpReady_ESP 200;
BA_ "GenSigCycleTime" SG_ 1289 NMCoOrdSlpReady_ESP 200;
BA_ "GenSigTimeoutTime_HU_Mid_X451" SG_ 1289 ESP_NMPDU_USER_DATA_D5 0;
BA_ "GenSigTimeoutTime_HU_High_X451" SG_ 1289 ESP_NMPDU_USER_DATA_D5 0;
BA_ "GenSigTimeoutTime_HU_B" SG_ 1289 ESP_NMPDU_USER_DATA_D5 0;
BA_ "GenSigTimeoutTime_HU_A" SG_ 1289 ESP_NMPDU_USER_DATA_D5 0;
BA_ "GenSigTimeoutMsg_HU_Mid_X451" SG_ 1289 ESP_NMPDU_USER_DATA_D5 0;
BA_ "GenSigTimeoutMsg_HU_High_X451" SG_ 1289 ESP_NMPDU_USER_DATA_D5 0;
BA_ "GenSigTimeoutMsg_HU_B" SG_ 1289 ESP_NMPDU_USER_DATA_D5 0;
BA_ "GenSigTimeoutMsg_HU_A" SG_ 1289 ESP_NMPDU_USER_DATA_D5 0;
BA_ "GenSigSendType" SG_ 1289 ESP_NMPDU_USER_DATA_D5 7;
BA_ "GenSigCycleTimeActive" SG_ 1289 ESP_NMPDU_USER_DATA_D5 200;
BA_ "GenSigCycleTime" SG_ 1289 ESP_NMPDU_USER_DATA_D5 200;
BA_ "GenSigTimeoutTime_HU_Mid_X451" SG_ 1289 ESP_NMPDU_USER_DATA_D4 0;
BA_ "GenSigTimeoutTime_HU_High_X451" SG_ 1289 ESP_NMPDU_USER_DATA_D4 0;
BA_ "GenSigTimeoutTime_HU_B" SG_ 1289 ESP_NMPDU_USER_DATA_D4 0;
BA_ "GenSigTimeoutTime_HU_A" SG_ 1289 ESP_NMPDU_USER_DATA_D4 0;
BA_ "GenSigTimeoutMsg_HU_Mid_X451" SG_ 1289 ESP_NMPDU_USER_DATA_D4 0;
BA_ "GenSigTimeoutMsg_HU_High_X451" SG_ 1289 ESP_NMPDU_USER_DATA_D4 0;
BA_ "GenSigTimeoutMsg_HU_B" SG_ 1289 ESP_NMPDU_USER_DATA_D4 0;
BA_ "GenSigTimeoutMsg_HU_A" SG_ 1289 ESP_NMPDU_USER_DATA_D4 0;
BA_ "GenSigSendType" SG_ 1289 ESP_NMPDU_USER_DATA_D4 7;
BA_ "GenSigCycleTimeActive" SG_ 1289 ESP_NMPDU_USER_DATA_D4 200;
BA_ "GenSigCycleTime" SG_ 1289 ESP_NMPDU_USER_DATA_D4 200;
BA_ "GenSigTimeoutTime_HU_Mid_X451" SG_ 1289 ESP_NMPDU_USER_DATA_D3 0;
BA_ "GenSigTimeoutTime_HU_High_X451" SG_ 1289 ESP_NMPDU_USER_DATA_D3 0;
BA_ "GenSigTimeoutTime_HU_B" SG_ 1289 ESP_NMPDU_USER_DATA_D3 0;
BA_ "GenSigTimeoutTime_HU_A" SG_ 1289 ESP_NMPDU_USER_DATA_D3 0;
BA_ "GenSigTimeoutMsg_HU_Mid_X451" SG_ 1289 ESP_NMPDU_USER_DATA_D3 0;
BA_ "GenSigTimeoutMsg_HU_High_X451" SG_ 1289 ESP_NMPDU_USER_DATA_D3 0;
BA_ "GenSigTimeoutMsg_HU_B" SG_ 1289 ESP_NMPDU_USER_DATA_D3 0;
BA_ "GenSigTimeoutMsg_HU_A" SG_ 1289 ESP_NMPDU_USER_DATA_D3 0;
BA_ "GenSigSendType" SG_ 1289 ESP_NMPDU_USER_DATA_D3 7;
BA_ "GenSigCycleTimeActive" SG_ 1289 ESP_NMPDU_USER_DATA_D3 200;
BA_ "GenSigCycleTime" SG_ 1289 ESP_NMPDU_USER_DATA_D3 200;
BA_ "GenSigTimeoutTime_HU_Mid_X451" SG_ 1289 ESP_NMPDU_USER_DATA_D2 0;
BA_ "GenSigTimeoutTime_HU_High_X451" SG_ 1289 ESP_NMPDU_USER_DATA_D2 0;
BA_ "GenSigTimeoutTime_HU_B" SG_ 1289 ESP_NMPDU_USER_DATA_D2 0;
BA_ "GenSigTimeoutTime_HU_A" SG_ 1289 ESP_NMPDU_USER_DATA_D2 0;
BA_ "GenSigTimeoutMsg_HU_Mid_X451" SG_ 1289 ESP_NMPDU_USER_DATA_D2 0;
BA_ "GenSigTimeoutMsg_HU_High_X451" SG_ 1289 ESP_NMPDU_USER_DATA_D2 0;
BA_ "GenSigTimeoutMsg_HU_B" SG_ 1289 ESP_NMPDU_USER_DATA_D2 0;
BA_ "GenSigTimeoutMsg_HU_A" SG_ 1289 ESP_NMPDU_USER_DATA_D2 0;
BA_ "GenSigSendType" SG_ 1289 ESP_NMPDU_USER_DATA_D2 7;
BA_ "GenSigCycleTimeActive" SG_ 1289 ESP_NMPDU_USER_DATA_D2 200;
BA_ "GenSigCycleTime" SG_ 1289 ESP_NMPDU_USER_DATA_D2 200;
BA_ "GenSigTimeoutTime_HU_Mid_X451" SG_ 1289 ESP_NMPDU_USER_DATA_D1 0;
BA_ "GenSigTimeoutTime_HU_High_X451" SG_ 1289 ESP_NMPDU_USER_DATA_D1 0;
BA_ "GenSigTimeoutTime_HU_B" SG_ 1289 ESP_NMPDU_USER_DATA_D1 0;
BA_ "GenSigTimeoutTime_HU_A" SG_ 1289 ESP_NMPDU_USER_DATA_D1 0;
BA_ "GenSigTimeoutMsg_HU_Mid_X451" SG_ 1289 ESP_NMPDU_USER_DATA_D1 0;
BA_ "GenSigTimeoutMsg_HU_High_X451" SG_ 1289 ESP_NMPDU_USER_DATA_D1 0;
BA_ "GenSigTimeoutMsg_HU_B" SG_ 1289 ESP_NMPDU_USER_DATA_D1 0;
BA_ "GenSigTimeoutMsg_HU_A" SG_ 1289 ESP_NMPDU_USER_DATA_D1 0;
BA_ "GenSigSendType" SG_ 1289 ESP_NMPDU_USER_DATA_D1 7;
BA_ "GenSigCycleTimeActive" SG_ 1289 ESP_NMPDU_USER_DATA_D1 200;
BA_ "GenSigCycleTime" SG_ 1289 ESP_NMPDU_USER_DATA_D1 200;
BA_ "GenSigTimeoutTime_HU_Mid_X451" SG_ 1289 ESP_NMPDU_SRC_ECU_ID 0;
BA_ "GenSigTimeoutTime_HU_High_X451" SG_ 1289 ESP_NMPDU_SRC_ECU_ID 0;
BA_ "GenSigTimeoutTime_HU_B" SG_ 1289 ESP_NMPDU_SRC_ECU_ID 0;
BA_ "GenSigTimeoutTime_HU_A" SG_ 1289 ESP_NMPDU_SRC_ECU_ID 0;
BA_ "GenSigTimeoutMsg_HU_Mid_X451" SG_ 1289 ESP_NMPDU_SRC_ECU_ID 0;
BA_ "GenSigTimeoutMsg_HU_High_X451" SG_ 1289 ESP_NMPDU_SRC_ECU_ID 0;
BA_ "GenSigTimeoutMsg_HU_B" SG_ 1289 ESP_NMPDU_SRC_ECU_ID 0;
BA_ "GenSigTimeoutMsg_HU_A" SG_ 1289 ESP_NMPDU_SRC_ECU_ID 0;
BA_ "GenSigSendType" SG_ 1289 ESP_NMPDU_SRC_ECU_ID 7;
BA_ "GenSigCycleTimeActive" SG_ 1289 ESP_NMPDU_SRC_ECU_ID 200;
BA_ "GenSigCycleTime" SG_ 1289 ESP_NMPDU_SRC_ECU_ID 200;
BA_ "GenSigTimeoutTime_HU_Mid_X451" SG_ 1289 CurrentState_ESP 0;
BA_ "GenSigTimeoutTime_HU_High_X451" SG_ 1289 CurrentState_ESP 0;
BA_ "GenSigTimeoutTime_HU_B" SG_ 1289 CurrentState_ESP 0;
BA_ "GenSigTimeoutTime_HU_A" SG_ 1289 CurrentState_ESP 0;
BA_ "GenSigTimeoutMsg_HU_Mid_X451" SG_ 1289 CurrentState_ESP 0;
BA_ "GenSigTimeoutMsg_HU_High_X451" SG_ 1289 CurrentState_ESP 0;
BA_ "GenSigTimeoutMsg_HU_B" SG_ 1289 CurrentState_ESP 0;
BA_ "GenSigTimeoutMsg_HU_A" SG_ 1289 CurrentState_ESP 0;
BA_ "GenSigSendType" SG_ 1289 CurrentState_ESP 7;
BA_ "GenSigCycleTimeActive" SG_ 1289 CurrentState_ESP 200;
BA_ "GenSigCycleTime" SG_ 1289 CurrentState_ESP 200;
BA_ "GenSigTimeoutTime_HU_Mid_X451" SG_ 1289 ActiveWakeUp_ESP 0;
BA_ "GenSigTimeoutTime_HU_High_X451" SG_ 1289 ActiveWakeUp_ESP 0;
BA_ "GenSigTimeoutTime_HU_B" SG_ 1289 ActiveWakeUp_ESP 0;
BA_ "GenSigTimeoutTime_HU_A" SG_ 1289 ActiveWakeUp_ESP 0;
BA_ "GenSigTimeoutMsg_HU_Mid_X451" SG_ 1289 ActiveWakeUp_ESP 0;
BA_ "GenSigTimeoutMsg_HU_High_X451" SG_ 1289 ActiveWakeUp_ESP 0;
BA_ "GenSigTimeoutMsg_HU_B" SG_ 1289 ActiveWakeUp_ESP 0;
BA_ "GenSigTimeoutMsg_HU_A" SG_ 1289 ActiveWakeUp_ESP 0;
BA_ "GenSigSendType" SG_ 1289 ActiveWakeUp_ESP 7;
BA_ "GenSigCycleTimeActive" SG_ 1289 ActiveWakeUp_ESP 200;
BA_ "GenSigCycleTime" SG_ 1289 ActiveWakeUp_ESP 200;
BA_ "GenSigTimeoutTime_HU_Mid_X451" SG_ 1772 SCU_DiagResponse_UUDT 0;
BA_ "GenSigTimeoutTime_HU_High_X451" SG_ 1772 SCU_DiagResponse_UUDT 0;
BA_ "GenSigTimeoutTime_HU_B" SG_ 1772 SCU_DiagResponse_UUDT 0;
BA_ "GenSigTimeoutTime_HU_A" SG_ 1772 SCU_DiagResponse_UUDT 0;
BA_ "GenSigTimeoutMsg_HU_Mid_X451" SG_ 1772 SCU_DiagResponse_UUDT 0;
BA_ "GenSigTimeoutMsg_HU_High_X451" SG_ 1772 SCU_DiagResponse_UUDT 0;
BA_ "GenSigTimeoutMsg_HU_B" SG_ 1772 SCU_DiagResponse_UUDT 0;
BA_ "GenSigTimeoutMsg_HU_A" SG_ 1772 SCU_DiagResponse_UUDT 0;
BA_ "GenSigSendType" SG_ 1772 SCU_DiagResponse_UUDT 1;
BA_ "GenSigTimeoutMsg_HU_High_X445" SG_ 1772 SCU_DiagResponse_UUDT 0;
BA_ "GenSigTimeoutMsg_HU_Mid_X445" SG_ 1772 SCU_DiagResponse_UUDT 0;
BA_ "GenSigTimeoutTime_HU_High_X445" SG_ 1772 SCU_DiagResponse_UUDT 0;
BA_ "GenSigTimeoutTime_HU_Mid_X445" SG_ 1772 SCU_DiagResponse_UUDT 0;
BA_ "GenSigTimeoutMsg_IVI" SG_ 1772 SCU_DiagResponse_UUDT 0;
BA_ "GenSigTimeoutTime_IVI" SG_ 1772 SCU_DiagResponse_UUDT 0;
BA_ "GenSigTimeoutTime_HU_Mid_X451" SG_ 2028 SCU_DiagResponse_USDT 0;
BA_ "GenSigTimeoutTime_HU_High_X451" SG_ 2028 SCU_DiagResponse_USDT 0;
BA_ "GenSigTimeoutTime_HU_B" SG_ 2028 SCU_DiagResponse_USDT 0;
BA_ "GenSigTimeoutTime_HU_A" SG_ 2028 SCU_DiagResponse_USDT 0;
BA_ "GenSigTimeoutMsg_HU_Mid_X451" SG_ 2028 SCU_DiagResponse_USDT 0;
BA_ "GenSigTimeoutMsg_HU_High_X451" SG_ 2028 SCU_DiagResponse_USDT 0;
BA_ "GenSigTimeoutMsg_HU_B" SG_ 2028 SCU_DiagResponse_USDT 0;
BA_ "GenSigTimeoutMsg_HU_A" SG_ 2028 SCU_DiagResponse_USDT 0;
BA_ "GenSigSendType" SG_ 2028 SCU_DiagResponse_USDT 1;
BA_ "GenSigTimeoutMsg_HU_High_X445" SG_ 2028 SCU_DiagResponse_USDT 0;
BA_ "GenSigTimeoutMsg_HU_Mid_X445" SG_ 2028 SCU_DiagResponse_USDT 0;
BA_ "GenSigTimeoutTime_HU_High_X445" SG_ 2028 SCU_DiagResponse_USDT 0;
BA_ "GenSigTimeoutTime_HU_Mid_X445" SG_ 2028 SCU_DiagResponse_USDT 0;
BA_ "GenSigTimeoutMsg_IVI" SG_ 2028 SCU_DiagResponse_USDT 0;
BA_ "GenSigTimeoutTime_IVI" SG_ 2028 SCU_DiagResponse_USDT 0;
BA_ "GenSigTimeoutTime_HU_Mid_X451" SG_ 2020 SCU_DiagRequest 0;
BA_ "GenSigTimeoutTime_HU_High_X451" SG_ 2020 SCU_DiagRequest 0;
BA_ "GenSigTimeoutTime_HU_B" SG_ 2020 SCU_DiagRequest 0;
BA_ "GenSigTimeoutTime_HU_A" SG_ 2020 SCU_DiagRequest 0;
BA_ "GenSigTimeoutMsg_HU_Mid_X451" SG_ 2020 SCU_DiagRequest 0;
BA_ "GenSigTimeoutMsg_HU_High_X451" SG_ 2020 SCU_DiagRequest 0;
BA_ "GenSigTimeoutMsg_HU_B" SG_ 2020 SCU_DiagRequest 0;
BA_ "GenSigTimeoutMsg_HU_A" SG_ 2020 SCU_DiagRequest 0;
BA_ "GenSigSendType" SG_ 2020 SCU_DiagRequest 1;
BA_ "GenSigTimeoutMsg_HU_High_X445" SG_ 2020 SCU_DiagRequest 0;
BA_ "GenSigTimeoutMsg_HU_Mid_X445" SG_ 2020 SCU_DiagRequest 0;
BA_ "GenSigTimeoutTime_HU_High_X445" SG_ 2020 SCU_DiagRequest 0;
BA_ "GenSigTimeoutTime_HU_Mid_X445" SG_ 2020 SCU_DiagRequest 0;
BA_ "GenSigTimeoutMsg_IVI" SG_ 2020 SCU_DiagRequest 0;
BA_ "GenSigTimeoutTime_IVI" SG_ 2020 SCU_DiagRequest 0;
BA_ "GenSigTimeoutTime_HU_Mid_X451" SG_ 719 ComfortState 0;
BA_ "GenSigTimeoutTime_HU_High_X451" SG_ 719 ComfortState 0;
BA_ "GenSigTimeoutTime_HU_B" SG_ 719 ComfortState 0;
BA_ "GenSigTimeoutTime_HU_A" SG_ 719 ComfortState 0;
BA_ "GenSigTimeoutMsg_HU_Mid_X451" SG_ 719 ComfortState 0;
BA_ "GenSigTimeoutMsg_HU_High_X451" SG_ 719 ComfortState 0;
BA_ "GenSigTimeoutMsg_HU_B" SG_ 719 ComfortState 0;
BA_ "GenSigTimeoutMsg_HU_A" SG_ 719 ComfortState 0;
BA_ "GenSigSendType" SG_ 719 ComfortState 7;
BA_ "GenSigCycleTimeActive" SG_ 719 ComfortState 100;
BA_ "GenSigCycleTime" SG_ 719 ComfortState 100;
BA_ "GenSigTimeoutTime_HU_Mid_X451" SG_ 719 PtcHtrCoilCntrlStatus 0;
BA_ "GenSigTimeoutTime_HU_High_X451" SG_ 719 PtcHtrCoilCntrlStatus 0;
BA_ "GenSigTimeoutTime_HU_B" SG_ 719 PtcHtrCoilCntrlStatus 0;
BA_ "GenSigTimeoutTime_HU_A" SG_ 719 PtcHtrCoilCntrlStatus 0;
BA_ "GenSigTimeoutMsg_HU_Mid_X451" SG_ 719 PtcHtrCoilCntrlStatus 0;
BA_ "GenSigTimeoutMsg_HU_High_X451" SG_ 719 PtcHtrCoilCntrlStatus 0;
BA_ "GenSigTimeoutMsg_HU_B" SG_ 719 PtcHtrCoilCntrlStatus 0;
BA_ "GenSigTimeoutMsg_HU_A" SG_ 719 PtcHtrCoilCntrlStatus 0;
BA_ "GenSigSendType" SG_ 719 PtcHtrCoilCntrlStatus 7;
BA_ "GenSigCycleTimeActive" SG_ 719 PtcHtrCoilCntrlStatus 100;
BA_ "GenSigCycleTime" SG_ 719 PtcHtrCoilCntrlStatus 100;
BA_ "GenSigTimeoutTime_HU_Mid_X451" SG_ 719 PtcHtrCoilCntrl 0;
BA_ "GenSigTimeoutTime_HU_High_X451" SG_ 719 PtcHtrCoilCntrl 0;
BA_ "GenSigTimeoutTime_HU_B" SG_ 719 PtcHtrCoilCntrl 0;
BA_ "GenSigTimeoutTime_HU_A" SG_ 719 PtcHtrCoilCntrl 0;
BA_ "GenSigTimeoutMsg_HU_Mid_X451" SG_ 719 PtcHtrCoilCntrl 0;
BA_ "GenSigTimeoutMsg_HU_High_X451" SG_ 719 PtcHtrCoilCntrl 0;
BA_ "GenSigTimeoutMsg_HU_B" SG_ 719 PtcHtrCoilCntrl 0;
BA_ "GenSigTimeoutMsg_HU_A" SG_ 719 PtcHtrCoilCntrl 0;
BA_ "GenSigSendType" SG_ 719 PtcHtrCoilCntrl 7;
BA_ "GenSigCycleTimeActive" SG_ 719 PtcHtrCoilCntrl 100;
BA_ "GenSigCycleTime" SG_ 719 PtcHtrCoilCntrl 100;
BA_ "GenSigTimeoutTime_HU_Mid_X451" SG_ 719 PtcHtrForcedCutoff 0;
BA_ "GenSigTimeoutTime_HU_High_X451" SG_ 719 PtcHtrForcedCutoff 0;
BA_ "GenSigTimeoutTime_HU_B" SG_ 719 PtcHtrForcedCutoff 0;
BA_ "GenSigTimeoutTime_HU_A" SG_ 719 PtcHtrForcedCutoff 0;
BA_ "GenSigTimeoutMsg_HU_Mid_X451" SG_ 719 PtcHtrForcedCutoff 0;
BA_ "GenSigTimeoutMsg_HU_High_X451" SG_ 719 PtcHtrForcedCutoff 0;
BA_ "GenSigTimeoutMsg_HU_B" SG_ 719 PtcHtrForcedCutoff 0;
BA_ "GenSigTimeoutMsg_HU_A" SG_ 719 PtcHtrForcedCutoff 0;
BA_ "GenSigSendType" SG_ 719 PtcHtrForcedCutoff 7;
BA_ "GenSigCycleTimeActive" SG_ 719 PtcHtrForcedCutoff 100;
BA_ "GenSigCycleTime" SG_ 719 PtcHtrForcedCutoff 100;
BA_ "GenSigTimeoutMsg_HU_High_X445" SG_ 719 PtcHtrForcedCutoff 0;
BA_ "GenSigTimeoutMsg_HU_Mid_X445" SG_ 719 PtcHtrForcedCutoff 0;
BA_ "GenSigTimeoutTime_HU_High_X445" SG_ 719 PtcHtrForcedCutoff 0;
BA_ "GenSigTimeoutTime_HU_Mid_X445" SG_ 719 PtcHtrForcedCutoff 0;
BA_ "GenSigTimeoutTime_HU_Mid_X451" SG_ 719 ComfortStateStatus 0;
BA_ "GenSigTimeoutTime_HU_High_X451" SG_ 719 ComfortStateStatus 0;
BA_ "GenSigTimeoutTime_HU_B" SG_ 719 ComfortStateStatus 0;
BA_ "GenSigTimeoutTime_HU_A" SG_ 719 ComfortStateStatus 0;
BA_ "GenSigTimeoutMsg_HU_Mid_X451" SG_ 719 ComfortStateStatus 0;
BA_ "GenSigTimeoutMsg_HU_High_X451" SG_ 719 ComfortStateStatus 0;
BA_ "GenSigTimeoutMsg_HU_B" SG_ 719 ComfortStateStatus 0;
BA_ "GenSigTimeoutMsg_HU_A" SG_ 719 ComfortStateStatus 0;
BA_ "GenSigSendType" SG_ 719 ComfortStateStatus 7;
BA_ "GenSigCycleTimeActive" SG_ 719 ComfortStateStatus 100;
BA_ "GenSigCycleTime" SG_ 719 ComfortStateStatus 100;
BA_ "GenSigTimeoutTime_HU_Mid_X451" SG_ 719 ValetStateStatus 0;
BA_ "GenSigTimeoutTime_HU_High_X451" SG_ 719 ValetStateStatus 0;
BA_ "GenSigTimeoutTime_HU_B" SG_ 719 ValetStateStatus 0;
BA_ "GenSigTimeoutTime_HU_A" SG_ 719 ValetStateStatus 0;
BA_ "GenSigTimeoutMsg_HU_Mid_X451" SG_ 719 ValetStateStatus 0;
BA_ "GenSigTimeoutMsg_HU_High_X451" SG_ 719 ValetStateStatus 0;
BA_ "GenSigTimeoutMsg_HU_B" SG_ 719 ValetStateStatus 0;
BA_ "GenSigTimeoutMsg_HU_A" SG_ 719 ValetStateStatus 0;
BA_ "GenSigSendType" SG_ 719 ValetStateStatus 7;
BA_ "GenSigCycleTimeActive" SG_ 719 ValetStateStatus 100;
BA_ "GenSigCycleTime" SG_ 719 ValetStateStatus 100;
BA_ "GenSigTimeoutTime_HU_Mid_X451" SG_ 719 ValetState 0;
BA_ "GenSigTimeoutTime_HU_High_X451" SG_ 719 ValetState 0;
BA_ "GenSigTimeoutTime_HU_B" SG_ 719 ValetState 0;
BA_ "GenSigTimeoutTime_HU_A" SG_ 719 ValetState 0;
BA_ "GenSigTimeoutMsg_HU_Mid_X451" SG_ 719 ValetState 0;
BA_ "GenSigTimeoutMsg_HU_High_X451" SG_ 719 ValetState 0;
BA_ "GenSigTimeoutMsg_HU_B" SG_ 719 ValetState 0;
BA_ "GenSigTimeoutMsg_HU_A" SG_ 719 ValetState 0;
BA_ "GenSigSendType" SG_ 719 ValetState 7;
BA_ "GenSigCycleTimeActive" SG_ 719 ValetState 100;
BA_ "GenSigCycleTime" SG_ 719 ValetState 100;
BA_ "GenSigTimeoutTime_HU_B" SG_ 1163 SRS_CRC_Failure_Status 0;
BA_ "GenSigTimeoutTime_HU_A" SG_ 1163 SRS_CRC_Failure_Status 0;
BA_ "GenSigTimeoutMsg_HU_B" SG_ 1163 SRS_CRC_Failure_Status 0;
BA_ "GenSigTimeoutMsg_HU_A" SG_ 1163 SRS_CRC_Failure_Status 0;
BA_ "GenSigSendType" SG_ 1163 SRS_CRC_Failure_Status 7;
BA_ "GenSigCycleTimeActive" SG_ 1163 SRS_CRC_Failure_Status 100;
BA_ "GenSigCycleTime" SG_ 1163 SRS_CRC_Failure_Status 100;
BA_ "GenSigTimeoutTime_HU_B" SG_ 1163 SRS_MRC_Failure_Status 0;
BA_ "GenSigTimeoutTime_HU_A" SG_ 1163 SRS_MRC_Failure_Status 0;
BA_ "GenSigTimeoutMsg_HU_B" SG_ 1163 SRS_MRC_Failure_Status 0;
BA_ "GenSigTimeoutMsg_HU_A" SG_ 1163 SRS_MRC_Failure_Status 0;
BA_ "GenSigSendType" SG_ 1163 SRS_MRC_Failure_Status 7;
BA_ "GenSigCycleTimeActive" SG_ 1163 SRS_MRC_Failure_Status 100;
BA_ "GenSigCycleTime" SG_ 1163 SRS_MRC_Failure_Status 100;
BA_ "GenSigSendType" SG_ 1163 SRS_Invalid_Failure_Status 7;
BA_ "GenSigCycleTimeActive" SG_ 1163 SRS_Invalid_Failure_Status 100;
BA_ "GenSigCycleTime" SG_ 1163 SRS_Invalid_Failure_Status 100;
BA_ "GenSigSendType" SG_ 1163 Telematics_Invalid_Failure_Statu 7;
BA_ "GenSigCycleTimeActive" SG_ 1163 Telematics_Invalid_Failure_Statu 100;
BA_ "GenSigCycleTime" SG_ 1163 Telematics_Invalid_Failure_Statu 100;
BA_ "SystemSignalLongSymbol" SG_ 1163 Telematics_Invalid_Failure_Statu "Telematics_Invalid_Failure_Status";
BA_ "GenSigSendType" SG_ 1163 HU_MTO_Failure_Status 7;
BA_ "GenSigCycleTimeActive" SG_ 1163 HU_MTO_Failure_Status 100;
BA_ "GenSigCycleTime" SG_ 1163 HU_MTO_Failure_Status 100;
BA_ "GenSigSendType" SG_ 1163 Telematics_MTO_Failure_status 7;
BA_ "GenSigCycleTimeActive" SG_ 1163 Telematics_MTO_Failure_status 100;
BA_ "GenSigCycleTime" SG_ 1163 Telematics_MTO_Failure_status 100;
BA_ "GenSigSendType" SG_ 1163 SRS_MTO_Failure_Status 7;
BA_ "GenSigCycleTimeActive" SG_ 1163 SRS_MTO_Failure_Status 100;
BA_ "GenSigCycleTime" SG_ 1163 SRS_MTO_Failure_Status 100;
BA_ "GenSigTimeoutTime_HU_Mid_X451" SG_ 1163 VCUMToFailureStatus 0;
BA_ "GenSigTimeoutTime_HU_High_X451" SG_ 1163 VCUMToFailureStatus 0;
BA_ "GenSigTimeoutTime_HU_B" SG_ 1163 VCUMToFailureStatus 0;
BA_ "GenSigTimeoutTime_HU_A" SG_ 1163 VCUMToFailureStatus 0;
BA_ "GenSigTimeoutMsg_HU_Mid_X451" SG_ 1163 VCUMToFailureStatus 0;
BA_ "GenSigTimeoutMsg_HU_High_X451" SG_ 1163 VCUMToFailureStatus 0;
BA_ "GenSigTimeoutMsg_HU_B" SG_ 1163 VCUMToFailureStatus 0;
BA_ "GenSigTimeoutMsg_HU_A" SG_ 1163 VCUMToFailureStatus 0;
BA_ "GenSigSendType" SG_ 1163 VCUMToFailureStatus 7;
BA_ "GenSigCycleTimeActive" SG_ 1163 VCUMToFailureStatus 100;
BA_ "GenSigCycleTime" SG_ 1163 VCUMToFailureStatus 100;
BA_ "GenSigTimeoutTime_HU_Mid_X451" SG_ 1163 VCUInvalidFailureStatus 0;
BA_ "GenSigTimeoutTime_HU_High_X451" SG_ 1163 VCUInvalidFailureStatus 0;
BA_ "GenSigTimeoutTime_HU_B" SG_ 1163 VCUInvalidFailureStatus 0;
BA_ "GenSigTimeoutTime_HU_A" SG_ 1163 VCUInvalidFailureStatus 0;
BA_ "GenSigTimeoutMsg_HU_Mid_X451" SG_ 1163 VCUInvalidFailureStatus 0;
BA_ "GenSigTimeoutMsg_HU_High_X451" SG_ 1163 VCUInvalidFailureStatus 0;
BA_ "GenSigTimeoutMsg_HU_B" SG_ 1163 VCUInvalidFailureStatus 0;
BA_ "GenSigTimeoutMsg_HU_A" SG_ 1163 VCUInvalidFailureStatus 0;
BA_ "GenSigSendType" SG_ 1163 VCUInvalidFailureStatus 7;
BA_ "GenSigCycleTimeActive" SG_ 1163 VCUInvalidFailureStatus 100;
BA_ "GenSigCycleTime" SG_ 1163 VCUInvalidFailureStatus 100;
BA_ "GenSigTimeoutTime_HU_B" SG_ 1143 AMT_DCT_Invalid_Failure_Status 0;
BA_ "GenSigTimeoutTime_HU_A" SG_ 1143 AMT_DCT_Invalid_Failure_Status 0;
BA_ "GenSigTimeoutMsg_HU_B" SG_ 1143 AMT_DCT_Invalid_Failure_Status 0;
BA_ "GenSigTimeoutMsg_HU_A" SG_ 1143 AMT_DCT_Invalid_Failure_Status 0;
BA_ "GenSigSendType" SG_ 1143 AMT_DCT_Invalid_Failure_Status 7;
BA_ "GenSigCycleTimeActive" SG_ 1143 AMT_DCT_Invalid_Failure_Status 100;
BA_ "GenSigCycleTime" SG_ 1143 AMT_DCT_Invalid_Failure_Status 100;
BA_ "GenSigTimeoutTime_HU_B" SG_ 1143 EMsInvalidFailureStatus 0;
BA_ "GenSigTimeoutTime_HU_A" SG_ 1143 EMsInvalidFailureStatus 0;
BA_ "GenSigTimeoutMsg_HU_B" SG_ 1143 EMsInvalidFailureStatus 0;
BA_ "GenSigTimeoutMsg_HU_A" SG_ 1143 EMsInvalidFailureStatus 0;
BA_ "GenSigSendType" SG_ 1143 EMsInvalidFailureStatus 7;
BA_ "GenSigCycleTimeActive" SG_ 1143 EMsInvalidFailureStatus 100;
BA_ "GenSigCycleTime" SG_ 1143 EMsInvalidFailureStatus 100;
BA_ "GenSigTimeoutTime_HU_B" SG_ 1143 ESP_Invalid_Failure_Status 0;
BA_ "GenSigTimeoutTime_HU_A" SG_ 1143 ESP_Invalid_Failure_Status 0;
BA_ "GenSigTimeoutMsg_HU_B" SG_ 1143 ESP_Invalid_Failure_Status 0;
BA_ "GenSigTimeoutMsg_HU_A" SG_ 1143 ESP_Invalid_Failure_Status 0;
BA_ "GenSigSendType" SG_ 1143 ESP_Invalid_Failure_Status 7;
BA_ "GenSigCycleTimeActive" SG_ 1143 ESP_Invalid_Failure_Status 100;
BA_ "GenSigCycleTime" SG_ 1143 ESP_Invalid_Failure_Status 100;
BA_ "GenSigTimeoutTime_HU_B" SG_ 1143 AMT_DCT_MTO_Failure_Status 0;
BA_ "GenSigTimeoutTime_HU_A" SG_ 1143 AMT_DCT_MTO_Failure_Status 0;
BA_ "GenSigTimeoutMsg_HU_B" SG_ 1143 AMT_DCT_MTO_Failure_Status 0;
BA_ "GenSigTimeoutMsg_HU_A" SG_ 1143 AMT_DCT_MTO_Failure_Status 0;
BA_ "GenSigSendType" SG_ 1143 AMT_DCT_MTO_Failure_Status 7;
BA_ "GenSigCycleTimeActive" SG_ 1143 AMT_DCT_MTO_Failure_Status 100;
BA_ "GenSigCycleTime" SG_ 1143 AMT_DCT_MTO_Failure_Status 100;
BA_ "GenSigTimeoutTime_HU_Mid_X451" SG_ 1143 TPMS_MTO_Failure_status 0;
BA_ "GenSigTimeoutTime_HU_High_X451" SG_ 1143 TPMS_MTO_Failure_status 0;
BA_ "GenSigTimeoutTime_HU_B" SG_ 1143 TPMS_MTO_Failure_status 0;
BA_ "GenSigTimeoutTime_HU_A" SG_ 1143 TPMS_MTO_Failure_status 0;
BA_ "GenSigTimeoutMsg_HU_Mid_X451" SG_ 1143 TPMS_MTO_Failure_status 0;
BA_ "GenSigTimeoutMsg_HU_High_X451" SG_ 1143 TPMS_MTO_Failure_status 0;
BA_ "GenSigTimeoutMsg_HU_B" SG_ 1143 TPMS_MTO_Failure_status 0;
BA_ "GenSigTimeoutMsg_HU_A" SG_ 1143 TPMS_MTO_Failure_status 0;
BA_ "GenSigSendType" SG_ 1143 TPMS_MTO_Failure_status 7;
BA_ "GenSigCycleTimeActive" SG_ 1143 TPMS_MTO_Failure_status 100;
BA_ "GenSigCycleTime" SG_ 1143 TPMS_MTO_Failure_status 100;
BA_ "GenSigTimeoutTime_HU_B" SG_ 1143 SAS_MTO_Failure_Status 0;
BA_ "GenSigTimeoutTime_HU_A" SG_ 1143 SAS_MTO_Failure_Status 0;
BA_ "GenSigTimeoutMsg_HU_B" SG_ 1143 SAS_MTO_Failure_Status 0;
BA_ "GenSigTimeoutMsg_HU_A" SG_ 1143 SAS_MTO_Failure_Status 0;
BA_ "GenSigSendType" SG_ 1143 SAS_MTO_Failure_Status 7;
BA_ "GenSigCycleTimeActive" SG_ 1143 SAS_MTO_Failure_Status 100;
BA_ "GenSigCycleTime" SG_ 1143 SAS_MTO_Failure_Status 100;
BA_ "GenSigTimeoutTime_HU_Mid_X451" SG_ 1143 EMS_MTO_Failure_Status 0;
BA_ "GenSigTimeoutTime_HU_High_X451" SG_ 1143 EMS_MTO_Failure_Status 0;
BA_ "GenSigTimeoutTime_HU_B" SG_ 1143 EMS_MTO_Failure_Status 0;
BA_ "GenSigTimeoutTime_HU_A" SG_ 1143 EMS_MTO_Failure_Status 0;
BA_ "GenSigTimeoutMsg_HU_Mid_X451" SG_ 1143 EMS_MTO_Failure_Status 0;
BA_ "GenSigTimeoutMsg_HU_High_X451" SG_ 1143 EMS_MTO_Failure_Status 0;
BA_ "GenSigTimeoutMsg_HU_B" SG_ 1143 EMS_MTO_Failure_Status 0;
BA_ "GenSigTimeoutMsg_HU_A" SG_ 1143 EMS_MTO_Failure_Status 0;
BA_ "GenSigSendType" SG_ 1143 EMS_MTO_Failure_Status 7;
BA_ "GenSigCycleTimeActive" SG_ 1143 EMS_MTO_Failure_Status 100;
BA_ "GenSigCycleTime" SG_ 1143 EMS_MTO_Failure_Status 100;
BA_ "GenSigTimeoutTime_HU_B" SG_ 1143 ESP_MTO_Failure_Status 0;
BA_ "GenSigTimeoutTime_HU_A" SG_ 1143 ESP_MTO_Failure_Status 0;
BA_ "GenSigTimeoutMsg_HU_B" SG_ 1143 ESP_MTO_Failure_Status 0;
BA_ "GenSigTimeoutMsg_HU_A" SG_ 1143 ESP_MTO_Failure_Status 0;
BA_ "GenSigSendType" SG_ 1143 ESP_MTO_Failure_Status 7;
BA_ "GenSigCycleTimeActive" SG_ 1143 ESP_MTO_Failure_Status 100;
BA_ "GenSigCycleTime" SG_ 1143 ESP_MTO_Failure_Status 100;
BA_ "GenSigTimeoutTime_HU_B" SG_ 1143 BattVolt_TM 0;
BA_ "GenSigTimeoutTime_HU_A" SG_ 1143 BattVolt_TM 0;
BA_ "GenSigTimeoutMsg_HU_B" SG_ 1143 BattVolt_TM 0;
BA_ "GenSigTimeoutMsg_HU_A" SG_ 1143 BattVolt_TM 0;
BA_ "GenSigSendType" SG_ 1143 BattVolt_TM 7;
BA_ "GenSigCycleTimeActive" SG_ 1143 BattVolt_TM 100;
BA_ "GenSigCycleTime" SG_ 1143 BattVolt_TM 100;
BA_ "GenSigTimeoutTime_HU_Mid_X451" SG_ 1143 SRS_MTO_Failure_Status 0;
BA_ "GenSigTimeoutTime_HU_High_X451" SG_ 1143 SRS_MTO_Failure_Status 0;
BA_ "GenSigTimeoutTime_HU_B" SG_ 1143 SRS_MTO_Failure_Status 0;
BA_ "GenSigTimeoutTime_HU_A" SG_ 1143 SRS_MTO_Failure_Status 0;
BA_ "GenSigTimeoutMsg_HU_Mid_X451" SG_ 1143 SRS_MTO_Failure_Status 0;
BA_ "GenSigTimeoutMsg_HU_High_X451" SG_ 1143 SRS_MTO_Failure_Status 0;
BA_ "GenSigTimeoutMsg_HU_B" SG_ 1143 SRS_MTO_Failure_Status 0;
BA_ "GenSigTimeoutMsg_HU_A" SG_ 1143 SRS_MTO_Failure_Status 0;
BA_ "GenSigSendType" SG_ 1143 SRS_MTO_Failure_Status 7;
BA_ "GenSigCycleTimeActive" SG_ 1143 SRS_MTO_Failure_Status 100;
BA_ "GenSigCycleTime" SG_ 1143 SRS_MTO_Failure_Status 100;
BA_ "GenSigTimeoutTime_HU_Mid_X451" SG_ 1143 PEPS_MTO_Failure_Status 0;
BA_ "GenSigTimeoutTime_HU_High_X451" SG_ 1143 PEPS_MTO_Failure_Status 0;
BA_ "GenSigTimeoutTime_HU_B" SG_ 1143 PEPS_MTO_Failure_Status 0;
BA_ "GenSigTimeoutTime_HU_A" SG_ 1143 PEPS_MTO_Failure_Status 0;
BA_ "GenSigTimeoutMsg_HU_Mid_X451" SG_ 1143 PEPS_MTO_Failure_Status 0;
BA_ "GenSigTimeoutMsg_HU_High_X451" SG_ 1143 PEPS_MTO_Failure_Status 0;
BA_ "GenSigTimeoutMsg_HU_B" SG_ 1143 PEPS_MTO_Failure_Status 0;
BA_ "GenSigTimeoutMsg_HU_A" SG_ 1143 PEPS_MTO_Failure_Status 0;
BA_ "GenSigSendType" SG_ 1143 PEPS_MTO_Failure_Status 7;
BA_ "GenSigCycleTimeActive" SG_ 1143 PEPS_MTO_Failure_Status 100;
BA_ "GenSigCycleTime" SG_ 1143 PEPS_MTO_Failure_Status 100;
BA_ "GenSigTimeoutTime_HU_Mid_X451" SG_ 1143 PEPS_Invalid_failure_status 0;
BA_ "GenSigTimeoutTime_HU_High_X451" SG_ 1143 PEPS_Invalid_failure_status 0;
BA_ "GenSigTimeoutTime_HU_B" SG_ 1143 PEPS_Invalid_failure_status 0;
BA_ "GenSigTimeoutTime_HU_A" SG_ 1143 PEPS_Invalid_failure_status 0;
BA_ "GenSigTimeoutMsg_HU_Mid_X451" SG_ 1143 PEPS_Invalid_failure_status 0;
BA_ "GenSigTimeoutMsg_HU_High_X451" SG_ 1143 PEPS_Invalid_failure_status 0;
BA_ "GenSigTimeoutMsg_HU_B" SG_ 1143 PEPS_Invalid_failure_status 0;
BA_ "GenSigTimeoutMsg_HU_A" SG_ 1143 PEPS_Invalid_failure_status 0;
BA_ "GenSigSendType" SG_ 1143 PEPS_Invalid_failure_status 7;
BA_ "GenSigCycleTimeActive" SG_ 1143 PEPS_Invalid_failure_status 100;
BA_ "GenSigCycleTime" SG_ 1143 PEPS_Invalid_failure_status 100;
BA_ "GenSigTimeoutTime_HU_Mid_X451" SG_ 1143 IPcMToFailureStatus 0;
BA_ "GenSigTimeoutTime_HU_High_X451" SG_ 1143 IPcMToFailureStatus 0;
BA_ "GenSigTimeoutTime_HU_B" SG_ 1143 IPcMToFailureStatus 0;
BA_ "GenSigTimeoutTime_HU_A" SG_ 1143 IPcMToFailureStatus 0;
BA_ "GenSigTimeoutMsg_HU_Mid_X451" SG_ 1143 IPcMToFailureStatus 0;
BA_ "GenSigTimeoutMsg_HU_High_X451" SG_ 1143 IPcMToFailureStatus 0;
BA_ "GenSigTimeoutMsg_HU_B" SG_ 1143 IPcMToFailureStatus 0;
BA_ "GenSigTimeoutMsg_HU_A" SG_ 1143 IPcMToFailureStatus 0;
BA_ "GenSigSendType" SG_ 1143 IPcMToFailureStatus 7;
BA_ "GenSigCycleTimeActive" SG_ 1143 IPcMToFailureStatus 100;
BA_ "GenSigCycleTime" SG_ 1143 IPcMToFailureStatus 100;
BA_ "GenSigTimeoutTime_HU_Mid_X451" SG_ 1143 IPcInvalidFailureStatus 0;
BA_ "GenSigTimeoutTime_HU_High_X451" SG_ 1143 IPcInvalidFailureStatus 0;
BA_ "GenSigTimeoutTime_HU_B" SG_ 1143 IPcInvalidFailureStatus 0;
BA_ "GenSigTimeoutTime_HU_A" SG_ 1143 IPcInvalidFailureStatus 0;
BA_ "GenSigTimeoutMsg_HU_Mid_X451" SG_ 1143 IPcInvalidFailureStatus 0;
BA_ "GenSigTimeoutMsg_HU_High_X451" SG_ 1143 IPcInvalidFailureStatus 0;
BA_ "GenSigTimeoutMsg_HU_B" SG_ 1143 IPcInvalidFailureStatus 0;
BA_ "GenSigTimeoutMsg_HU_A" SG_ 1143 IPcInvalidFailureStatus 0;
BA_ "GenSigSendType" SG_ 1143 IPcInvalidFailureStatus 7;
BA_ "GenSigCycleTimeActive" SG_ 1143 IPcInvalidFailureStatus 100;
BA_ "GenSigCycleTime" SG_ 1143 IPcInvalidFailureStatus 100;
BA_ "GenSigTimeoutTime_HU_Mid_X451" SG_ 1143 ESClMToFailureStatus 0;
BA_ "GenSigTimeoutTime_HU_High_X451" SG_ 1143 ESClMToFailureStatus 0;
BA_ "GenSigTimeoutTime_HU_B" SG_ 1143 ESClMToFailureStatus 0;
BA_ "GenSigTimeoutTime_HU_A" SG_ 1143 ESClMToFailureStatus 0;
BA_ "GenSigTimeoutMsg_HU_Mid_X451" SG_ 1143 ESClMToFailureStatus 0;
BA_ "GenSigTimeoutMsg_HU_High_X451" SG_ 1143 ESClMToFailureStatus 0;
BA_ "GenSigTimeoutMsg_HU_B" SG_ 1143 ESClMToFailureStatus 0;
BA_ "GenSigTimeoutMsg_HU_A" SG_ 1143 ESClMToFailureStatus 0;
BA_ "GenSigSendType" SG_ 1143 ESClMToFailureStatus 7;
BA_ "GenSigCycleTimeActive" SG_ 1143 ESClMToFailureStatus 100;
BA_ "GenSigCycleTime" SG_ 1143 ESClMToFailureStatus 100;
BA_ "GenSigTimeoutTime_HU_Mid_X451" SG_ 1143 EPAS_MTO_Failure_Status 0;
BA_ "GenSigTimeoutTime_HU_High_X451" SG_ 1143 EPAS_MTO_Failure_Status 0;
BA_ "GenSigTimeoutTime_HU_B" SG_ 1143 EPAS_MTO_Failure_Status 0;
BA_ "GenSigTimeoutTime_HU_A" SG_ 1143 EPAS_MTO_Failure_Status 0;
BA_ "GenSigTimeoutMsg_HU_Mid_X451" SG_ 1143 EPAS_MTO_Failure_Status 0;
BA_ "GenSigTimeoutMsg_HU_High_X451" SG_ 1143 EPAS_MTO_Failure_Status 0;
BA_ "GenSigTimeoutMsg_HU_B" SG_ 1143 EPAS_MTO_Failure_Status 0;
BA_ "GenSigTimeoutMsg_HU_A" SG_ 1143 EPAS_MTO_Failure_Status 0;
BA_ "GenSigSendType" SG_ 1143 EPAS_MTO_Failure_Status 7;
BA_ "GenSigCycleTimeActive" SG_ 1143 EPAS_MTO_Failure_Status 100;
BA_ "GenSigCycleTime" SG_ 1143 EPAS_MTO_Failure_Status 100;
BA_ "GenSigTimeoutTime_HU_Mid_X451" SG_ 1143 EPAS_Invalid_Failure_Status 0;
BA_ "GenSigTimeoutTime_HU_High_X451" SG_ 1143 EPAS_Invalid_Failure_Status 0;
BA_ "GenSigTimeoutTime_HU_B" SG_ 1143 EPAS_Invalid_Failure_Status 0;
BA_ "GenSigTimeoutTime_HU_A" SG_ 1143 EPAS_Invalid_Failure_Status 0;
BA_ "GenSigTimeoutMsg_HU_Mid_X451" SG_ 1143 EPAS_Invalid_Failure_Status 0;
BA_ "GenSigTimeoutMsg_HU_High_X451" SG_ 1143 EPAS_Invalid_Failure_Status 0;
BA_ "GenSigTimeoutMsg_HU_B" SG_ 1143 EPAS_Invalid_Failure_Status 0;
BA_ "GenSigTimeoutMsg_HU_A" SG_ 1143 EPAS_Invalid_Failure_Status 0;
BA_ "GenSigSendType" SG_ 1143 EPAS_Invalid_Failure_Status 7;
BA_ "GenSigCycleTimeActive" SG_ 1143 EPAS_Invalid_Failure_Status 100;
BA_ "GenSigCycleTime" SG_ 1143 EPAS_Invalid_Failure_Status 100;
BA_ "GenSigTimeoutTime_HU_Mid_X451" SG_ 1143 CCM_MTO_Failure_Status 0;
BA_ "GenSigTimeoutTime_HU_High_X451" SG_ 1143 CCM_MTO_Failure_Status 0;
BA_ "GenSigTimeoutTime_HU_B" SG_ 1143 CCM_MTO_Failure_Status 0;
BA_ "GenSigTimeoutTime_HU_A" SG_ 1143 CCM_MTO_Failure_Status 0;
BA_ "GenSigTimeoutMsg_HU_Mid_X451" SG_ 1143 CCM_MTO_Failure_Status 0;
BA_ "GenSigTimeoutMsg_HU_High_X451" SG_ 1143 CCM_MTO_Failure_Status 0;
BA_ "GenSigTimeoutMsg_HU_B" SG_ 1143 CCM_MTO_Failure_Status 0;
BA_ "GenSigTimeoutMsg_HU_A" SG_ 1143 CCM_MTO_Failure_Status 0;
BA_ "GenSigSendType" SG_ 1143 CCM_MTO_Failure_Status 7;
BA_ "GenSigCycleTimeActive" SG_ 1143 CCM_MTO_Failure_Status 100;
BA_ "GenSigCycleTime" SG_ 1143 CCM_MTO_Failure_Status 100;
BA_ "GenSigTimeoutTime_HU_Mid_X451" SG_ 1143 CCM_Invalid_Failure_Status 0;
BA_ "GenSigTimeoutTime_HU_High_X451" SG_ 1143 CCM_Invalid_Failure_Status 0;
BA_ "GenSigTimeoutTime_HU_B" SG_ 1143 CCM_Invalid_Failure_Status 0;
BA_ "GenSigTimeoutTime_HU_A" SG_ 1143 CCM_Invalid_Failure_Status 0;
BA_ "GenSigTimeoutMsg_HU_Mid_X451" SG_ 1143 CCM_Invalid_Failure_Status 0;
BA_ "GenSigTimeoutMsg_HU_High_X451" SG_ 1143 CCM_Invalid_Failure_Status 0;
BA_ "GenSigTimeoutMsg_HU_B" SG_ 1143 CCM_Invalid_Failure_Status 0;
BA_ "GenSigTimeoutMsg_HU_A" SG_ 1143 CCM_Invalid_Failure_Status 0;
BA_ "GenSigSendType" SG_ 1143 CCM_Invalid_Failure_Status 7;
BA_ "GenSigCycleTimeActive" SG_ 1143 CCM_Invalid_Failure_Status 100;
BA_ "GenSigCycleTime" SG_ 1143 CCM_Invalid_Failure_Status 100;
BA_ "GenSigTimeoutTime_HU_Mid_X451" SG_ 1143 BCmMToFailureStatus 0;
BA_ "GenSigTimeoutTime_HU_High_X451" SG_ 1143 BCmMToFailureStatus 0;
BA_ "GenSigTimeoutTime_HU_B" SG_ 1143 BCmMToFailureStatus 0;
BA_ "GenSigTimeoutTime_HU_A" SG_ 1143 BCmMToFailureStatus 0;
BA_ "GenSigTimeoutMsg_HU_Mid_X451" SG_ 1143 BCmMToFailureStatus 0;
BA_ "GenSigTimeoutMsg_HU_High_X451" SG_ 1143 BCmMToFailureStatus 0;
BA_ "GenSigTimeoutMsg_HU_B" SG_ 1143 BCmMToFailureStatus 0;
BA_ "GenSigTimeoutMsg_HU_A" SG_ 1143 BCmMToFailureStatus 0;
BA_ "GenSigSendType" SG_ 1143 BCmMToFailureStatus 7;
BA_ "GenSigCycleTimeActive" SG_ 1143 BCmMToFailureStatus 100;
BA_ "GenSigCycleTime" SG_ 1143 BCmMToFailureStatus 100;
BA_ "GenSigTimeoutTime_HU_Mid_X451" SG_ 1143 BCmInvalidFailureStatus 0;
BA_ "GenSigTimeoutTime_HU_High_X451" SG_ 1143 BCmInvalidFailureStatus 0;
BA_ "GenSigTimeoutTime_HU_B" SG_ 1143 BCmInvalidFailureStatus 0;
BA_ "GenSigTimeoutTime_HU_A" SG_ 1143 BCmInvalidFailureStatus 0;
BA_ "GenSigTimeoutMsg_HU_Mid_X451" SG_ 1143 BCmInvalidFailureStatus 0;
BA_ "GenSigTimeoutMsg_HU_High_X451" SG_ 1143 BCmInvalidFailureStatus 0;
BA_ "GenSigTimeoutMsg_HU_B" SG_ 1143 BCmInvalidFailureStatus 0;
BA_ "GenSigTimeoutMsg_HU_A" SG_ 1143 BCmInvalidFailureStatus 0;
BA_ "GenSigSendType" SG_ 1143 BCmInvalidFailureStatus 7;
BA_ "GenSigCycleTimeActive" SG_ 1143 BCmInvalidFailureStatus 100;
BA_ "GenSigCycleTime" SG_ 1143 BCmInvalidFailureStatus 100;
BA_ "GenSigTimeoutTime_HU_Mid_X451" SG_ 1143 Telematics_SW_Version 0;
BA_ "GenSigTimeoutTime_HU_High_X451" SG_ 1143 Telematics_SW_Version 0;
BA_ "GenSigTimeoutTime_HU_B" SG_ 1143 Telematics_SW_Version 0;
BA_ "GenSigTimeoutTime_HU_A" SG_ 1143 Telematics_SW_Version 0;
BA_ "GenSigTimeoutMsg_HU_Mid_X451" SG_ 1143 Telematics_SW_Version 0;
BA_ "GenSigTimeoutMsg_HU_High_X451" SG_ 1143 Telematics_SW_Version 0;
BA_ "GenSigTimeoutMsg_HU_B" SG_ 1143 Telematics_SW_Version 0;
BA_ "GenSigTimeoutMsg_HU_A" SG_ 1143 Telematics_SW_Version 0;
BA_ "GenSigSendType" SG_ 1143 Telematics_SW_Version 7;
BA_ "GenSigCycleTimeActive" SG_ 1143 Telematics_SW_Version 100;
BA_ "GenSigCycleTime" SG_ 1143 Telematics_SW_Version 100;
BA_ "GenSigTimeoutTime_HU_Mid_X451" SG_ 1143 Telematics_EP_Failure_Status 0;
BA_ "GenSigTimeoutTime_HU_High_X451" SG_ 1143 Telematics_EP_Failure_Status 0;
BA_ "GenSigTimeoutTime_HU_B" SG_ 1143 Telematics_EP_Failure_Status 0;
BA_ "GenSigTimeoutTime_HU_A" SG_ 1143 Telematics_EP_Failure_Status 0;
BA_ "GenSigTimeoutMsg_HU_Mid_X451" SG_ 1143 Telematics_EP_Failure_Status 0;
BA_ "GenSigTimeoutMsg_HU_High_X451" SG_ 1143 Telematics_EP_Failure_Status 0;
BA_ "GenSigTimeoutMsg_HU_B" SG_ 1143 Telematics_EP_Failure_Status 0;
BA_ "GenSigTimeoutMsg_HU_A" SG_ 1143 Telematics_EP_Failure_Status 0;
BA_ "GenSigSendType" SG_ 1143 Telematics_EP_Failure_Status 7;
BA_ "GenSigCycleTimeActive" SG_ 1143 Telematics_EP_Failure_Status 100;
BA_ "GenSigCycleTime" SG_ 1143 Telematics_EP_Failure_Status 100;
BA_ "GenSigTimeoutTime_HU_Mid_X451" SG_ 1143 Telematics_BO_Failure_Status 0;
BA_ "GenSigTimeoutTime_HU_High_X451" SG_ 1143 Telematics_BO_Failure_Status 0;
BA_ "GenSigTimeoutTime_HU_B" SG_ 1143 Telematics_BO_Failure_Status 0;
BA_ "GenSigTimeoutTime_HU_A" SG_ 1143 Telematics_BO_Failure_Status 0;
BA_ "GenSigTimeoutMsg_HU_Mid_X451" SG_ 1143 Telematics_BO_Failure_Status 0;
BA_ "GenSigTimeoutMsg_HU_High_X451" SG_ 1143 Telematics_BO_Failure_Status 0;
BA_ "GenSigTimeoutMsg_HU_B" SG_ 1143 Telematics_BO_Failure_Status 0;
BA_ "GenSigTimeoutMsg_HU_A" SG_ 1143 Telematics_BO_Failure_Status 0;
BA_ "GenSigSendType" SG_ 1143 Telematics_BO_Failure_Status 7;
BA_ "GenSigCycleTimeActive" SG_ 1143 Telematics_BO_Failure_Status 100;
BA_ "GenSigCycleTime" SG_ 1143 Telematics_BO_Failure_Status 100;
BA_ "GenSigTimeoutTime_HU_Mid_X451" SG_ 1143 VCUInvalidFailureStatus 0;
BA_ "GenSigTimeoutTime_HU_High_X451" SG_ 1143 VCUInvalidFailureStatus 0;
BA_ "GenSigTimeoutTime_HU_B" SG_ 1143 VCUInvalidFailureStatus 0;
BA_ "GenSigTimeoutTime_HU_A" SG_ 1143 VCUInvalidFailureStatus 0;
BA_ "GenSigTimeoutMsg_HU_Mid_X451" SG_ 1143 VCUInvalidFailureStatus 0;
BA_ "GenSigTimeoutMsg_HU_High_X451" SG_ 1143 VCUInvalidFailureStatus 0;
BA_ "GenSigTimeoutMsg_HU_B" SG_ 1143 VCUInvalidFailureStatus 0;
BA_ "GenSigTimeoutMsg_HU_A" SG_ 1143 VCUInvalidFailureStatus 0;
BA_ "GenSigSendType" SG_ 1143 VCUInvalidFailureStatus 7;
BA_ "GenSigCycleTimeActive" SG_ 1143 VCUInvalidFailureStatus 100;
BA_ "GenSigCycleTime" SG_ 1143 VCUInvalidFailureStatus 100;
BA_ "GenSigTimeoutTime_HU_Mid_X451" SG_ 1143 VCUMToFailureStatus 0;
BA_ "GenSigTimeoutTime_HU_High_X451" SG_ 1143 VCUMToFailureStatus 0;
BA_ "GenSigTimeoutTime_HU_B" SG_ 1143 VCUMToFailureStatus 0;
BA_ "GenSigTimeoutTime_HU_A" SG_ 1143 VCUMToFailureStatus 0;
BA_ "GenSigTimeoutMsg_HU_Mid_X451" SG_ 1143 VCUMToFailureStatus 0;
BA_ "GenSigTimeoutMsg_HU_High_X451" SG_ 1143 VCUMToFailureStatus 0;
BA_ "GenSigTimeoutMsg_HU_B" SG_ 1143 VCUMToFailureStatus 0;
BA_ "GenSigTimeoutMsg_HU_A" SG_ 1143 VCUMToFailureStatus 0;
BA_ "GenSigSendType" SG_ 1143 VCUMToFailureStatus 7;
BA_ "GenSigCycleTimeActive" SG_ 1143 VCUMToFailureStatus 100;
BA_ "GenSigCycleTime" SG_ 1143 VCUMToFailureStatus 100;
VAL_ 458 BCmHuWindowWindingHmiCmdAck 31 "Reserved" 30 "Reserved" 29 "Reserved" 28 "Reserved" 27 "Reserved" 26 "Reserved" 25 "Reserved" 24 "Reserved" 23 "Reserved" 22 "Rear Left Window is already Opened" 21 "Rear Left Window is already Closed" 20 "Rear Left Window is Opening" 19 "Rear Left Window is Closing" 18 "Rear Right Window is already Opened" 17 "Rear Right Window is already Closed" 16 "Rear Right Window is Opening" 15 "Rear Right Window is Closing" 14 "Front Left Window is already Opened" 13 "Front Left Window is already Closed" 12 "Front Left Window is Opening" 11 "Front Left Window is Closing" 10 "Front Right Window is already Opened" 9 "Front Right Window is already Closed" 8 "Front Right Window is Opening" 7 "Front Right Window is Closing" 6 "All Windows are already Opened" 5 "All Windows are already Closed" 4 "All Windows are Opening" 3 "All Windows are Closing" 2 "Issue with Window Winding" 1 "Not supported (TBD)request" 0 "No Action Required" ;
VAL_ 458 BCmHuTyreTempHmiVrCmdAck 15 "Reserved" 14 "Reserved" 13 "Reserved" 12 "Rear Left Tyre Temperature Not Ok" 11 "Rear Left Tyre Temperature Ok" 10 "Rear Right Tyre Temperature Not Ok" 9 "Rear Right Tyre Temperature Ok" 8 "Front Left Tyre Temperature Not Ok" 7 "Front Left Tyre Temperature Ok" 6 "Front Right Tyre Temperature Not Ok" 5 "Front Right Tyre Temperature Ok" 4 "One or more Tyre Temperature Not Ok" 3 "All Tyres Temperature Ok" 2 "Issue with Tyre Temperature reading" 1 "Not supported (TBD)request" 0 "No Action Required" ;
VAL_ 458 BCmHuTyrePressureHmiVrCmdAck 15 "Reserved" 14 "Reserved" 13 "Reserved" 12 "Rear Left Tyre Pressure Not Ok" 11 "Rear Left Tyre Pressure Ok" 10 "Rear Right Tyre Pressure Not Ok" 9 "Rear Right Tyre Pressure Ok" 8 "Front Left Tyre Pressure Not Ok" 7 "Front Left Tyre Pressure Ok " 6 "Front Right Tyre Pressure Not Ok" 5 "Front Right Tyre Pressure Ok" 4 "One or more Tyre Pressure Not Ok" 3 "All Tyres Pressure Ok" 2 "Issue with Tyre Pressure reading" 1 "Not supported (TBD)request" 0 "No Action Required" ;
VAL_ 458 BCmHuRoofLampHmiVrCmdAck 15 "Reserved" 14 "Reserved" 13 "Reserved" 12 "Reserved" 11 "Roof lamp cannot operate due to vehicle crash detected" 10 "Request for all Door closed to operate Roof lamp through Voice command" 9 "Roof lamp Auto switch request" 8 "Roof lamp is ON" 7 "Roof lamp is OFF" 6 "Roof lamp is already turned ON" 5 "Roof lamp is turned ON" 4 "Roof lamp is already turned OFF" 3 "Roof lamp is turned OFF" 2 "Issue with Roof lamp" 1 "Not supported (TBD)request" 0 "No Action Required" ;
VAL_ 458 BCmHuPositionLampVrCmdAck 15 "Reserved" 14 "Reserved" 13 "Reserved" 12 "Reserved" 11 "Reserved" 10 "Reserved" 9 "Position lamp turned OFF through Switch only" 8 "Position lamp is ON" 7 "Position lamp is OFF" 6 "Position lamp is already turned ON" 5 "Position lamp is turned ON" 4 "Position lamp is already turned OFF" 3 "Position lamp is turned OFF" 2 "Issue with Position lamp" 1 "Not supported (TBD)request" 0 "No Action Required" ;
VAL_ 458 BCmHuORVMHmiVrCmdAck 15 "Reserved" 14 "ORVM is adjusting as per Third Memory set" 13 "ORVM is adjusting as per Second Memory set" 12 "ORVM is adjusting as per First Memory set" 11 "Present ORVM setting is stored in Third Memory set" 10 "Present ORVM setting is stored in Second Memory set" 9 "Present ORVM setting is stored in First Memory set" 8 "Left ORVM is Unfolding" 7 "Left ORVM is Folding" 6 "Right ORVM is Unfolding" 5 "Right ORVM is Folding" 4 "Left & Right ORVM are Unfolding" 3 "Left & Right ORVM are Folding" 2 "Issue with ORVM" 1 "Not supported (TBD)request" 0 "No Action Required" ;
VAL_ 458 BCmHuMoodLightVrCmdAck 15 "Reserved" 14 "Reserved" 13 "Reserved" 12 "Reserved" 11 "Reserved" 10 "Reserved" 9 "Reserved" 8 "Mood light is ON" 7 "Mood light is OFF" 6 "Mood light is already turned ON" 5 "Mood light is turned ON" 4 "Mood light is already turned OFF" 3 "Mood light is turned OFF" 2 "Issue with Mood light" 1 "Not supported (TBD)request" 0 "No Action Required" ;
VAL_ 458 BCmHuHazardLampVrCmdAck 15 "Reserved" 14 "Reserved" 13 "Reserved" 12 "Reserved" 11 "Reserved" 10 "Reserved" 9 "Unable to operate Hazard lamp due to load activated by other feature" 8 "Hazard lamp is ON" 7 "Hazard lamp is OFF" 6 "Hazard lamp is already turned ON" 5 "Hazard lamp is turned ON" 4 "Hazard lamp is already turned OFF" 3 "Hazard lamp is turned OFF" 2 "Issue with Hazard lamp" 1 "Not supported (TBD)request" 0 "No Action Required" ;
VAL_ 458 BCmHuDRLVrCmdAck 15 "Reserved" 14 "Reserved" 13 "Reserved" 12 "Reserved" 11 "Reserved" 10 "Reserved" 9 "DRL lamp turned OFF through Switch only" 8 "DRL lamp is ON" 7 "DRL lamp is OFF" 6 "DRL lamp is already turned ON / Activated." 5 "DRL lamp is turned ON / Activate." 4 "DRL lamp is already turned OFF / Deactivated." 3 "DRL lamp is turned OFF / Deactivate" 2 "Issue with DRL lamp" 1 "Not supported (TBD)request" 0 "No Action Required" ;
VAL_ 458 BCmHuAmbientLightVrCmdAck 15 "Reserved" 14 "Reserved" 13 "Reserved" 12 "Reserved" 11 "Reserved" 10 "Reserved" 9 "Reserved" 8 "Ambient light is ON" 7 "Ambient light is OFF" 6 "Ambient light is already turned ON" 5 "Ambient light is turned ON" 4 "Ambient light is already turned OFF" 3 "Ambient light is turned OFF" 2 "Issue with Ambient light" 1 "Not supported (TBD)request" 0 "No Action Required" ;
VAL_ 458 BCmHuTiltVrCmdAck 15 "Reserved " 14 "Reserved " 13 "Reserved " 12 "Current State is Sunroof Tilt Opened" 11 "Current State is Sunroof Tilt Closed" 10 "Unable to execute Tilt Open / Close, because Sunroof is open" 9 "Sunroof Tilt is stuck" 8 "Unable to Tilt open the Sunroof" 7 "Sunroof is already tilted opened" 6 "Tilting Open the Sunroof" 5 "Unable to Tilt close the Sunroof" 4 "Sunroof is already tilted closed" 3 "Tilting Close the Sunroof" 2 "Unknown Error" 1 "Not supported (TBD)" 0 "No Action Required" ;
VAL_ 458 BCmHuSunShadeVrCmdAck 15 "Reserved " 14 "Reserved " 13 "Reserved " 12 "Current State is Sunshade Opened " 11 "Current State is Sunshade Closed " 10 "Unable to Close Sunshade, because Sunroof is open" 9 "Sunshade is stuck" 8 "Unable to open the Sunshade" 7 "Sunshade is already opened" 6 "Opening the Sunshade" 5 "Unable to close the Sunshade" 4 "Sunshade is already closed" 3 "Closing the Sunshade" 2 "Unknown Error" 1 "Not supported (TBD)" 0 "No Action Required" ;
VAL_ 458 BCmHuSunRoofVrCmdAck 15 "Reserved " 14 "Reserved " 13 "Reserved " 12 "Reserved " 11 "Current State is Sunroof Opened " 10 "Current State is Sunroof Closed" 9 "Sunroof is stuck" 8 "Unable to open the Sunroof" 7 "Sunroof is already opened" 6 "Opening the Sunroof" 5 "Unable to close the Sunroof" 4 "Sunroof is already Closed" 3 "Closing the Sunroof" 2 "Unknown Error" 1 "Not supported (TBD)" 0 "No Action Required" ;
VAL_ 567 ApbState_Old 7 "No Action" 6 "APB cannot hold the vehicle-Slope too high" 5 "Dynamic APB apply" 4 "Locking" 3 "Releasing" 2 "Closed" 1 "Released" 0 "Static Release not possible Brake not pressed" ;
VAL_ 567 BrkPaddleTravel2Status 3 "Signal not available" 2 "Information given is implausible" 1 "Reserved for future use " 0 "Plausible  - Information given is correct" ;
VAL_ 567 MCMsAvailability 1 "MCMS function not available" 0 "MCMS function available" ;
VAL_ 567 BrkPaddleTravel1Status 3 "Signal not available" 2 "Information given is implausible" 1 "Reserved for future use " 0 "Plausible  - Information given is correct" ;
VAL_ 567 MCMsErrorState 1 "MCMS switched off due to a detected failure at ESP system" 0 "MCMS fully available @ MFL is OFF" ;
VAL_ 567 MCMsActive 1 "MCMS intervention by ESP system is active @ tale tell/Text info ON" 0 "No MCMS intervention by ESP system @ tale tell/Text info OFF" ;
VAL_ 567 APbBeepState 7 "Reserved" 6 "Reserved" 5 "Reserved" 4 "Diagnosis Beep" 3 "Soft cyclic beep" 2 "Strong Cyclic Beep" 1 "Delayed Single Beep" 0 "No Beep" ;
VAL_ 567 AVhStatus 1 "AVH  function switched off due to detected failure at ESP" 0 "AVH function fully available" ;
VAL_ 567 AVhState 3 "Reserved" 2 "AVH Standby" 1 "AVH Active" 0 "AVH OFF" ;
VAL_ 567 AVhAvailability 1 "AVH  Not available" 0 "AVH Available" ;
VAL_ 567 APbState 9 "Unknown" 8 "APB Auto release not possible- Driver seat belt unbuckled/ Driver door open" 7 "No Action" 6 "APB cannot hold the vehicle-Slope too high" 5 "Dynamic APB apply" 4 "Locking" 3 "Releasing" 2 "Closed" 1 "Released" 0 "Static Relaese not possible Brake not pressed		

" ;
VAL_ 567 APbErrorState 3 "Diagnosis" 2 "High severity error" 1 "No Error" 0 "Low Severity error" ;
VAL_ 567 APbAvailability 1 "APBMi Not available" 0 "APBMi Available" ;
VAL_ 280 BrakePaddlePosStatus 3 "Signal Not available" 2 "BrakePaddlePos signal Value is implausible" 1 "Reserved" 0 "Information given by BrakePaddlePos is correct and according to specification" ;
VAL_ 280 TarRecupTrqStatus 3 "Signal TarRegenTrq not available" 2 "Information given is implausible" 1 "Reserved for future use" 0 "Information given  is correct" ;
VAL_ 280 InhibitCostRecuprationStatus 3 "Reserved for future use" 2 "Information given is implausible" 1 "Reserved for future use" 0 "Information given  is correct" ;
VAL_ 280 InhibitCostRecupration 1 "Enable" 0 "Disable" ;
VAL_ 280 InhibitRecuprationAbsStatus 3 "Reserved for future use" 2 "Information given is implausible" 1 "Reserved for future use" 0 "Information given  is correct" ;
VAL_ 280 InhibitRecuprationAbs 1 "Recupration request is active" 0 "Recupration request is not active" ;
VAL_ 452 CarAnniversaryResponse 1 "Message successfully displayed" 0 "No message displayed" ;
VAL_ 452 OwnersBirthdayResponse 1 "Message successfully displayed" 0 "No message displayed" ;
VAL_ 452 OwnersAnniversaryResponse 1 "Message successfully displayed" 0 "No message displayed" ;
VAL_ 963 GPsInfoXYZStatus 3 "Signal Not Available" 2 "Signal value is implausible" 1 "Reserved for future use" 0 "Plausible  - Information given is correct" ;
VAL_ 960 TimeZone 39 "UTC+14" 38 "UTC+13:45" 37 "UTC+13" 36 "UTC+12:45" 35 "UTC+12" 34 "UTC+11" 33 "UTC+10:30" 32 "UTC+10" 31 "UTC+09:30" 30 "UTC+09" 29 "UTC+08:45" 28 "UTC+08" 27 "UTC+07" 26 "UTC+06:30" 25 "UTC+06" 24 "UTC+5:45" 23 "UTC+05:30" 22 "UTC+05" 21 "UTC+04:30" 20 "UTC+04" 19 "UTC+03:30" 18 "UTC+03" 17 "UTC+02" 16 "UTC+01" 15 "UTC-00" 14 "UTC-01" 13 "UTC-02" 12 "UTC-02:30" 11 "UTC-03" 10 "UTC-03:30" 9 "UTC-04" 8 "UTC-05" 7 "UTC-06" 6 "UTC-07" 5 "UTC-08" 4 "UTC-09" 3 "UTC-09:30" 2 "UTC-10" 1 "UTC-11" 0 "UTC-12" ;
VAL_ 960 GSmSignalType 7 "Reserved" 6 "Reserved" 5 "Reserved" 4 "5G" 3 "4G" 2 "3G" 1 "2G" 0 "No Signal" ;
VAL_ 960 GSmSignalStrength 7 "Reserved" 6 "Reserved" 5 "5" 4 "4" 3 "3" 2 "2" 1 "1" 0 "No Signal" ;
VAL_ 960 GSmSignalStatus 3 "SNA" 2 "Implausible" 1 "Reserved" 0 "Plausible" ;
VAL_ 960 GPsFix 3 "Reserved" 2 "3D Fix" 1 "2D Fix" 0 "No Fix" ;
VAL_ 960 DateTimeStatus 3 "SNA" 2 "Implausible" 1 "Reserved" 0 "Plausible" ;
VAL_ 960 GPsCourseInfoStatus 3 "Signal Not Available" 2 "Signal value is implausible" 1 "Reserved for future use." 0 "Plausible  - Information given is correct and according to specification" ;
VAL_ 944 TCmHuUsbCommRequest 1 "Not Required" 0 "Required" ;
VAL_ 944 TCmHuUsbRoleState 3 "Role Reversal Inprogress" 2 "Host" 1 "Device" 0 "Not Ready" ;
VAL_ 944 TCmHuUSBCommChannelCapability 1 "Available" 0 "Not Available" ;
VAL_ 944 TCmHuReInitPhysicalConnection 1 "Request for Reinitialize" 0 "Not Requested" ;
VAL_ 944 TCmHuEth100BaseTCommChannelCapab 1 "Available" 0 "Not Available" ;
VAL_ 944 TCmHuEth1000BaseTCommChannelCapa 1 "Available" 0 "Not Available" ;
VAL_ 944 TCmHuErrorDiagnostic 30 "Reserved" 29 "Reserved" 28 "Reserved" 27 "Reserved" 26 "Reserved" 25 "Reserved" 24 "Reserved" 23 "Reserved" 22 "Reserved" 21 "Reserved" 20 "Reserved" 19 "Reserved" 18 "Reserved" 17 "Reserved" 16 "Reserved" 15 "Reserved" 14 "Reserved" 13 "Reserved" 12 "Reserved" 11 "Reserved" 10 "Reserved" 9 "Reserved" 8 "Reserved" 7 "Reserved" 6 "Reserved" 5 "Reserved" 4 "Reserved" 3 "Reserved" 2 "Reserved" 1 "Reserved" 0 "No Error" ;
VAL_ 944 TCmHuCommInterfaceState 7 "Reserved" 6 "Reserved" 5 "Reserved" 4 "Reserved" 3 "Reserved" 2 "Established" 1 "Ready & Not Established" 0 "Not Ready" ;
VAL_ 944 TCmHuChangeRoleRequest 3 "Reserved" 2 "Host" 1 "Device" 0 "No Role Change Request" ;
VAL_ 944 TCmHuAuthenticationState 3 "Not Supported" 2 "Authentication Success" 1 "Authentication Failed" 0 "Not Initiated" ;
VAL_ 952 HuTcmUsbCommRequest 1 "Not Required" 0 "Required" ;
VAL_ 952 HuTCmUsbRoleState 3 "Role Reversal Inprogress" 2 "Host" 1 "Device" 0 "Not Ready" ;
VAL_ 952 HuTCmUSBCommChannelCapability 1 "Available" 0 "Not Available" ;
VAL_ 952 HuTCmUSBChangeRoleRequest 3 "Reserved" 2 "Host" 1 "Device" 0 "No Role Change Request" ;
VAL_ 952 HuTCmReInitPhysicalConnection 1 "Request for Reinitialize" 0 "Not Requested" ;
VAL_ 952 HuTCmEth100BaseTCommChannelCapab 1 "Available" 0 "Not Available" ;
VAL_ 952 HuTCmEth1000BaseTCommChannelCapa 1 "Available" 0 "Not Available" ;
VAL_ 952 HuTCmErrorDiagnostic 30 "Reserved" 29 "Reserved" 28 "Reserved" 27 "Reserved" 26 "Reserved" 25 "Reserved" 24 "Reserved" 23 "Reserved" 22 "Reserved" 21 "Reserved" 20 "Reserved" 19 "Reserved" 18 "Reserved" 17 "Reserved" 16 "Reserved" 15 "Reserved" 14 "Reserved" 13 "Reserved" 12 "Reserved" 11 "Reserved" 10 "Reserved" 9 "Reserved" 8 "Reserved" 7 "Reserved" 6 "Reserved" 5 "Reserved" 4 "Reserved" 3 "Reserved" 2 "Reserved" 1 "Reserved" 0 "No Error" ;
VAL_ 952 HuTCmCommInterfaceState 7 "Reserved" 6 "Reserved" 5 "Reserved" 4 "Reserved" 3 "Reserved" 2 "Established" 1 "Ready & Not Established" 0 "Not Ready" ;
VAL_ 952 HuTCmAuthenticationState 3 "Not Supported" 2 "Authentication Success" 1 "Authentication Failed" 0 "Not Initiated" ;
VAL_ 582 SILTelltaleVcuStatus 3 "Reserved" 2 "Information given is implausible due to a detected failure " 1 "Reserved" 0 "Information given correct and according to specification" ;
VAL_ 582 SILTelltaleVcu 7 "Reserved	" 6 "Reserved	" 5 "Reserved	" 4 "SIL Telltale Lamp Red Color On" 3 "SIL Telltale Lamp Red Color Blink" 2 "SIL Telltale Lamp Orange Color On" 1 "SIL Telltale Lamp Orange Color Blink" 0 "SIL Telltale Lamp  off" ;
VAL_ 582 AvgEnergyConsmpTripBStatus 3 "Signal Not Available" 2 "Information given is implausible due to a detected failure" 1 "Reserved" 0 "Information given is correct and according to specification" ;
VAL_ 582 AvgEnergyConsmpTripAStatus 3 "Signal Not Available" 2 "Information given is implausible due to a detected failure" 1 "Reserved" 0 "Information given is correct and according to specification" ;
VAL_ 582 AvgEnergyConsmpTripB 511 "Information Initialization in progress due to Reset" ;
VAL_ 582 AvgEnergyConsmpTripA 511 "Information Initialization in progress due to Reset" ;
VAL_ 582 InstPwrConsumpStatus 3 "Signal Not Available" 2 "Information given is implausible" 1 "Reserved" 0 "Information given is correct" ;
VAL_ 582 InstPwrConsump 255 "Information Initialization in progress due to Reset" ;
VAL_ 1289 PreviousState_ESP 7 "Reserved" 6 "Reserved" 5 "Reserved" 4 "Bus Sleep State" 3 "Prepare Bus Sleep State" 2 "Ready Sleep State" 1 "Normal Operation State" 0 "Repeat Message State" ;
VAL_ 1289 RepeatMessageReq_ESP 1 "Reserved" 0 "Repeat message state not requested" ;
VAL_ 1289 CurrentState_ESP 1 "Normal Operation State" 0 "Repeat Messgae State" ;
VAL_ 1289 ActiveWakeUp_ESP 1 "Node has  woken up the network(Active wakeup)" 0 "Node has not woken up the network(Passive wakeup)" ;
VAL_ 719 ComfortState 1 "Comfort level reached" 0 "Comfort level not reached" ;
VAL_ 719 PtcHtrCoilCntrlStatus 3 "Reserved" 2 "Information given is implausible due to a detected failure " 1 "Reserved" 0 "Information given correct and according to specification" ;
VAL_ 719 PtcHtrCoilCntrl 15 "Coil 1 : ON Coil 2: ON Coil 3 : ON Coil 4 : ON" 14 "Coil 1 : OFF Coil 2: ON Coil 3 : ON Coil 4 : ON" 13 "Coil 1 : ON Coil 2: OFF Coil 3 : ON Coil 4 : ON" 12 "Coil 1 : OFF Coil 2: OFF Coil 3 : ON Coil 4 : ON" 11 "Coil 1 : ON Coil 2: ON Coil 3 : OFF Coil 4 : ON" 10 "Coil 1 : OFF Coil 2: ON Coil 3 : OFF Coil 4 : ON" 9 "Coil 1 : ON Coil 2: OFF Coil 3 : OFF Coil 4 : ON" 8 "Coil 1 : OFF Coil 2: OFF Coil 3 : OFF Coil 4 : ON" 7 "Coil 1 : ON Coil 2: ON Coil 3 : ON Coil 4 : OFF" 6 "Coil 1 : OFF Coil 2: ON Coil 3 : ON Coil 4 : OFF" 5 "Coil 1 : ON Coil 2: OFF Coil 3 : ON Coil 4 : OFF" 4 "Coil 1 : OFF Coil 2: OFF Coil 3 : ON Coil 4 : OFF" 3 "Coil 1 : ON Coil 2: ON Coil 3 : OFF Coil 4 : OFF" 2 "Coil 1 : OFF Coil 2: ON Coil 3 : OFF Coil 4 : OFF" 1 "Coil 1 : ON Coil 2: OFF Coil 3 : OFF Coil 4 : OFF" 0 "Coil 1 : OFF Coil 2: OFF Coil 3 : OFF Coil 4 : OFF" ;
VAL_ 719 PtcHtrForcedCutoff 3 "Signal not available" 2 "Forced cutoff required" 1 "Reserved for future use" 0 "Forced Cutoff not required" ;
VAL_ 719 ComfortStateStatus 3 "Signal not available" 2 "Implausible" 1 "Reserved for future use" 0 "Plausible and signal is correct" ;
VAL_ 719 ValetStateStatus 3 "Signal not available" 2 "Signal is implausible" 1 "Reserved for future use" 0 "Plausible and signal is correct" ;
VAL_ 719 ValetState 1 "Valet Mode Enabled" 0 "Valet Mode Disabled" ;
VAL_ 1163 SRS_CRC_Failure_Status 3 "Reserved" 2 "Failure healed Ageing in progress" 1 "Failure matured & DTC in memory" 0 "Failure is not detected" ;
VAL_ 1163 SRS_MRC_Failure_Status 3 "Reserved" 2 "Failure healed Ageing in progress" 1 "Failure matured & DTC in memory" 0 "Failure is not detected" ;
VAL_ 1163 SRS_Invalid_Failure_Status 3 "Reserved" 2 "Failure healed aging in progress" 1 "Failure matured & DTC in memory" 0 "Failure is not detected" ;
VAL_ 1163 Telematics_Invalid_Failure_Statu 3 "Reserved" 2 "Failure healed aging in progress" 1 "Failure matured & DTC in memory" 0 "Failure is not detected" ;
VAL_ 1163 HU_MTO_Failure_Status 3 "Reserved" 2 "Failure healed aging in progress" 1 "Failrue detected DTC in mem" 0 "Failure is not detected" ;
VAL_ 1163 Telematics_MTO_Failure_status 3 "Reserved" 2 "Failure healed aging in progress" 1 "Failure matured & DTC in memory" 0 "Failure is not detected" ;
VAL_ 1163 SRS_MTO_Failure_Status 3 "Reserved" 2 "Failure healed aging in progress" 1 "Failure detected DTC in Memory" 0 "Failure is not detected" ;
VAL_ 1163 VCUMToFailureStatus 3 "Reserved" 2 "Failure healed aging in progress" 1 "Failure matured & DTC in memory" 0 "Failure is not detected" ;
VAL_ 1163 VCUInvalidFailureStatus 3 "Reserved" 2 "Failure healed aging in progress" 1 "Failure matured & DTC in memory" 0 "Failure is not detected" ;
VAL_ 1143 AMT_DCT_Invalid_Failure_Status 3 "Reserved" 2 "Failure healed Ageing in progress" 1 "Failure matured & DTC in memory" 0 "Failure is not detected" ;
VAL_ 1143 EMsInvalidFailureStatus 3 "Reserved" 2 "Failure healed Ageing in progress" 1 "Failure matured & DTC in memory" 0 "Failure is not detected" ;
VAL_ 1143 ESP_Invalid_Failure_Status 3 "Reserved" 2 "Ageing in progress" 1 "fail detected and DTC  in memory" 0 "failure not detected" ;
VAL_ 1143 AMT_DCT_MTO_Failure_Status 3 "Reserved" 2 "Failure healed Ageing in progress" 1 "Failure matured & DTC in memory" 0 "Failure is not detected" ;
VAL_ 1143 TPMS_MTO_Failure_status 3 "Reseved" 2 "Failure healed and ageing in process" 1 "Failure is detected and DTC in memory" 0 "Failure is not detected" ;
VAL_ 1143 SAS_MTO_Failure_Status 3 "Reserved" 2 "Failure healed aging in progress" 1 "Failure detected; DTC in memory" 0 "Failure is not detected" ;
VAL_ 1143 EMS_MTO_Failure_Status 3 "Reserved" 2 "Failure is cleared and DTC is moved to history." 1 "Failure is detected and active DTC is stored in the error memory." 0 "Failure is currently not detected." ;
VAL_ 1143 ESP_MTO_Failure_Status 3 "Reserved" 2 "Failure healed aging in progress" 1 "Failrue detected DTC in memory" 0 "Failure is not detected" ;
VAL_ 1143 SRS_MTO_Failure_Status 3 "Reserved" 2 "Failure healed aging in progress" 1 "Failure detected DTC in Memory" 0 "Failure is not detected" ;
VAL_ 1143 PEPS_MTO_Failure_Status 3 "Reserved" 2 "Failure healed aging in progress" 1 "Failure detected DTC in Memory" 0 "Failure is not detected" ;
VAL_ 1143 PEPS_Invalid_failure_status 3 "Reserved" 2 "Failure healed Ageing in progress" 1 "Failure matured & DTC in memory" 0 "Failure is not detected" ;
VAL_ 1143 IPcMToFailureStatus 3 "Reserved" 2 "Failure healed Ageing in progress" 1 "Failure matured & DTC in memory" 0 "Failure is not detected" ;
VAL_ 1143 IPcInvalidFailureStatus 3 "Reserved" 2 "Failure healed Ageing in progress" 1 "Failure matured & DTC in memory" 0 "Failure is not detected" ;
VAL_ 1143 ESClMToFailureStatus 3 "Reserved" 2 "Failure healed Ageing in progress" 1 "Failure matured & DTC in memory" 0 "Failure is not detected" ;
VAL_ 1143 EPAS_MTO_Failure_Status 3 "Reserved" 2 "Failure healed aging in progress" 1 "Failrue detected DTC in mem" 0 "Failure is not detected" ;
VAL_ 1143 EPAS_Invalid_Failure_Status 3 "Reserved" 2 "Failure healed aging in progress" 1 "Failrue detected DTC in mem" 0 "Failure is not detected" ;
VAL_ 1143 CCM_MTO_Failure_Status 3 "Reserved" 2 "Failure healed & Ageing in progress" 1 "failure is detected & DTC in memeory" 0 "Failure is not detected" ;
VAL_ 1143 CCM_Invalid_Failure_Status 3 "Reserved" 2 "Failure healed Ageing in progress" 1 "Failure matured & DTC in memory" 0 "Failure is not detected" ;
VAL_ 1143 BCmMToFailureStatus 3 "Reserved" 2 "Failure healed aging in progress" 1 "Failure detected; DTC in memory" 0 "Failrue is not detected" ;
VAL_ 1143 BCmInvalidFailureStatus 3 "Reserved" 2 "Failure healed Ageing in progress" 1 "Failure matured & DTC in memory" 0 "Failure is not detected" ;
VAL_ 1143 Telematics_EP_Failure_Status 3 "Reserved" 2 "Failurehealed Ageing in progress" 1 "Failure matured & DTC in memory" 0 "Faiulure is not detected " ;
VAL_ 1143 Telematics_BO_Failure_Status 3 "Reserved" 2 "Failurehealed Ageing in progress" 1 "Failure matured & DTC in memory" 0 "Faiulure is not detected " ;
VAL_ 1143 VCUInvalidFailureStatus 3 "Reserved" 2 "Failure healed aging in progress" 1 "Failure matured & DTC in memory" 0 "Failure is not detected" ;
VAL_ 1143 VCUMToFailureStatus 3 "Reserved" 2 "Failure healed aging in progress" 1 "Failure matured & DTC in memory" 0 "Failure is not detected" ;
